VERSION ""

NS_ :

BS_:

BU_: LCU FRLCM FLLCM RghtRrLCMB RghtRrLCMA LftRrLCMB LftRrLCMA RghtFrntLCMB LftFrntLCMB TestTool AFL_AHL LftFrntLCMA RghtFrntLCMA
VAL_TABLE_ ALS_RghtALSCmdSts 2 "normal run" 1 "referece run" 0 "invalid" ;
VAL_TABLE_ LCU_LftALSCmdSts 2 "normal run" 1 "referece run" 0 "invalid" ;
VAL_TABLE_ WelShwSts 2 "welcome mode 2" 1 "welcome mode 1" 0 "no show" ;
VAL_TABLE_ LightShwSts 3 "light show mode 3" 2 "light show mode 2" 1 "light show mode 1" 0 "no show" ;
VAL_TABLE_ GFAVity 1 "present" 0 "not present" ;

BO_ 3221225472 VECTOR__INDEPENDENT_SIG_MSG: 0 Vector__XXX
 SG_ LftRCPlLed064 : 0|8@0+ (1,0) [0|0] "" Vector__XXX
 SG_ LftRCPlLed063 : 0|8@0+ (1,0) [0|0] "" Vector__XXX
 SG_ LftRCPlLed062 : 0|8@0+ (1,0) [0|0] "" Vector__XXX
 SG_ LftRCPlLed061 : 0|8@0+ (1,0) [0|0] "" Vector__XXX
 SG_ LftRCPlLed060 : 0|8@0+ (1,0) [0|0] "" Vector__XXX
 SG_ LftRCPlLed059 : 0|8@0+ (1,0) [0|0] "" Vector__XXX
 SG_ LftRCPlLed058 : 0|8@0+ (1,0) [0|0] "" Vector__XXX
 SG_ LftRCPlLed057 : 0|8@0+ (1,0) [0|0] "" Vector__XXX
 SG_ LftRCPlLed056 : 0|8@0+ (1,0) [0|0] "" Vector__XXX
 SG_ LftRCPlLed055 : 0|8@0+ (1,0) [0|0] "" Vector__XXX
 SG_ LftRCPlLed054 : 0|8@0+ (1,0) [0|0] "" Vector__XXX
 SG_ LftRCPlLed053 : 0|8@0+ (1,0) [0|0] "" Vector__XXX
 SG_ LftRCPlLed052 : 0|8@0+ (1,0) [0|0] "" Vector__XXX
 SG_ LftRCPlLed051 : 0|8@0+ (1,0) [0|0] "" Vector__XXX
 SG_ LftRCPlLed050 : 0|8@0+ (1,0) [0|0] "" Vector__XXX
 SG_ LftRCPlLed049 : 0|8@0+ (1,0) [0|0] "" Vector__XXX
 SG_ RghtRCPlLed033 : 0|8@0+ (1,0) [0|0] "" Vector__XXX
 SG_ RghtRCPlLed063 : 0|8@0+ (1,0) [0|0] "" Vector__XXX
 SG_ RghtRCPlLed061 : 0|8@0+ (1,0) [0|0] "" Vector__XXX
 SG_ RghtRCPlLed062 : 0|8@0+ (1,0) [0|0] "" Vector__XXX
 SG_ RghtRCPlLed060 : 0|8@0+ (1,0) [0|0] "" Vector__XXX
 SG_ RghtRCPlLed059 : 0|8@0+ (1,0) [0|0] "" Vector__XXX
 SG_ RghtRCPlLed057 : 0|8@0+ (1,0) [0|0] "" Vector__XXX
 SG_ RghtRCPlLed056 : 0|8@0+ (1,0) [0|0] "" Vector__XXX
 SG_ RghtRCPlLed055 : 0|8@0+ (1,0) [0|0] "" Vector__XXX
 SG_ RghtRCPlLed054 : 0|8@0+ (1,0) [0|0] "" Vector__XXX
 SG_ RghtRCPlLed053 : 0|8@0+ (1,0) [0|0] "" Vector__XXX
 SG_ RghtRCPlLed052 : 0|8@0+ (1,0) [0|0] "" Vector__XXX
 SG_ RghtRCPlLed051 : 0|8@0+ (1,0) [0|0] "" Vector__XXX
 SG_ RghtRCPlLed050 : 0|8@0+ (1,0) [0|0] "" Vector__XXX
 SG_ RghtRCPlLed049 : 0|8@0+ (1,0) [0|0] "" Vector__XXX
 SG_ RghtRCPlLed048 : 0|8@0+ (1,0) [0|0] "" Vector__XXX
 SG_ RghtRCPlLed046 : 0|8@0+ (1,0) [0|0] "" Vector__XXX
 SG_ RghtRCPlLed045 : 0|8@0+ (1,0) [0|0] "" Vector__XXX
 SG_ RghtRCPlLed044 : 0|8@0+ (1,0) [0|0] "" Vector__XXX
 SG_ RghtRCPlLed043 : 0|8@0+ (1,0) [0|0] "" Vector__XXX
 SG_ RghtRCPlLed042 : 0|8@0+ (1,0) [0|0] "" Vector__XXX
 SG_ RghtRCPlLed041 : 0|8@0+ (1,0) [0|0] "" Vector__XXX
 SG_ RghtRCPlLed040 : 0|8@0+ (1,0) [0|0] "" Vector__XXX
 SG_ RghtRCPlLed039 : 0|8@0+ (1,0) [0|0] "" Vector__XXX
 SG_ RghtRCPlLed038 : 0|8@0+ (1,0) [0|0] "" Vector__XXX
 SG_ RghtRCPlLed037 : 0|8@0+ (1,0) [0|0] "" Vector__XXX
 SG_ RghtRCPlLed035 : 0|8@0+ (1,0) [0|0] "" Vector__XXX
 SG_ RghtRCPlLed034 : 0|8@0+ (1,0) [0|0] "" Vector__XXX
 SG_ RghtRCPlLed032 : 0|8@0+ (1,0) [0|0] "" Vector__XXX
 SG_ RghtRCPlLed031 : 0|8@0+ (1,0) [0|0] "" Vector__XXX
 SG_ RghtRCPlLed030 : 0|8@0+ (1,0) [0|0] "" Vector__XXX
 SG_ RghtRCPlLed029 : 0|8@0+ (1,0) [0|0] "" Vector__XXX
 SG_ RghtRCPlLed028 : 0|8@0+ (1,0) [0|0] "" Vector__XXX
 SG_ RghtRCPlLed027 : 0|8@0+ (1,0) [0|0] "" Vector__XXX
 SG_ RghtRCPlLed026 : 0|8@0+ (1,0) [0|0] "" Vector__XXX
 SG_ RghtRCPlLed025 : 0|8@0+ (1,0) [0|0] "" Vector__XXX
 SG_ RghtRCPlLed023 : 0|8@0+ (1,0) [0|0] "" Vector__XXX
 SG_ RghtRCPlLed022 : 0|8@0+ (1,0) [0|0] "" Vector__XXX
 SG_ RghtRCPlLed021 : 0|8@0+ (1,0) [0|0] "" Vector__XXX
 SG_ RghtRCPlLed020 : 0|8@0+ (1,0) [0|0] "" Vector__XXX
 SG_ RghtRCPlLed019 : 0|8@0+ (1,0) [0|0] "" Vector__XXX
 SG_ RghtRCPlLed018 : 0|8@0+ (1,0) [0|0] "" Vector__XXX
 SG_ RghtRCPlLed017 : 0|8@0+ (1,0) [0|0] "" Vector__XXX
 SG_ RghtRCPlLed016 : 0|8@0+ (1,0) [0|0] "" Vector__XXX
 SG_ RghtRCPlLed015 : 0|8@0+ (1,0) [0|0] "" Vector__XXX
 SG_ RghtRCPlLed014 : 0|8@0+ (1,0) [0|0] "" Vector__XXX
 SG_ RghtRCPlLed012 : 0|8@0+ (1,0) [0|0] "" Vector__XXX
 SG_ RghtRCPlLed011 : 0|8@0+ (1,0) [0|0] "" Vector__XXX
 SG_ RghtRCPlLed010 : 0|8@0+ (1,0) [0|0] "" Vector__XXX
 SG_ RghtRCPlLed009 : 0|8@0+ (1,0) [0|0] "" Vector__XXX
 SG_ RghtRCPlLed008 : 0|8@0+ (1,0) [0|0] "" Vector__XXX
 SG_ RghtRCPlLed007 : 0|8@0+ (1,0) [0|0] "" Vector__XXX
 SG_ RghtRCPlLed006 : 0|8@0+ (1,0) [0|0] "" Vector__XXX
 SG_ RghtRCPlLed005 : 0|8@0+ (1,0) [0|0] "" Vector__XXX
 SG_ RghtRCPlLed004 : 0|8@0+ (1,0) [0|0] "" Vector__XXX
 SG_ RghtRCPlLed003 : 0|8@0+ (1,0) [0|0] "" Vector__XXX
 SG_ RghtRCPlLed064 : 0|8@0+ (1,0) [0|0] "" Vector__XXX
 SG_ RghtRCPlLed058 : 0|8@0+ (1,0) [0|0] "" Vector__XXX
 SG_ RghtRCPlLed047 : 0|8@0+ (1,0) [0|0] "" Vector__XXX
 SG_ RghtRCPlLed036 : 0|8@0+ (1,0) [0|0] "" Vector__XXX
 SG_ RghtRCPlLed024 : 0|8@0+ (1,0) [0|0] "" Vector__XXX
 SG_ RghtRCPlLed013 : 0|8@0+ (1,0) [0|0] "" Vector__XXX
 SG_ RghtRCPlLed002 : 0|8@0+ (1,0) [0|0] "" Vector__XXX
 SG_ RghtRCPlLed001 : 0|8@0+ (1,0) [0|0] "" Vector__XXX
 SG_ DiagRsp_RRLCMB : 0|64@0+ (1,0) [0|0] "" Vector__XXX
 SG_ DiagRsp_FRLCMB : 0|64@0+ (1,0) [0|0] "" Vector__XXX
 SG_ DiagRsp_FLLCMB : 0|64@0+ (1,0) [0|0] "" Vector__XXX
 SG_ DiagPhyReq_RRLCMB : 0|64@0+ (1,0) [0|1.84467440737096E+019] "" Vector__XXX
 SG_ DiagPhyReq_FRLCMB : 0|64@0+ (1,0) [0|1.84467440737096E+019] "" Vector__XXX
 SG_ DiagPhyReq_FLLCMB : 0|64@0+ (1,0) [0|1.84467440737096E+019] "" Vector__XXX
 SG_ NMData_RRLCMB : 0|64@0+ (1,0) [0|0] "" Vector__XXX
 SG_ NMData_FRLCMB : 0|64@0+ (1,0) [0|0] "" Vector__XXX
 SG_ NMData_FLLCMB : 0|64@0+ (1,0) [0|0] "" Vector__XXX
 SG_ LftRPlLed056 : 0|8@0+ (1,0) [0|0] "" Vector__XXX
 SG_ LftRPlLed055 : 0|8@0+ (1,0) [0|0] "" Vector__XXX
 SG_ LftRPlLed054 : 0|8@0+ (1,0) [0|0] "" Vector__XXX
 SG_ LftRPlLed053 : 0|8@0+ (1,0) [0|0] "" Vector__XXX
 SG_ LftRPlLed052 : 0|8@0+ (1,0) [0|0] "" Vector__XXX
 SG_ LftRPlLed051 : 0|8@0+ (1,0) [0|0] "" Vector__XXX
 SG_ LftRPlLed050 : 0|8@0+ (1,0) [0|0] "" Vector__XXX
 SG_ LftRPlLed049 : 0|8@0+ (1,0) [0|0] "" Vector__XXX
 SG_ LftRPlLed048 : 0|8@0+ (1,0) [0|0] "" Vector__XXX
 SG_ LftRPlLed047 : 0|8@0+ (1,0) [0|0] "" Vector__XXX
 SG_ LftRPlLed046 : 0|8@0+ (1,0) [0|0] "" Vector__XXX
 SG_ LftRPlLed045 : 0|8@0+ (1,0) [0|0] "" Vector__XXX
 SG_ LftRPlLed044 : 0|8@0+ (1,0) [0|0] "" Vector__XXX
 SG_ LftRPlLed043 : 0|8@0+ (1,0) [0|0] "" Vector__XXX
 SG_ LftRPlLed042 : 0|8@0+ (1,0) [0|0] "" Vector__XXX
 SG_ LftRPlLed041 : 0|8@0+ (1,0) [0|0] "" Vector__XXX
 SG_ LftRPlLed040 : 0|8@0+ (1,0) [0|0] "" Vector__XXX
 SG_ LftRPlLed039 : 0|8@0+ (1,0) [0|0] "" Vector__XXX
 SG_ LftRPlLed038 : 0|8@0+ (1,0) [0|0] "" Vector__XXX
 SG_ LftRPlLed037 : 0|8@0+ (1,0) [0|0] "" Vector__XXX
 SG_ LftRPlLed036 : 0|8@0+ (1,0) [0|0] "" Vector__XXX
 SG_ LftRPlLed035 : 0|8@0+ (1,0) [0|0] "" Vector__XXX
 SG_ LftRPlLed034 : 0|8@0+ (1,0) [0|0] "" Vector__XXX
 SG_ LftRPlLed033 : 0|8@0+ (1,0) [0|0] "" Vector__XXX
 SG_ RghtRPlLed064 : 0|8@0+ (1,0) [0|0] "" Vector__XXX
 SG_ RghtRPlLed063 : 0|8@0+ (1,0) [0|0] "" Vector__XXX
 SG_ RghtRPlLed062 : 0|8@0+ (1,0) [0|0] "" Vector__XXX
 SG_ RghtRPlLed061 : 0|8@0+ (1,0) [0|0] "" Vector__XXX
 SG_ RghtRPlLed060 : 0|8@0+ (1,0) [0|0] "" Vector__XXX
 SG_ RghtRPlLed059 : 0|8@0+ (1,0) [0|0] "" Vector__XXX
 SG_ RghtRPlLed058 : 0|8@0+ (1,0) [0|0] "" Vector__XXX
 SG_ RghtRPlLed057 : 0|8@0+ (1,0) [0|0] "" Vector__XXX
 SG_ RghtRPlLed056 : 0|8@0+ (1,0) [0|0] "" Vector__XXX
 SG_ RghtRPlLed055 : 0|8@0+ (1,0) [0|0] "" Vector__XXX
 SG_ RghtRPlLed054 : 0|8@0+ (1,0) [0|0] "" Vector__XXX
 SG_ RghtRPlLed053 : 0|8@0+ (1,0) [0|0] "" Vector__XXX
 SG_ RghtRPlLed052 : 0|8@0+ (1,0) [0|0] "" Vector__XXX
 SG_ RghtRPlLed051 : 0|8@0+ (1,0) [0|0] "" Vector__XXX
 SG_ RghtRPlLed050 : 0|8@0+ (1,0) [0|0] "" Vector__XXX
 SG_ RghtRPlLed049 : 0|8@0+ (1,0) [0|0] "" Vector__XXX
 SG_ RghtRPlLed048 : 0|8@0+ (1,0) [0|0] "" Vector__XXX
 SG_ RghtRPlLed047 : 0|8@0+ (1,0) [0|0] "" Vector__XXX
 SG_ RghtRPlLed046 : 0|8@0+ (1,0) [0|0] "" Vector__XXX
 SG_ RghtRPlLed045 : 0|8@0+ (1,0) [0|0] "" Vector__XXX
 SG_ RghtRPlLed044 : 0|8@0+ (1,0) [0|0] "" Vector__XXX
 SG_ RghtRPlLed043 : 0|8@0+ (1,0) [0|0] "" Vector__XXX
 SG_ RghtRPlLed042 : 0|8@0+ (1,0) [0|0] "" Vector__XXX
 SG_ RghtRPlLed041 : 0|8@0+ (1,0) [0|0] "" Vector__XXX
 SG_ RghtRPlLed040 : 0|8@0+ (1,0) [0|0] "" Vector__XXX
 SG_ RghtRPlLed039 : 0|8@0+ (1,0) [0|0] "" Vector__XXX
 SG_ RghtRPlLed038 : 0|8@0+ (1,0) [0|0] "" Vector__XXX
 SG_ RghtRPlLed037 : 0|8@0+ (1,0) [0|0] "" Vector__XXX
 SG_ RghtRPlLed036 : 0|8@0+ (1,0) [0|0] "" Vector__XXX
 SG_ RghtRPlLed035 : 0|8@0+ (1,0) [0|0] "" Vector__XXX
 SG_ RghtRPlLed034 : 0|8@0+ (1,0) [0|0] "" Vector__XXX
 SG_ RghtRPlLed033 : 0|8@0+ (1,0) [0|0] "" Vector__XXX
 SG_ LftRPlLed064 : 0|8@0+ (1,0) [0|0] "" Vector__XXX
 SG_ LftRPlLed063 : 0|8@0+ (1,0) [0|0] "" Vector__XXX
 SG_ LftRPlLed062 : 0|8@0+ (1,0) [0|0] "" Vector__XXX
 SG_ LftRPlLed061 : 0|8@0+ (1,0) [0|0] "" Vector__XXX
 SG_ LftRPlLed060 : 0|8@0+ (1,0) [0|0] "" Vector__XXX
 SG_ LftRPlLed059 : 0|8@0+ (1,0) [0|0] "" Vector__XXX
 SG_ LftRPlLed058 : 0|8@0+ (1,0) [0|0] "" Vector__XXX
 SG_ LftRPlLed057 : 0|8@0+ (1,0) [0|0] "" Vector__XXX
 SG_ RghtFCPlLed040 : 0|8@0+ (1,0) [0|0] "" Vector__XXX
 SG_ RghtFCPlLed039 : 0|8@0+ (1,0) [0|0] "" Vector__XXX
 SG_ RghtFCPlLed038 : 0|8@0+ (1,0) [0|0] "" Vector__XXX
 SG_ RghtFCPlLed037 : 0|8@0+ (1,0) [0|0] "" Vector__XXX
 SG_ RghtFCPlLed036 : 0|8@0+ (1,0) [0|0] "" Vector__XXX
 SG_ RghtFCPlLed035 : 0|8@0+ (1,0) [0|0] "" Vector__XXX
 SG_ RghtFCPlLed034 : 0|8@0+ (1,0) [0|0] "" Vector__XXX
 SG_ RghtFCPlLed033 : 0|8@0+ (1,0) [0|0] "" Vector__XXX
 SG_ RghtFCPlLed008 : 0|8@0+ (1,0) [0|0] "" Vector__XXX
 SG_ RghtFCPlLed007 : 0|8@0+ (1,0) [0|0] "" Vector__XXX
 SG_ RghtFCPlLed006 : 0|8@0+ (1,0) [0|0] "" Vector__XXX
 SG_ RghtFCPlLed005 : 0|8@0+ (1,0) [0|0] "" Vector__XXX
 SG_ RghtFCPlLed004 : 0|8@0+ (1,0) [0|0] "" Vector__XXX
 SG_ RghtFCPlLed003 : 0|8@0+ (1,0) [0|0] "" Vector__XXX
 SG_ RghtFCPlLed002 : 0|8@0+ (1,0) [0|0] "" Vector__XXX
 SG_ RghtFCPlLed001 : 0|8@0+ (1,0) [0|0] "" Vector__XXX
 SG_ LftFCPlLed040 : 0|8@0+ (1,0) [0|0] "" Vector__XXX
 SG_ LftFCPlLed039 : 0|8@0+ (1,0) [0|0] "" Vector__XXX
 SG_ LftFCPlLed038 : 0|8@0+ (1,0) [0|0] "" Vector__XXX
 SG_ LftFCPlLed037 : 0|8@0+ (1,0) [0|0] "" Vector__XXX
 SG_ LftFCPlLed036 : 0|8@0+ (1,0) [0|0] "" Vector__XXX
 SG_ LftFCPlLed035 : 0|8@0+ (1,0) [0|0] "" Vector__XXX
 SG_ LftFCPlLed034 : 0|8@0+ (1,0) [0|0] "" Vector__XXX
 SG_ LftFCPlLed033 : 0|8@0+ (1,0) [0|0] "" Vector__XXX
 SG_ LftFCPlLed024 : 0|8@0+ (1,0) [0|0] "" Vector__XXX
 SG_ LftFCPlLed023 : 0|8@0+ (1,0) [0|0] "" Vector__XXX
 SG_ LftFCPlLed022 : 0|8@0+ (1,0) [0|0] "" Vector__XXX
 SG_ LftFCPlLed021 : 0|8@0+ (1,0) [0|0] "" Vector__XXX
 SG_ LftFCPlLed020 : 0|8@0+ (1,0) [0|0] "" Vector__XXX
 SG_ LftFCPlLed019 : 0|8@0+ (1,0) [0|0] "" Vector__XXX
 SG_ LftFCPlLed018 : 0|8@0+ (1,0) [0|0] "" Vector__XXX
 SG_ LftFCPlLed017 : 0|8@0+ (1,0) [0|0] "" Vector__XXX
 SG_ RghtRTrnLed040 : 0|8@0+ (1,0) [0|0] "" Vector__XXX
 SG_ RghtRTrnLed039 : 0|8@0+ (1,0) [0|0] "" Vector__XXX
 SG_ RghtRTrnLed038 : 0|8@0+ (1,0) [0|0] "" Vector__XXX
 SG_ RghtRTrnLed037 : 0|8@0+ (1,0) [0|0] "" Vector__XXX
 SG_ RghtRTrnLed036 : 0|8@0+ (1,0) [0|0] "" Vector__XXX
 SG_ RghtRTrnLed035 : 0|8@0+ (1,0) [0|0] "" Vector__XXX
 SG_ RghtRTrnLed034 : 0|8@0+ (1,0) [0|0] "" Vector__XXX
 SG_ RghtRTrnLed033 : 0|8@0+ (1,0) [0|0] "" Vector__XXX
 SG_ LftRTrnLed040 : 0|8@0+ (1,0) [0|0] "" Vector__XXX
 SG_ LftRTrnLed039 : 0|8@0+ (1,0) [0|0] "" Vector__XXX
 SG_ LftRTrnLed038 : 0|8@0+ (1,0) [0|0] "" Vector__XXX
 SG_ LftRTrnLed037 : 0|8@0+ (1,0) [0|0] "" Vector__XXX
 SG_ LftRTrnLed036 : 0|8@0+ (1,0) [0|0] "" Vector__XXX
 SG_ LftRTrnLed035 : 0|8@0+ (1,0) [0|0] "" Vector__XXX
 SG_ LftRTrnLed034 : 0|8@0+ (1,0) [0|0] "" Vector__XXX
 SG_ LftRTrnLed033 : 0|8@0+ (1,0) [0|0] "" Vector__XXX
 SG_ RghtFTrnLed024 : 0|8@0+ (1,0) [0|0] "" Vector__XXX
 SG_ RghtFTrnLed023 : 0|8@0+ (1,0) [0|0] "" Vector__XXX
 SG_ RghtFTrnLed022 : 0|8@0+ (1,0) [0|0] "" Vector__XXX
 SG_ RghtFTrnLed021 : 0|8@0+ (1,0) [0|0] "" Vector__XXX
 SG_ RghtFTrnLed020 : 0|8@0+ (1,0) [0|0] "" Vector__XXX
 SG_ RghtFTrnLed019 : 0|8@0+ (1,0) [0|0] "" Vector__XXX
 SG_ RghtFTrnLed018 : 0|8@0+ (1,0) [0|0] "" Vector__XXX
 SG_ RghtFTrnLed017 : 0|8@0+ (1,0) [0|0] "" Vector__XXX
 SG_ LftFTrnLed024 : 0|8@0+ (1,0) [0|0] "" Vector__XXX
 SG_ LftFTrnLed023 : 0|8@0+ (1,0) [0|0] "" Vector__XXX
 SG_ LftFTrnLed022 : 0|8@0+ (1,0) [0|0] "" Vector__XXX
 SG_ LftFTrnLed021 : 0|8@0+ (1,0) [0|0] "" Vector__XXX
 SG_ LftFTrnLed020 : 0|8@0+ (1,0) [0|0] "" Vector__XXX
 SG_ LftFTrnLed019 : 0|8@0+ (1,0) [0|0] "" Vector__XXX
 SG_ LftFTrnLed018 : 0|8@0+ (1,0) [0|0] "" Vector__XXX
 SG_ LftFTrnLed017 : 0|8@0+ (1,0) [0|0] "" Vector__XXX
 SG_ RghtFCPlLed032 : 0|8@0+ (1,0) [0|0] "" Vector__XXX
 SG_ RghtFCPlLed031 : 0|8@0+ (1,0) [0|0] "" Vector__XXX
 SG_ RghtFCPlLed030 : 0|8@0+ (1,0) [0|0] "" Vector__XXX
 SG_ RghtFCPlLed029 : 0|8@0+ (1,0) [0|0] "" Vector__XXX
 SG_ RghtFCPlLed028 : 0|8@0+ (1,0) [0|0] "" Vector__XXX
 SG_ RghtFCPlLed027 : 0|8@0+ (1,0) [0|0] "" Vector__XXX
 SG_ RghtFCPlLed026 : 0|8@0+ (1,0) [0|0] "" Vector__XXX
 SG_ RghtFCPlLed025 : 0|8@0+ (1,0) [0|0] "" Vector__XXX
 SG_ RghtFCPlLed024 : 0|8@0+ (1,0) [0|0] "" Vector__XXX
 SG_ RghtFCPlLed023 : 0|8@0+ (1,0) [0|0] "" Vector__XXX
 SG_ RghtFCPlLed022 : 0|8@0+ (1,0) [0|0] "" Vector__XXX
 SG_ RghtFCPlLed021 : 0|8@0+ (1,0) [0|0] "" Vector__XXX
 SG_ RghtFCPlLed020 : 0|8@0+ (1,0) [0|0] "" Vector__XXX
 SG_ RghtFCPlLed019 : 0|8@0+ (1,0) [0|0] "" Vector__XXX
 SG_ RghtFCPlLed018 : 0|8@0+ (1,0) [0|0] "" Vector__XXX
 SG_ RghtFCPlLed017 : 0|8@0+ (1,0) [0|0] "" Vector__XXX
 SG_ RghtFCPlLed016 : 0|8@0+ (1,0) [0|0] "" Vector__XXX
 SG_ RghtFCPlLed015 : 0|8@0+ (1,0) [0|0] "" Vector__XXX
 SG_ RghtFCPlLed014 : 0|8@0+ (1,0) [0|0] "" Vector__XXX
 SG_ RghtFCPlLed013 : 0|8@0+ (1,0) [0|0] "" Vector__XXX
 SG_ RghtFCPlLed012 : 0|8@0+ (1,0) [0|0] "" Vector__XXX
 SG_ RghtFCPlLed011 : 0|8@0+ (1,0) [0|0] "" Vector__XXX
 SG_ RghtFCPlLed010 : 0|8@0+ (1,0) [0|0] "" Vector__XXX
 SG_ RghtFCPlLed009 : 0|8@0+ (1,0) [0|0] "" Vector__XXX
 SG_ LftFCPlLed032 : 0|8@0+ (1,0) [0|0] "" Vector__XXX
 SG_ LftFCPlLed031 : 0|8@0+ (1,0) [0|0] "" Vector__XXX
 SG_ LftFCPlLed030 : 0|8@0+ (1,0) [0|0] "" Vector__XXX
 SG_ LftFCPlLed029 : 0|8@0+ (1,0) [0|0] "" Vector__XXX
 SG_ LftFCPlLed028 : 0|8@0+ (1,0) [0|0] "" Vector__XXX
 SG_ LftFCPlLed027 : 0|8@0+ (1,0) [0|0] "" Vector__XXX
 SG_ LftFCPlLed026 : 0|8@0+ (1,0) [0|0] "" Vector__XXX
 SG_ LftFCPlLed025 : 0|8@0+ (1,0) [0|0] "" Vector__XXX
 SG_ LftHbLed024 : 0|8@0+ (1,0) [0|0] "" Vector__XXX
 SG_ LftHbLed023 : 0|8@0+ (1,0) [0|0] "" Vector__XXX
 SG_ LftHbLed022 : 0|8@0+ (1,0) [0|0] "" Vector__XXX
 SG_ LftHbLed021 : 0|8@0+ (1,0) [0|0] "" Vector__XXX
 SG_ LftHbLed020 : 0|8@0+ (1,0) [0|0] "" Vector__XXX
 SG_ LftHbLed019 : 0|8@0+ (1,0) [0|0] "" Vector__XXX
 SG_ LftHbLed018 : 0|8@0+ (1,0) [0|0] "" Vector__XXX
 SG_ LftHbLed017 : 0|8@0+ (1,0) [0|0] "" Vector__XXX
 SG_ RghtHbLed024 : 0|8@0+ (1,0) [0|0] "" Vector__XXX
 SG_ RghtHbLed023 : 0|8@0+ (1,0) [0|0] "" Vector__XXX
 SG_ RghtHbLed022 : 0|8@0+ (1,0) [0|0] "" Vector__XXX
 SG_ RghtHbLed021 : 0|8@0+ (1,0) [0|0] "" Vector__XXX
 SG_ RghtHbLed020 : 0|8@0+ (1,0) [0|0] "" Vector__XXX
 SG_ RghtHbLed019 : 0|8@0+ (1,0) [0|0] "" Vector__XXX
 SG_ RghtHbLed018 : 0|8@0+ (1,0) [0|0] "" Vector__XXX
 SG_ RghtHbLed017 : 0|8@0+ (1,0) [0|0] "" Vector__XXX
 SG_ LftFTrnLed016 : 0|8@0+ (1,0) [0|0] "" Vector__XXX
 SG_ LftFTrnLed015 : 0|8@0+ (1,0) [0|0] "" Vector__XXX
 SG_ LftFTrnLed014 : 0|8@0+ (1,0) [0|0] "" Vector__XXX
 SG_ LftFTrnLed013 : 0|8@0+ (1,0) [0|0] "" Vector__XXX
 SG_ LftFTrnLed012 : 0|8@0+ (1,0) [0|0] "" Vector__XXX
 SG_ LftFTrnLed011 : 0|8@0+ (1,0) [0|0] "" Vector__XXX
 SG_ LftFTrnLed010 : 0|8@0+ (1,0) [0|0] "" Vector__XXX
 SG_ LftFTrnLed009 : 0|8@0+ (1,0) [0|0] "" Vector__XXX
 SG_ RghtFTrnLed016 : 0|8@0+ (1,0) [0|0] "" Vector__XXX
 SG_ RghtFTrnLed015 : 0|8@0+ (1,0) [0|0] "" Vector__XXX
 SG_ RghtFTrnLed014 : 0|8@0+ (1,0) [0|0] "" Vector__XXX
 SG_ RghtFTrnLed013 : 0|8@0+ (1,0) [0|0] "" Vector__XXX
 SG_ RghtFTrnLed012 : 0|8@0+ (1,0) [0|0] "" Vector__XXX
 SG_ RghtFTrnLed011 : 0|8@0+ (1,0) [0|0] "" Vector__XXX
 SG_ RghtFTrnLed010 : 0|8@0+ (1,0) [0|0] "" Vector__XXX
 SG_ RghtFTrnLed009 : 0|8@0+ (1,0) [0|0] "" Vector__XXX
 SG_ LftFCPlLed008 : 0|8@0+ (1,0) [0|0] "" Vector__XXX
 SG_ LftFCPlLed007 : 0|8@0+ (1,0) [0|0] "" Vector__XXX
 SG_ LftFCPlLed006 : 0|8@0+ (1,0) [0|0] "" Vector__XXX
 SG_ LftFCPlLed005 : 0|8@0+ (1,0) [0|0] "" Vector__XXX
 SG_ LftFCPlLed004 : 0|8@0+ (1,0) [0|0] "" Vector__XXX
 SG_ LftFCPlLed003 : 0|8@0+ (1,0) [0|0] "" Vector__XXX
 SG_ LftFCPlLed002 : 0|8@0+ (1,0) [0|0] "" Vector__XXX
 SG_ LftFCPlLed001 : 0|8@0+ (1,0) [0|0] "" Vector__XXX
 SG_ LftFCPlLed016 : 0|8@0+ (1,0) [0|0] "" Vector__XXX
 SG_ LftFCPlLed015 : 0|8@0+ (1,0) [0|0] "" Vector__XXX
 SG_ LftFCPlLed014 : 0|8@0+ (1,0) [0|0] "" Vector__XXX
 SG_ LftFCPlLed013 : 0|8@0+ (1,0) [0|0] "" Vector__XXX
 SG_ LftFCPlLed012 : 0|8@0+ (1,0) [0|0] "" Vector__XXX
 SG_ LftFCPlLed011 : 0|8@0+ (1,0) [0|0] "" Vector__XXX
 SG_ LftFCPlLed010 : 0|8@0+ (1,0) [0|0] "" Vector__XXX
 SG_ LftFCPlLed009 : 0|8@0+ (1,0) [0|0] "" Vector__XXX
 SG_ RghtFTrnLed008 : 0|8@0+ (1,0) [0|0] "" Vector__XXX
 SG_ RghtFTrnLed007 : 0|8@0+ (1,0) [0|0] "" Vector__XXX
 SG_ RghtFTrnLed006 : 0|8@0+ (1,0) [0|0] "" Vector__XXX
 SG_ RghtFTrnLed005 : 0|8@0+ (1,0) [0|0] "" Vector__XXX
 SG_ RghtFTrnLed004 : 0|8@0+ (1,0) [0|0] "" Vector__XXX
 SG_ RghtFTrnLed003 : 0|8@0+ (1,0) [0|0] "" Vector__XXX
 SG_ RghtDrlLed056 : 0|8@0+ (1,0) [0|0] "" Vector__XXX
 SG_ RghtDrlLed055 : 0|8@0+ (1,0) [0|0] "" Vector__XXX
 SG_ RghtDrlLed054 : 0|8@0+ (1,0) [0|0] "" Vector__XXX
 SG_ RghtDrlLed053 : 0|8@0+ (1,0) [0|0] "" Vector__XXX
 SG_ RghtDrlLed052 : 0|8@0+ (1,0) [0|0] "" Vector__XXX
 SG_ RghtDrlLed051 : 0|8@0+ (1,0) [0|0] "" Vector__XXX
 SG_ RghtDhlSts : 0|2@0+ (1,0) [0|1] "" Vector__XXX
 SG_ RghtDhlPosAct : 0|10@0+ (1,0) [0|0] "" Vector__XXX
 SG_ LampErr_FRLCMA : 0|16@0+ (1,0) [0|0] "" Vector__XXX
 SG_ LftDhlSts : 0|2@0+ (1,0) [0|1] "" Vector__XXX
 SG_ LftDhlPosAct : 0|10@0+ (1,0) [0|0] "" Vector__XXX
 SG_ LampErr_FLLCMA : 0|16@0+ (1,0) [0|0] "" Vector__XXX
 SG_ SysSts_FLLCMA : 0|64@0+ (1,0) [0|0] "" Vector__XXX
 SG_ EngSt : 0|1@0+ (1,0) [0|0] "" Vector__XXX
 SG_ EngCrankSt : 0|1@0+ (1,0) [0|0] "" Vector__XXX
 SG_ KeySt : 0|2@0+ (1,0) [0|0] "" Vector__XXX
 SG_ LcuCmd_ShwCmd : 0|8@0+ (1,0) [0|0] "" Vector__XXX
 SG_ LcuCmd_LampCmd : 0|24@0+ (1,0) [0|0] "" Vector__XXX

BO_ 3 New_Message_87: 8 Vector__XXX
 SG_ New_Signal_729 : 48|8@1+ (1,0) [0|0] "" Vector__XXX

BO_ 2 New_Message_86: 8 Vector__XXX
 SG_ New_Signal_728 : 56|8@1+ (1,0) [0|0] "" Vector__XXX

BO_ 1 New_Message_85: 8 Vector__XXX
 SG_ New_Signal_727 : 24|8@1+ (1,0) [0|0] "" Vector__XXX

BO_ 0 New_Message_84: 8 Vector__XXX
 SG_ New_Signal_726 : 16|8@1+ (1,0) [0|0] "" Vector__XXX

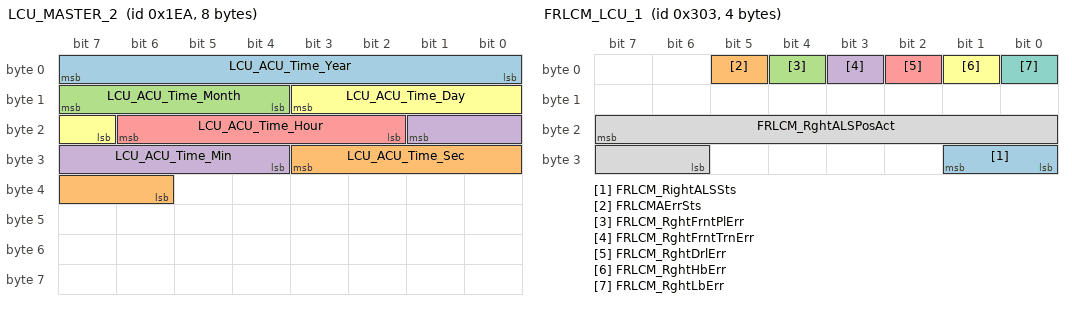
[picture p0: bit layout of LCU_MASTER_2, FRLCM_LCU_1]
BO_ 490 LCU_MASTER_2: 8 AFL_AHL
 SG_ LCU_ACU_Time_Year : 7|8@0+ (1,2000) [2000|2255] ""  RghtRrLCMB,RghtRrLCMA,LftRrLCMA,RghtFrntLCMA,RghtFrntLCMB,LftRrLCMB,LftFrntLCMB,LftFrntLCMA
 SG_ LCU_ACU_Time_Sec : 27|6@0+ (1,0) [0|59] ""  RghtRrLCMB,RghtRrLCMA,LftRrLCMA,RghtFrntLCMA,RghtFrntLCMB,LftRrLCMB,LftFrntLCMB,LftFrntLCMA
 SG_ LCU_ACU_Time_Month : 15|4@0+ (1,0) [1|12] ""  RghtRrLCMB,RghtRrLCMA,LftRrLCMA,RghtFrntLCMA,RghtFrntLCMB,LftRrLCMB,LftFrntLCMB,LftFrntLCMA
 SG_ LCU_ACU_Time_Min : 17|6@0+ (1,0) [0|59] ""  RghtRrLCMB,RghtRrLCMA,LftRrLCMA,RghtFrntLCMA,RghtFrntLCMB,LftRrLCMB,LftFrntLCMB,LftFrntLCMA
 SG_ LCU_ACU_Time_Hour : 22|5@0+ (1,0) [0|23] ""  RghtRrLCMB,RghtRrLCMA,LftRrLCMA,RghtFrntLCMA,RghtFrntLCMB,LftRrLCMB,LftFrntLCMB,LftFrntLCMA
 SG_ LCU_ACU_Time_Day : 11|5@0+ (1,0) [1|31] ""  RghtRrLCMB,RghtRrLCMA,LftRrLCMA,RghtFrntLCMA,RghtFrntLCMB,LftRrLCMB,LftFrntLCMB,LftFrntLCMA

BO_ 1396 Nm_RLLCMB: 8 LftRrLCMB
 SG_ NMData_RLLCMB : 7|64@0+ (1,0) [0|0] ""  AFL_AHL

BO_ 1371 Nm_RRLCMA: 8 RghtRrLCMA
 SG_ NMData_RRLCMA : 7|64@0+ (1,0) [0|0] ""  AFL_AHL

BO_ 1358 Nm_RLLCMA: 8 LftRrLCMA
 SG_ NMData_RLLCMA : 7|64@0+ (1,0) [0|0] ""  AFL_AHL

BO_ 1330 Nm_FRLCMA: 8 RghtFrntLCMA
 SG_ NMData_FRLCMA : 7|64@0+ (1,0) [0|0] ""  AFL_AHL

BO_ 1313 Nm_FLLCMA: 8 LftFrntLCMA
 SG_ NMData_FLLCMA : 7|64@0+ (1,0) [0|0] ""  AFL_AHL

BO_ 1359 Nm_LCU: 8 AFL_AHL
 SG_ NMData_LCU : 7|64@0+ (1,0) [0|0] ""  RghtRrLCMB,RghtRrLCMA,RghtFrntLCMB,LftRrLCMB,LftRrLCMA,LftFrntLCMB,RghtFrntLCMA,LftFrntLCMA

BO_ 776 RRLCMBLampSts: 2 RghtRrLCMB
 SG_ LampErr_RRLCMB : 7|16@0+ (1,0) [0|0] ""  AFL_AHL

BO_ 774 RRLCMALampSts: 2 RghtRrLCMA
 SG_ LampErr_RRLCMA : 7|16@0+ (1,0) [0|0] ""  AFL_AHL

BO_ 775 RLLCMBLampSts: 2 LftRrLCMB
 SG_ LampErr_RLLCMB : 7|16@0+ (1,0) [0|0] ""  AFL_AHL

BO_ 773 RLLCMALampSts: 2 LftRrLCMA
 SG_ LampErr_RLLCMA : 7|16@0+ (1,0) [0|0] ""  AFL_AHL

BO_ 772 FRLCMBLampSts: 2 RghtFrntLCMB
 SG_ LampErr_FRLCMB : 7|16@0+ (1,0) [0|0] ""  AFL_AHL

BO_ 771 FRLCM_LCU_1: 4 RghtFrntLCMA
 SG_ FRLCM_RightALSSts : 25|2@0+ (1,0) [0|3] ""  LCU
 SG_ FRLCMAErrSts : 5|1@0+ (1,0) [0|1] ""  LCU
 SG_ FRLCM_RghtFrntPlErr : 4|1@0+ (1,0) [0|1] ""  LCU
 SG_ FRLCM_RghtFrntTrnErr : 3|1@0+ (1,0) [0|1] ""  LCU
 SG_ FRLCM_RghtDrlErr : 2|1@0+ (1,0) [0|1] ""  LCU
 SG_ FRLCM_RghtHbErr : 1|1@0+ (1,0) [0|1] ""  LCU
 SG_ FRLCM_RghtLbErr : 0|1@0+ (1,0) [0|1] ""  LCU
 SG_ FRLCM_RghtALSPosAct : 23|10@0+ (1,0) [0|1024] ""  LCU

BO_ 770 FLLCMBLampSts: 2 LftFrntLCMB
 SG_ LampErr_FLLCMB : 7|16@0+ (1,0) [0|0] ""  AFL_AHL

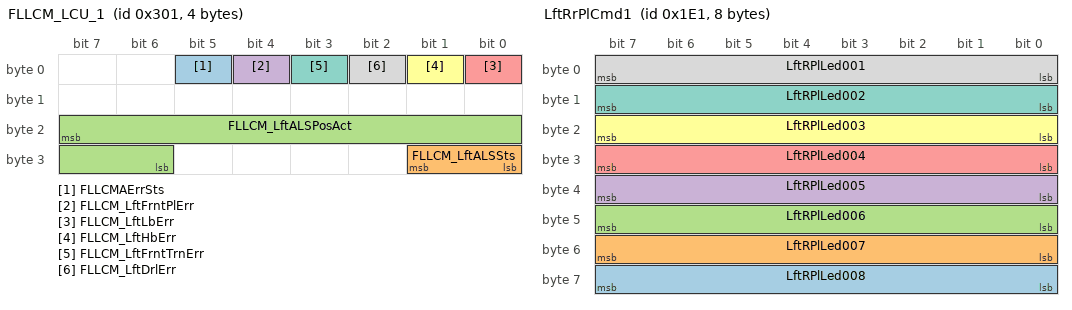
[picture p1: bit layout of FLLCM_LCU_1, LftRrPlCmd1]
BO_ 769 FLLCM_LCU_1: 4 LftFrntLCMA
 SG_ FLLCMAErrSts : 5|1@0+ (1,0) [0|1] ""  LCU
 SG_ FLLCM_LftALSSts : 25|2@0+ (1,0) [0|3] ""  LCU
 SG_ FLLCM_LftALSPosAct : 23|10@0+ (1,0) [0|1023] ""  LCU
 SG_ FLLCM_LftFrntPlErr : 4|1@0+ (1,0) [0|1] ""  LCU
 SG_ FLLCM_LftLbErr : 0|1@0+ (1,0) [0|1] ""  LCU
 SG_ FLLCM_LftHbErr : 1|1@0+ (1,0) [0|1] ""  LCU
 SG_ FLLCM_LftFrntTrnErr : 3|1@0+ (1,0) [0|1] ""  LCU
 SG_ FLLCM_LftDrlErr : 2|1@0+ (1,0) [0|1] ""  LCU

BO_ 489 LCU_MASTER_1: 8 AFL_AHL
 SG_ LCU_LftFrntPlSts : 15|2@0+ (1,0) [0|2] "" Vector__XXX
 SG_ LCU_LftTrnSts : 8|1@0+ (1,0) [0|1] "" Vector__XXX
 SG_ LCU_EMS_EngCrankSt : 51|1@0+ (1,0) [0|1] "" Vector__XXX
 SG_ LCU_EMS_EngSt : 50|1@0+ (1,0) [0|1] "" Vector__XXX
 SG_ LCU_BCM_KeySt : 49|2@0+ (1,0) [0|2] "" Vector__XXX
 SG_ LCU_BCS_VehSpdVD : 37|1@0+ (1,0) [0|1] "" Vector__XXX
 SG_ LCU_Fan2Cmd : 27|1@0+ (1,0) [0|1] "" Vector__XXX
 SG_ LCU_Fan1Cmd : 26|1@0+ (1,0) [0|1] "" Vector__XXX
 SG_ LCU_RrFogSts : 25|1@0+ (1,0) [0|1] "" Vector__XXX
 SG_ LCU_StopSts : 24|1@0+ (1,0) [0|1] "" Vector__XXX
 SG_ LCU_FrntFogSts : 23|1@0+ (1,0) [0|1] "" Vector__XXX
 SG_ LCU_LbSts : 20|1@0+ (1,0) [0|1] "" Vector__XXX
 SG_ LCU_HbSts : 22|2@0+ (1,0) [0|2] "" Vector__XXX
 SG_ LCU_RghtRrPlSts : 19|1@0+ (1,0) [0|1] "" Vector__XXX
 SG_ LCU_LftRrPlSts : 18|1@0+ (1,0) [0|1] "" Vector__XXX
 SG_ LCU_RghtFrntPlSts : 17|2@0+ (1,0) [0|2] "" Vector__XXX
 SG_ LCU_RghtDrlSts : 13|1@0+ (1,0) [0|1] "" Vector__XXX
 SG_ LCU_LftDrlSts : 12|1@0+ (1,0) [0|1] "" Vector__XXX
 SG_ LCU_RghtTrnSts : 9|1@0+ (1,0) [0|1] "" Vector__XXX
 SG_ LCU_WelShwSts : 7|4@0+ (1,0) [0|15] "" Vector__XXX
 SG_ LCU_LightShwSts : 3|4@0+ (1,0) [0|15] "" Vector__XXX
 SG_ LCU_BCS_VehSpd : 36|13@0+ (1,0) [0|8191] ""  RghtRrLCMA,RghtFrntLCMB,RghtFrntLCMA,LftRrLCMB,LftRrLCMA,LftFrntLCMB,LftFrntLCMA

BO_ 1916 DiagResp_LftRrB: 8 LftRrLCMB
 SG_ DiagRsp_RLLCMB : 7|64@0+ (1,0) [0|0] ""  TestTool

BO_ 2011 DiagResp_RghtRrA: 8 RghtRrLCMA
 SG_ DiagRsp_RRLCMA : 7|64@0+ (1,0) [0|0] ""  TestTool

BO_ 1998 DiagResp_LftRrA: 8 LftRrLCMA
 SG_ DiagRsp_RLLCMA : 7|64@0+ (1,0) [0|0] ""  TestTool

BO_ 1908 PhyDiagReq_LftRrB: 8 TestTool
 SG_ DiagPhyReq_RLLCMB : 7|64@0+ (1,0) [0|1.84467440737096E+019] ""  LftRrLCMB

BO_ 1883 PhyDiagReq_RghtRrA: 8 TestTool
 SG_ DiagPhyReq_RRLCMA : 7|64@0+ (1,0) [0|1.84467440737096E+019] ""  RghtRrLCMA

BO_ 1870 PhyDiagReq_LftRrA: 8 TestTool
 SG_ DiagPhyReq_RLLCMA : 7|64@0+ (1,0) [0|1.84467440737096E+019] ""  LftRrLCMA

BO_ 481 LftRrPlCmd1: 8 AFL_AHL
 SG_ LftRPlLed008 : 63|8@0+ (1,0) [0|0] ""  LftRrLCMA
 SG_ LftRPlLed007 : 55|8@0+ (1,0) [0|0] ""  LftRrLCMA
 SG_ LftRPlLed006 : 47|8@0+ (1,0) [0|0] ""  LftRrLCMA
 SG_ LftRPlLed005 : 39|8@0+ (1,0) [0|0] ""  LftRrLCMA
 SG_ LftRPlLed004 : 31|8@0+ (1,0) [0|0] ""  LftRrLCMA
 SG_ LftRPlLed003 : 23|8@0+ (1,0) [0|0] ""  LftRrLCMA
 SG_ LftRPlLed002 : 15|8@0+ (1,0) [0|0] ""  LftRrLCMA
 SG_ LftRPlLed001 : 7|8@0+ (1,0) [0|0] ""  LftRrLCMA

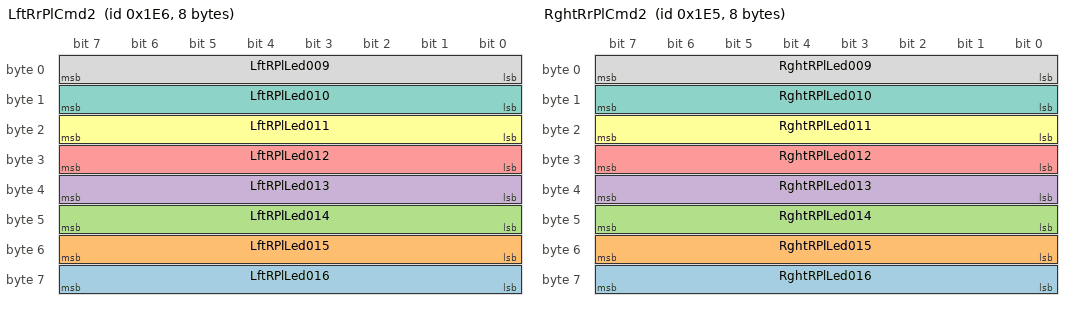
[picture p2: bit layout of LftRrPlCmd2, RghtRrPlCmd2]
BO_ 486 LftRrPlCmd2: 8 AFL_AHL
 SG_ LftRPlLed016 : 63|8@0+ (1,0) [0|0] ""  LftRrLCMA
 SG_ LftRPlLed015 : 55|8@0+ (1,0) [0|0] ""  LftRrLCMA
 SG_ LftRPlLed014 : 47|8@0+ (1,0) [0|0] ""  LftRrLCMA
 SG_ LftRPlLed013 : 39|8@0+ (1,0) [0|0] ""  LftRrLCMA
 SG_ LftRPlLed012 : 31|8@0+ (1,0) [0|0] ""  LftRrLCMA
 SG_ LftRPlLed011 : 23|8@0+ (1,0) [0|0] ""  LftRrLCMA
 SG_ LftRPlLed010 : 15|8@0+ (1,0) [0|0] ""  LftRrLCMA
 SG_ LftRPlLed009 : 7|8@0+ (1,0) [0|0] ""  LftRrLCMA

BO_ 485 RghtRrPlCmd2: 8 AFL_AHL
 SG_ RghtRPlLed016 : 63|8@0+ (1,0) [0|0] ""  RghtRrLCMA
 SG_ RghtRPlLed015 : 55|8@0+ (1,0) [0|0] ""  RghtRrLCMA
 SG_ RghtRPlLed014 : 47|8@0+ (1,0) [0|0] ""  RghtRrLCMA
 SG_ RghtRPlLed013 : 39|8@0+ (1,0) [0|0] ""  RghtRrLCMA
 SG_ RghtRPlLed012 : 31|8@0+ (1,0) [0|0] ""  RghtRrLCMA
 SG_ RghtRPlLed011 : 23|8@0+ (1,0) [0|0] ""  RghtRrLCMA
 SG_ RghtRPlLed010 : 15|8@0+ (1,0) [0|0] ""  RghtRrLCMA
 SG_ RghtRPlLed009 : 7|8@0+ (1,0) [0|0] ""  RghtRrLCMA

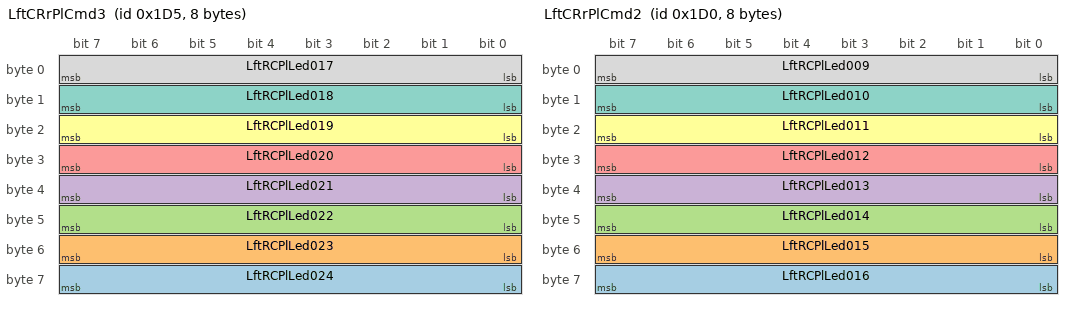
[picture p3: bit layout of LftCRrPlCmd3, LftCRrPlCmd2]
BO_ 469 LftCRrPlCmd3: 8 AFL_AHL
 SG_ LftRCPlLed024 : 63|8@0+ (1,0) [0|0] ""  LftRrLCMB
 SG_ LftRCPlLed023 : 55|8@0+ (1,0) [0|0] ""  LftRrLCMB
 SG_ LftRCPlLed022 : 47|8@0+ (1,0) [0|0] ""  LftRrLCMB
 SG_ LftRCPlLed021 : 39|8@0+ (1,0) [0|0] ""  LftRrLCMB
 SG_ LftRCPlLed020 : 31|8@0+ (1,0) [0|0] ""  LftRrLCMB
 SG_ LftRCPlLed019 : 23|8@0+ (1,0) [0|0] ""  LftRrLCMB
 SG_ LftRCPlLed018 : 15|8@0+ (1,0) [0|0] ""  LftRrLCMB
 SG_ LftRCPlLed017 : 7|8@0+ (1,0) [0|0] ""  LftRrLCMB

BO_ 464 LftCRrPlCmd2: 8 AFL_AHL
 SG_ LftRCPlLed016 : 63|8@0+ (1,0) [0|0] ""  LftRrLCMB
 SG_ LftRCPlLed015 : 55|8@0+ (1,0) [0|0] ""  LftRrLCMB
 SG_ LftRCPlLed014 : 47|8@0+ (1,0) [0|0] ""  LftRrLCMB
 SG_ LftRCPlLed013 : 39|8@0+ (1,0) [0|0] ""  LftRrLCMB
 SG_ LftRCPlLed012 : 31|8@0+ (1,0) [0|0] ""  LftRrLCMB
 SG_ LftRCPlLed011 : 23|8@0+ (1,0) [0|0] ""  LftRrLCMB
 SG_ LftRCPlLed010 : 15|8@0+ (1,0) [0|0] ""  LftRrLCMB
 SG_ LftRCPlLed009 : 7|8@0+ (1,0) [0|0] ""  LftRrLCMB

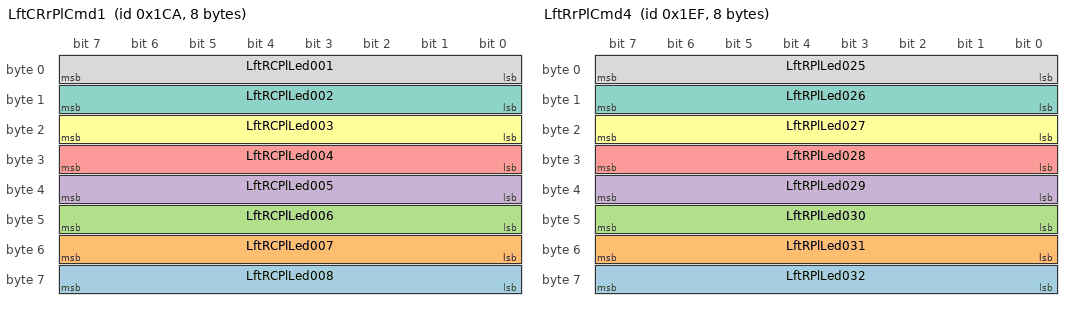
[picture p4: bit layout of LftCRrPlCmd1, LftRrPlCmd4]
BO_ 458 LftCRrPlCmd1: 8 AFL_AHL
 SG_ LftRCPlLed008 : 63|8@0+ (1,0) [0|0] ""  LftRrLCMB
 SG_ LftRCPlLed007 : 55|8@0+ (1,0) [0|0] ""  LftRrLCMB
 SG_ LftRCPlLed006 : 47|8@0+ (1,0) [0|0] ""  LftRrLCMB
 SG_ LftRCPlLed005 : 39|8@0+ (1,0) [0|0] ""  LftRrLCMB
 SG_ LftRCPlLed004 : 31|8@0+ (1,0) [0|0] ""  LftRrLCMB
 SG_ LftRCPlLed003 : 23|8@0+ (1,0) [0|0] ""  LftRrLCMB
 SG_ LftRCPlLed002 : 15|8@0+ (1,0) [0|0] ""  LftRrLCMB
 SG_ LftRCPlLed001 : 7|8@0+ (1,0) [0|0] ""  LftRrLCMB

BO_ 495 LftRrPlCmd4: 8 AFL_AHL
 SG_ LftRPlLed032 : 63|8@0+ (1,0) [0|0] ""  LftRrLCMA
 SG_ LftRPlLed031 : 55|8@0+ (1,0) [0|0] ""  LftRrLCMA
 SG_ LftRPlLed030 : 47|8@0+ (1,0) [0|0] ""  LftRrLCMA
 SG_ LftRPlLed029 : 39|8@0+ (1,0) [0|0] ""  LftRrLCMA
 SG_ LftRPlLed028 : 31|8@0+ (1,0) [0|0] ""  LftRrLCMA
 SG_ LftRPlLed027 : 23|8@0+ (1,0) [0|0] ""  LftRrLCMA
 SG_ LftRPlLed026 : 15|8@0+ (1,0) [0|0] ""  LftRrLCMA
 SG_ LftRPlLed025 : 7|8@0+ (1,0) [0|0] ""  LftRrLCMA

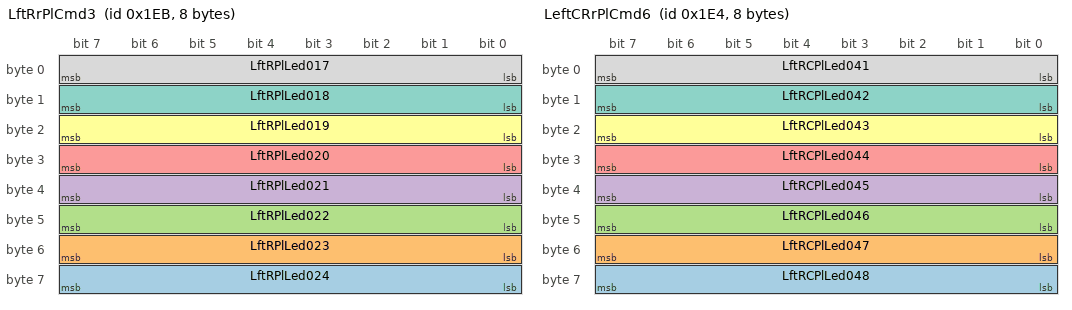
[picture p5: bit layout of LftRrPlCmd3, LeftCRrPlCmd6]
BO_ 491 LftRrPlCmd3: 8 AFL_AHL
 SG_ LftRPlLed024 : 63|8@0+ (1,0) [0|0] ""  LftRrLCMA
 SG_ LftRPlLed023 : 55|8@0+ (1,0) [0|0] ""  LftRrLCMA
 SG_ LftRPlLed022 : 47|8@0+ (1,0) [0|0] ""  LftRrLCMA
 SG_ LftRPlLed021 : 39|8@0+ (1,0) [0|0] ""  LftRrLCMA
 SG_ LftRPlLed020 : 31|8@0+ (1,0) [0|0] ""  LftRrLCMA
 SG_ LftRPlLed019 : 23|8@0+ (1,0) [0|0] ""  LftRrLCMA
 SG_ LftRPlLed018 : 15|8@0+ (1,0) [0|0] ""  LftRrLCMA
 SG_ LftRPlLed017 : 7|8@0+ (1,0) [0|0] ""  LftRrLCMA

BO_ 484 LeftCRrPlCmd6: 8 AFL_AHL
 SG_ LftRCPlLed048 : 63|8@0+ (1,0) [0|0] ""  LftRrLCMB
 SG_ LftRCPlLed047 : 55|8@0+ (1,0) [0|0] ""  LftRrLCMB
 SG_ LftRCPlLed046 : 47|8@0+ (1,0) [0|0] ""  LftRrLCMB
 SG_ LftRCPlLed045 : 39|8@0+ (1,0) [0|0] ""  LftRrLCMB
 SG_ LftRCPlLed044 : 31|8@0+ (1,0) [0|0] ""  LftRrLCMB
 SG_ LftRCPlLed043 : 23|8@0+ (1,0) [0|0] ""  LftRrLCMB
 SG_ LftRCPlLed042 : 15|8@0+ (1,0) [0|0] ""  LftRrLCMB
 SG_ LftRCPlLed041 : 7|8@0+ (1,0) [0|0] ""  LftRrLCMB

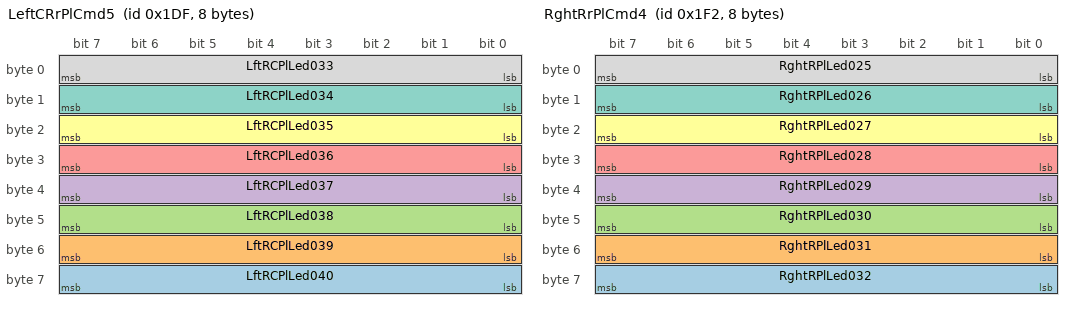
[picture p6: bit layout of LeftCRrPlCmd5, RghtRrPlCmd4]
BO_ 479 LeftCRrPlCmd5: 8 AFL_AHL
 SG_ LftRCPlLed040 : 63|8@0+ (1,0) [0|0] ""  LftRrLCMB
 SG_ LftRCPlLed039 : 55|8@0+ (1,0) [0|0] ""  LftRrLCMB
 SG_ LftRCPlLed038 : 47|8@0+ (1,0) [0|0] ""  LftRrLCMB
 SG_ LftRCPlLed037 : 39|8@0+ (1,0) [0|0] ""  LftRrLCMB
 SG_ LftRCPlLed036 : 31|8@0+ (1,0) [0|0] ""  LftRrLCMB
 SG_ LftRCPlLed035 : 23|8@0+ (1,0) [0|0] ""  LftRrLCMB
 SG_ LftRCPlLed034 : 15|8@0+ (1,0) [0|0] ""  LftRrLCMB
 SG_ LftRCPlLed033 : 7|8@0+ (1,0) [0|0] ""  LftRrLCMB

BO_ 498 RghtRrPlCmd4: 8 AFL_AHL
 SG_ RghtRPlLed032 : 63|8@0+ (1,0) [0|0] ""  RghtRrLCMA
 SG_ RghtRPlLed031 : 55|8@0+ (1,0) [0|0] ""  RghtRrLCMA
 SG_ RghtRPlLed030 : 47|8@0+ (1,0) [0|0] ""  RghtRrLCMA
 SG_ RghtRPlLed029 : 39|8@0+ (1,0) [0|0] ""  RghtRrLCMA
 SG_ RghtRPlLed028 : 31|8@0+ (1,0) [0|0] ""  RghtRrLCMA
 SG_ RghtRPlLed027 : 23|8@0+ (1,0) [0|0] ""  RghtRrLCMA
 SG_ RghtRPlLed026 : 15|8@0+ (1,0) [0|0] ""  RghtRrLCMA
 SG_ RghtRPlLed025 : 7|8@0+ (1,0) [0|0] ""  RghtRrLCMA

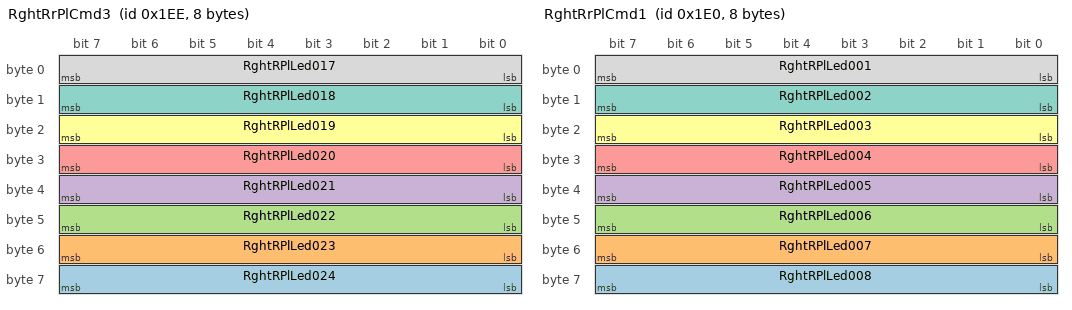
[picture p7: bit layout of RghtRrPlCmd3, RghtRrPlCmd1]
BO_ 494 RghtRrPlCmd3: 8 AFL_AHL
 SG_ RghtRPlLed024 : 63|8@0+ (1,0) [0|0] ""  RghtRrLCMA
 SG_ RghtRPlLed023 : 55|8@0+ (1,0) [0|0] ""  RghtRrLCMA
 SG_ RghtRPlLed022 : 47|8@0+ (1,0) [0|0] ""  RghtRrLCMA
 SG_ RghtRPlLed021 : 39|8@0+ (1,0) [0|0] ""  RghtRrLCMA
 SG_ RghtRPlLed020 : 31|8@0+ (1,0) [0|0] ""  RghtRrLCMA
 SG_ RghtRPlLed019 : 23|8@0+ (1,0) [0|0] ""  RghtRrLCMA
 SG_ RghtRPlLed018 : 15|8@0+ (1,0) [0|0] ""  RghtRrLCMA
 SG_ RghtRPlLed017 : 7|8@0+ (1,0) [0|0] ""  RghtRrLCMA

BO_ 480 RghtRrPlCmd1: 8 AFL_AHL
 SG_ RghtRPlLed008 : 63|8@0+ (1,0) [0|0] ""  RghtRrLCMA
 SG_ RghtRPlLed007 : 55|8@0+ (1,0) [0|0] ""  RghtRrLCMA
 SG_ RghtRPlLed006 : 47|8@0+ (1,0) [0|0] ""  RghtRrLCMA
 SG_ RghtRPlLed005 : 39|8@0+ (1,0) [0|0] ""  RghtRrLCMA
 SG_ RghtRPlLed004 : 31|8@0+ (1,0) [0|0] ""  RghtRrLCMA
 SG_ RghtRPlLed003 : 23|8@0+ (1,0) [0|0] ""  RghtRrLCMA
 SG_ RghtRPlLed002 : 15|8@0+ (1,0) [0|0] ""  RghtRrLCMA
 SG_ RghtRPlLed001 : 7|8@0+ (1,0) [0|0] ""  RghtRrLCMA

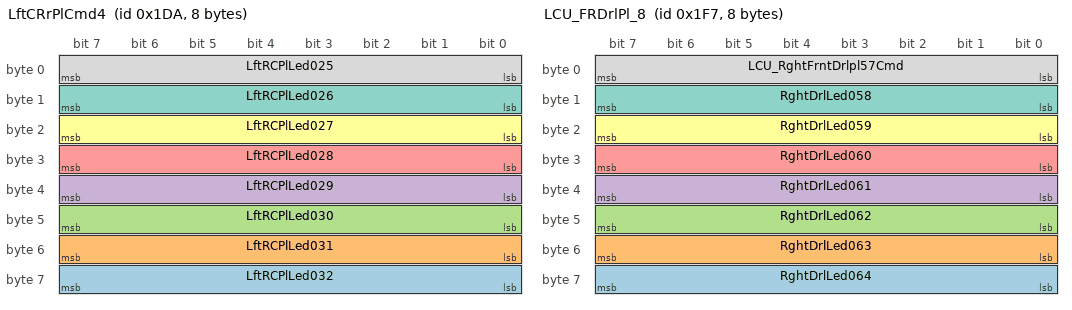
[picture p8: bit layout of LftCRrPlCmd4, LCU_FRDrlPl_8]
BO_ 474 LftCRrPlCmd4: 8 AFL_AHL
 SG_ LftRCPlLed032 : 63|8@0+ (1,0) [0|0] ""  LftRrLCMB
 SG_ LftRCPlLed031 : 55|8@0+ (1,0) [0|0] ""  LftRrLCMB
 SG_ LftRCPlLed030 : 47|8@0+ (1,0) [0|0] ""  LftRrLCMB
 SG_ LftRCPlLed029 : 39|8@0+ (1,0) [0|0] ""  LftRrLCMB
 SG_ LftRCPlLed028 : 31|8@0+ (1,0) [0|0] ""  LftRrLCMB
 SG_ LftRCPlLed027 : 23|8@0+ (1,0) [0|0] ""  LftRrLCMB
 SG_ LftRCPlLed026 : 15|8@0+ (1,0) [0|0] ""  LftRrLCMB
 SG_ LftRCPlLed025 : 7|8@0+ (1,0) [0|0] ""  LftRrLCMB

BO_ 503 LCU_FRDrlPl_8: 8 AFL_AHL
 SG_ RghtDrlLed064 : 63|8@0+ (1,0) [0|0] ""  RghtFrntLCMA
 SG_ RghtDrlLed063 : 55|8@0+ (1,0) [0|0] ""  RghtFrntLCMA
 SG_ RghtDrlLed062 : 47|8@0+ (1,0) [0|0] ""  RghtFrntLCMA
 SG_ RghtDrlLed061 : 39|8@0+ (1,0) [0|0] ""  RghtFrntLCMA
 SG_ RghtDrlLed060 : 31|8@0+ (1,0) [0|0] ""  RghtFrntLCMA
 SG_ RghtDrlLed059 : 23|8@0+ (1,0) [0|0] ""  RghtFrntLCMA
 SG_ RghtDrlLed058 : 15|8@0+ (1,0) [0|0] ""  RghtFrntLCMA
 SG_ LCU_RghtFrntDrlpl57Cmd : 7|8@0+ (1,0) [0|100] "%"  RghtFrntLCMA

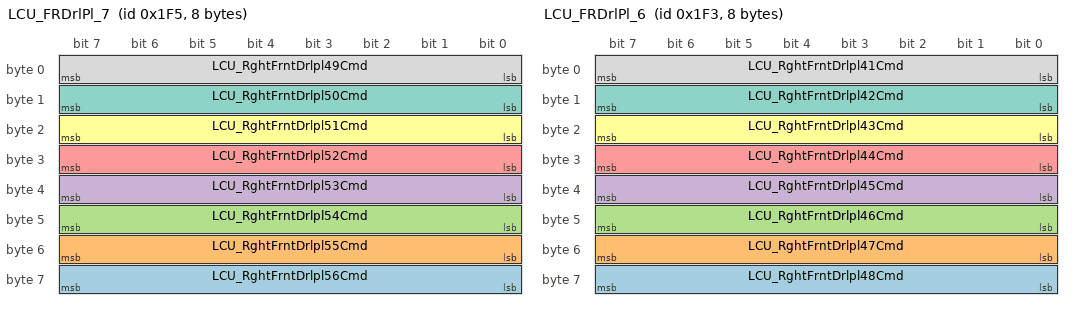
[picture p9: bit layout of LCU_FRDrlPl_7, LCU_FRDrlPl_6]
BO_ 501 LCU_FRDrlPl_7: 8 AFL_AHL
 SG_ LCU_RghtFrntDrlpl56Cmd : 63|8@0+ (1,0) [0|255] "%" Vector__XXX
 SG_ LCU_RghtFrntDrlpl55Cmd : 55|8@0+ (1,0) [0|255] "%" Vector__XXX
 SG_ LCU_RghtFrntDrlpl54Cmd : 40|8@1- (1,0) [0|100] "%" Vector__XXX
 SG_ LCU_RghtFrntDrlpl53Cmd : 39|8@0+ (1,0) [0|255] "%" Vector__XXX
 SG_ LCU_RghtFrntDrlpl52Cmd : 31|8@0+ (1,0) [0|0] "" Vector__XXX
 SG_ LCU_RghtFrntDrlpl51Cmd : 23|8@0+ (1,0) [0|255] "%" Vector__XXX
 SG_ LCU_RghtFrntDrlpl50Cmd : 15|8@0+ (1,0) [0|100] "%"  RghtFrntLCMA
 SG_ LCU_RghtFrntDrlpl49Cmd : 7|8@0+ (1,0) [0|100] "%"  RghtFrntLCMA

BO_ 499 LCU_FRDrlPl_6: 8 AFL_AHL
 SG_ LCU_RghtFrntDrlpl48Cmd : 63|8@0+ (1,0) [0|100] "%"  RghtFrntLCMA
 SG_ LCU_RghtFrntDrlpl47Cmd : 55|8@0+ (1,0) [0|100] "%"  RghtFrntLCMA
 SG_ LCU_RghtFrntDrlpl46Cmd : 47|8@0+ (1,0) [0|100] "%"  RghtFrntLCMA
 SG_ LCU_RghtFrntDrlpl45Cmd : 39|8@0+ (1,0) [0|100] "%"  RghtFrntLCMA
 SG_ LCU_RghtFrntDrlpl44Cmd : 31|8@0+ (1,0) [0|100] "%"  RghtFrntLCMA
 SG_ LCU_RghtFrntDrlpl43Cmd : 23|8@0+ (1,0) [0|100] "%"  RghtFrntLCMA
 SG_ LCU_RghtFrntDrlpl42Cmd : 15|8@0+ (1,0) [0|100] "%"  RghtFrntLCMA
 SG_ LCU_RghtFrntDrlpl41Cmd : 7|8@0+ (1,0) [0|100] "%"  RghtFrntLCMA

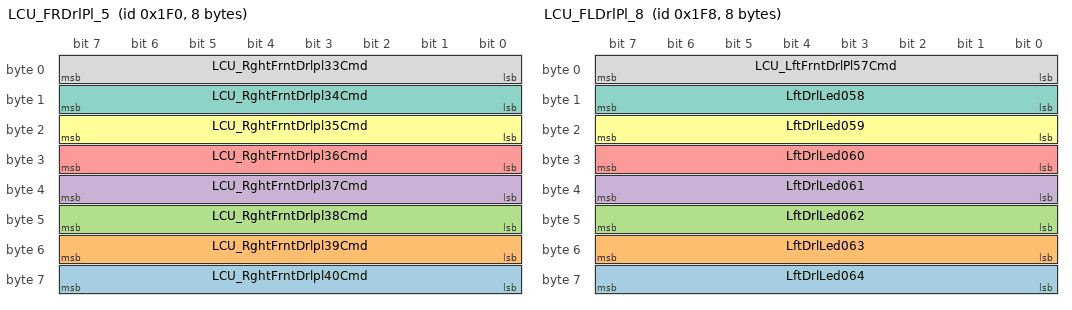
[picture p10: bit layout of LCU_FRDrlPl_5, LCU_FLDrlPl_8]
BO_ 496 LCU_FRDrlPl_5: 8 AFL_AHL
 SG_ LCU_RghtFrntDrlpl40Cmd : 63|8@0+ (1,0) [0|100] "%"  RghtFrntLCMA
 SG_ LCU_RghtFrntDrlpl39Cmd : 55|8@0+ (1,0) [0|100] "%"  RghtFrntLCMA
 SG_ LCU_RghtFrntDrlpl38Cmd : 47|8@0+ (1,0) [0|100] "%"  RghtFrntLCMA
 SG_ LCU_RghtFrntDrlpl37Cmd : 39|8@0+ (1,0) [0|100] "%"  RghtFrntLCMA
 SG_ LCU_RghtFrntDrlpl36Cmd : 31|8@0+ (1,0) [0|100] "%"  RghtFrntLCMA
 SG_ LCU_RghtFrntDrlpl35Cmd : 23|8@0+ (1,0) [0|100] "%"  RghtFrntLCMA
 SG_ LCU_RghtFrntDrlpl34Cmd : 15|8@0+ (1,0) [0|100] "%"  RghtFrntLCMA
 SG_ LCU_RghtFrntDrlpl33Cmd : 7|8@0+ (1,0) [0|100] "%"  RghtFrntLCMA

BO_ 504 LCU_FLDrlPl_8: 8 AFL_AHL
 SG_ LftDrlLed064 : 63|8@0+ (1,0) [0|0] ""  LftFrntLCMA
 SG_ LftDrlLed063 : 55|8@0+ (1,0) [0|0] ""  LftFrntLCMA
 SG_ LftDrlLed062 : 47|8@0+ (1,0) [0|0] ""  LftFrntLCMA
 SG_ LftDrlLed061 : 39|8@0+ (1,0) [0|0] ""  LftFrntLCMA
 SG_ LftDrlLed060 : 31|8@0+ (1,0) [0|0] ""  LftFrntLCMA
 SG_ LftDrlLed059 : 23|8@0+ (1,0) [0|0] ""  LftFrntLCMA
 SG_ LftDrlLed058 : 15|8@0+ (1,0) [0|0] ""  LftFrntLCMA
 SG_ LCU_LftFrntDrlPl57Cmd : 7|8@0+ (1,0) [0|100] "%"  LftFrntLCMA

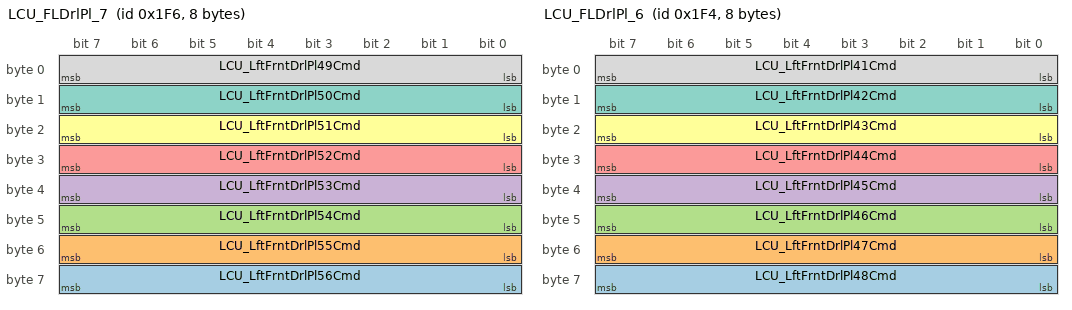
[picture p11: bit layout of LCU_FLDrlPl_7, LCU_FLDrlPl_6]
BO_ 502 LCU_FLDrlPl_7: 8 AFL_AHL
 SG_ LCU_LftFrntDrlPl56Cmd : 63|8@0+ (1,0) [0|100] "%"  LftFrntLCMA
 SG_ LCU_LftFrntDrlPl55Cmd : 55|8@0+ (1,0) [0|100] "%"  LftFrntLCMA
 SG_ LCU_LftFrntDrlPl54Cmd : 47|8@0+ (1,0) [0|100] "%"  LftFrntLCMA
 SG_ LCU_LftFrntDrlPl53Cmd : 39|8@0+ (1,0) [0|100] "%"  LftFrntLCMA
 SG_ LCU_LftFrntDrlPl52Cmd : 31|8@0+ (1,0) [0|100] "%"  LftFrntLCMA
 SG_ LCU_LftFrntDrlPl51Cmd : 23|8@0+ (1,0) [0|100] "%"  LftFrntLCMA
 SG_ LCU_LftFrntDrlPl50Cmd : 15|8@0+ (1,0) [0|100] "%"  LftFrntLCMA
 SG_ LCU_LftFrntDrlPl49Cmd : 7|8@0+ (1,0) [0|100] "%"  LftFrntLCMA

BO_ 500 LCU_FLDrlPl_6: 8 AFL_AHL
 SG_ LCU_LftFrntDrlPl48Cmd : 63|8@0+ (1,0) [0|100] "%"  LftFrntLCMA
 SG_ LCU_LftFrntDrlPl47Cmd : 55|8@0+ (1,0) [0|100] "%"  LftFrntLCMA
 SG_ LCU_LftFrntDrlPl46Cmd : 47|8@0+ (1,0) [0|100] "%"  LftFrntLCMA
 SG_ LCU_LftFrntDrlPl45Cmd : 39|8@0+ (1,0) [0|100] "%"  LftFrntLCMA
 SG_ LCU_LftFrntDrlPl44Cmd : 31|8@0+ (1,0) [0|100] "%"  LftFrntLCMA
 SG_ LCU_LftFrntDrlPl43Cmd : 23|8@0+ (1,0) [0|100] "%"  LftFrntLCMA
 SG_ LCU_LftFrntDrlPl42Cmd : 15|8@0+ (1,0) [0|100] "%"  LftFrntLCMA
 SG_ LCU_LftFrntDrlPl41Cmd : 7|8@0+ (1,0) [0|100] "%"  LftFrntLCMA

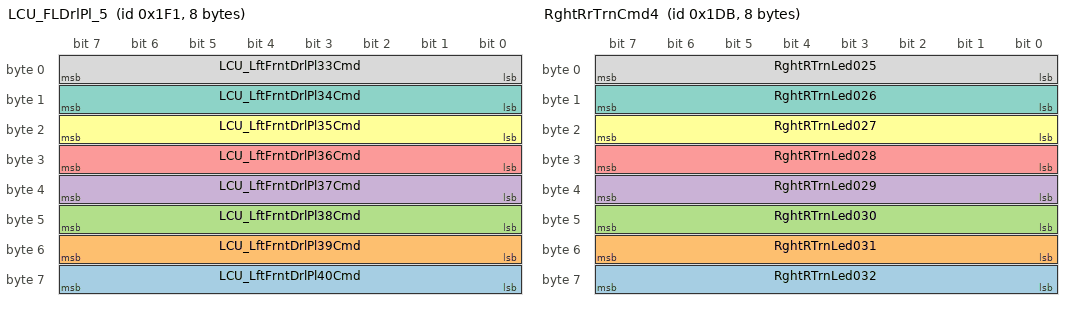
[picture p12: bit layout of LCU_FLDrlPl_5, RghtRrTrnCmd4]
BO_ 497 LCU_FLDrlPl_5: 8 AFL_AHL
 SG_ LCU_LftFrntDrlPl40Cmd : 63|8@0+ (1,0) [0|100] "%"  LftFrntLCMA
 SG_ LCU_LftFrntDrlPl39Cmd : 55|8@0+ (1,0) [0|100] "%"  LftFrntLCMA
 SG_ LCU_LftFrntDrlPl38Cmd : 47|8@0+ (1,0) [0|100] "%"  LftFrntLCMA
 SG_ LCU_LftFrntDrlPl37Cmd : 39|8@0+ (1,0) [0|100] "%"  LftFrntLCMA
 SG_ LCU_LftFrntDrlPl36Cmd : 31|8@0+ (1,0) [0|100] "%"  LftFrntLCMA
 SG_ LCU_LftFrntDrlPl35Cmd : 23|8@0+ (1,0) [0|100] "%"  LftFrntLCMA
 SG_ LCU_LftFrntDrlPl34Cmd : 15|8@0+ (1,0) [0|100] "%"  LftFrntLCMA
 SG_ LCU_LftFrntDrlPl33Cmd : 7|8@0+ (1,0) [0|100] "%"  LftFrntLCMA

BO_ 475 RghtRrTrnCmd4: 8 AFL_AHL
 SG_ RghtRTrnLed032 : 63|8@0+ (1,0) [0|0] ""  RghtRrLCMA
 SG_ RghtRTrnLed031 : 55|8@0+ (1,0) [0|0] ""  RghtRrLCMA
 SG_ RghtRTrnLed030 : 47|8@0+ (1,0) [0|0] ""  RghtRrLCMA
 SG_ RghtRTrnLed029 : 39|8@0+ (1,0) [0|0] ""  RghtRrLCMA
 SG_ RghtRTrnLed028 : 31|8@0+ (1,0) [0|0] ""  RghtRrLCMA
 SG_ RghtRTrnLed027 : 23|8@0+ (1,0) [0|0] ""  RghtRrLCMA
 SG_ RghtRTrnLed026 : 15|8@0+ (1,0) [0|0] ""  RghtRrLCMA
 SG_ RghtRTrnLed025 : 7|8@0+ (1,0) [0|0] ""  RghtRrLCMA

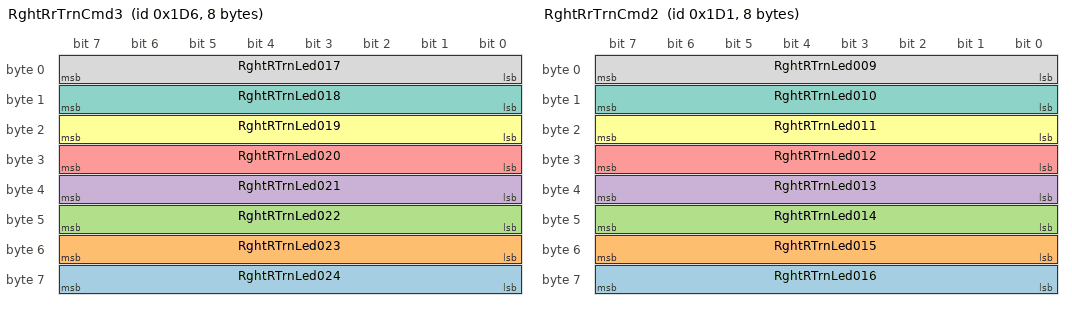
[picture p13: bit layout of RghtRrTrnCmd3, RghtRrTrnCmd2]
BO_ 470 RghtRrTrnCmd3: 8 AFL_AHL
 SG_ RghtRTrnLed024 : 63|8@0+ (1,0) [0|0] ""  RghtRrLCMA
 SG_ RghtRTrnLed023 : 55|8@0+ (1,0) [0|0] ""  RghtRrLCMA
 SG_ RghtRTrnLed022 : 47|8@0+ (1,0) [0|0] ""  RghtRrLCMA
 SG_ RghtRTrnLed021 : 39|8@0+ (1,0) [0|0] ""  RghtRrLCMA
 SG_ RghtRTrnLed020 : 31|8@0+ (1,0) [0|0] ""  RghtRrLCMA
 SG_ RghtRTrnLed019 : 23|8@0+ (1,0) [0|0] ""  RghtRrLCMA
 SG_ RghtRTrnLed018 : 15|8@0+ (1,0) [0|0] ""  RghtRrLCMA
 SG_ RghtRTrnLed017 : 7|8@0+ (1,0) [0|0] ""  RghtRrLCMA

BO_ 465 RghtRrTrnCmd2: 8 AFL_AHL
 SG_ RghtRTrnLed016 : 63|8@0+ (1,0) [0|0] ""  RghtRrLCMA
 SG_ RghtRTrnLed015 : 55|8@0+ (1,0) [0|0] ""  RghtRrLCMA
 SG_ RghtRTrnLed014 : 47|8@0+ (1,0) [0|0] ""  RghtRrLCMA
 SG_ RghtRTrnLed013 : 39|8@0+ (1,0) [0|0] ""  RghtRrLCMA
 SG_ RghtRTrnLed012 : 31|8@0+ (1,0) [0|0] ""  RghtRrLCMA
 SG_ RghtRTrnLed011 : 23|8@0+ (1,0) [0|0] ""  RghtRrLCMA
 SG_ RghtRTrnLed010 : 15|8@0+ (1,0) [0|0] ""  RghtRrLCMA
 SG_ RghtRTrnLed009 : 7|8@0+ (1,0) [0|0] ""  RghtRrLCMA

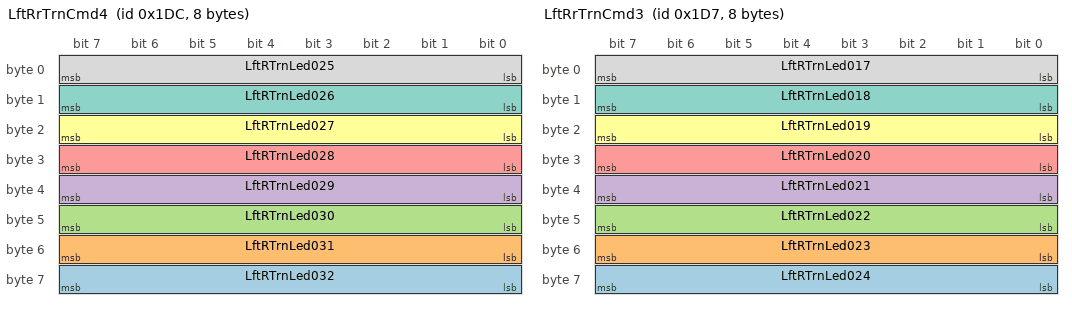
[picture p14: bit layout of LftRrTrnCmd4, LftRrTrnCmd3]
BO_ 476 LftRrTrnCmd4: 8 AFL_AHL
 SG_ LftRTrnLed032 : 63|8@0+ (1,0) [0|0] ""  LftRrLCMA
 SG_ LftRTrnLed031 : 55|8@0+ (1,0) [0|0] ""  LftRrLCMA
 SG_ LftRTrnLed030 : 47|8@0+ (1,0) [0|0] ""  LftRrLCMA
 SG_ LftRTrnLed029 : 39|8@0+ (1,0) [0|0] ""  LftRrLCMA
 SG_ LftRTrnLed028 : 31|8@0+ (1,0) [0|0] ""  LftRrLCMA
 SG_ LftRTrnLed027 : 23|8@0+ (1,0) [0|0] ""  LftRrLCMA
 SG_ LftRTrnLed026 : 15|8@0+ (1,0) [0|0] ""  LftRrLCMA
 SG_ LftRTrnLed025 : 7|8@0+ (1,0) [0|0] ""  LftRrLCMA

BO_ 471 LftRrTrnCmd3: 8 AFL_AHL
 SG_ LftRTrnLed024 : 63|8@0+ (1,0) [0|0] ""  LftRrLCMA
 SG_ LftRTrnLed023 : 55|8@0+ (1,0) [0|0] ""  LftRrLCMA
 SG_ LftRTrnLed022 : 47|8@0+ (1,0) [0|0] ""  LftRrLCMA
 SG_ LftRTrnLed021 : 39|8@0+ (1,0) [0|0] ""  LftRrLCMA
 SG_ LftRTrnLed020 : 31|8@0+ (1,0) [0|0] ""  LftRrLCMA
 SG_ LftRTrnLed019 : 23|8@0+ (1,0) [0|0] ""  LftRrLCMA
 SG_ LftRTrnLed018 : 15|8@0+ (1,0) [0|0] ""  LftRrLCMA
 SG_ LftRTrnLed017 : 7|8@0+ (1,0) [0|0] ""  LftRrLCMA

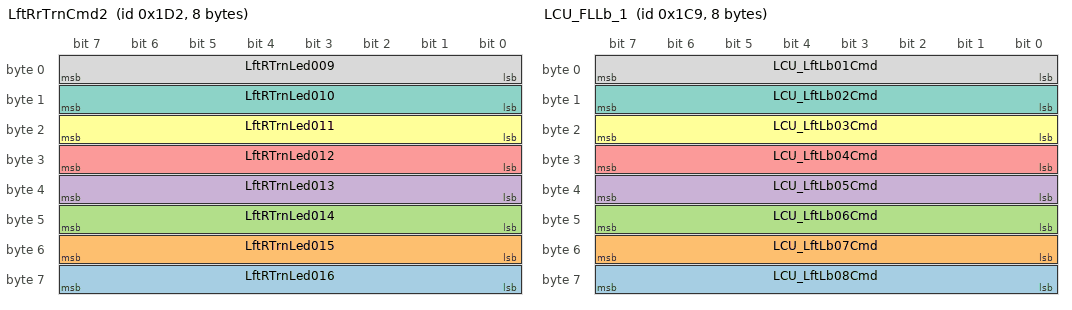
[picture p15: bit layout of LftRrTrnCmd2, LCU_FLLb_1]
BO_ 466 LftRrTrnCmd2: 8 AFL_AHL
 SG_ LftRTrnLed016 : 63|8@0+ (1,0) [0|0] ""  LftRrLCMA
 SG_ LftRTrnLed015 : 55|8@0+ (1,0) [0|0] ""  LftRrLCMA
 SG_ LftRTrnLed014 : 47|8@0+ (1,0) [0|0] ""  LftRrLCMA
 SG_ LftRTrnLed013 : 39|8@0+ (1,0) [0|0] ""  LftRrLCMA
 SG_ LftRTrnLed012 : 31|8@0+ (1,0) [0|0] ""  LftRrLCMA
 SG_ LftRTrnLed011 : 23|8@0+ (1,0) [0|0] ""  LftRrLCMA
 SG_ LftRTrnLed010 : 15|8@0+ (1,0) [0|0] ""  LftRrLCMA
 SG_ LftRTrnLed009 : 7|8@0+ (1,0) [0|0] ""  LftRrLCMA

BO_ 1970 DiagResp_RghtFrntA: 8 RghtFrntLCMA
 SG_ DiagRsp_FRLCMA : 7|64@0+ (1,0) [0|0] ""  TestTool

BO_ 1842 PhyDiagReq_RghtFrntA: 8 TestTool
 SG_ DiagPhyReq_FRLCMA : 7|64@0+ (1,0) [0|1.84467440737096E+019] ""  RghtFrntLCMA

BO_ 2015 FuncDiagReq: 8 TestTool
 SG_ DiagInf : 7|64@0+ (1,0) [0|0] ""  RghtRrLCMB,RghtRrLCMA,RghtFrntLCMB,LftRrLCMB,LftRrLCMA,LftFrntLCMB,RghtFrntLCMA,LftFrntLCMA

BO_ 1825 PhyDiagReq_LftFrntA: 8 TestTool
 SG_ DiagPhyReq_FLLCMA : 7|64@0+ (1,0) [0|1.84467440737096E+019] ""  LftFrntLCMA

BO_ 1953 DiagResp_LftFrntA: 8 LftFrntLCMA
 SG_ DiagRsp_FLLCMA : 7|64@0+ (1,0) [0|0] ""  TestTool

BO_ 2161836032 ExtendIdTest: 8 TestTool
 SG_ ExtData : 7|64@0+ (1,0) [0|0] ""  RghtRrLCMB,RghtRrLCMA,RghtFrntLCMB,RghtFrntLCMA,LftRrLCMB,LftRrLCMA,LftFrntLCMB,LftFrntLCMA

BO_ 457 LCU_FLLb_1: 8 AFL_AHL
 SG_ LCU_LftLb08Cmd : 63|8@0+ (1,0) [0|100] "%"  LftFrntLCMA
 SG_ LCU_LftLb07Cmd : 55|8@0+ (1,0) [0|100] "%"  LftFrntLCMA
 SG_ LCU_LftLb06Cmd : 47|8@0+ (1,0) [0|100] "%"  LftFrntLCMA
 SG_ LCU_LftLb05Cmd : 39|8@0+ (1,0) [0|100] "%"  LftFrntLCMA
 SG_ LCU_LftLb04Cmd : 31|8@0+ (1,0) [0|100] "%"  LftFrntLCMA
 SG_ LCU_LftLb03Cmd : 23|8@0+ (1,0) [0|100] "%"  LftFrntLCMA
 SG_ LCU_LftLb02Cmd : 15|8@0+ (1,0) [0|100] "%"  LftFrntLCMA
 SG_ LCU_LftLb01Cmd : 7|8@0+ (1,0) [0|100] "%"  LftFrntLCMA

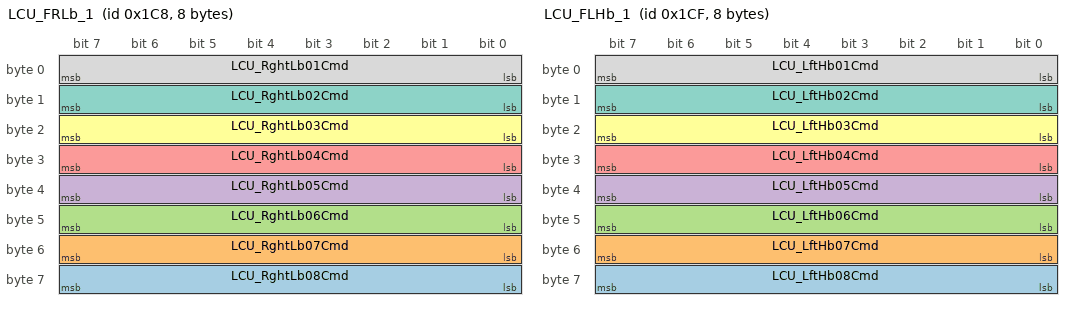
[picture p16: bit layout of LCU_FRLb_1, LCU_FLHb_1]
BO_ 456 LCU_FRLb_1: 8 AFL_AHL
 SG_ LCU_RghtLb08Cmd : 63|8@0+ (1,0) [0|100] "%"  RghtFrntLCMA
 SG_ LCU_RghtLb07Cmd : 55|8@0+ (1,0) [0|100] "%"  RghtFrntLCMA
 SG_ LCU_RghtLb06Cmd : 47|8@0+ (1,0) [0|100] "%"  RghtFrntLCMA
 SG_ LCU_RghtLb05Cmd : 39|8@0+ (1,0) [0|100] "%"  RghtFrntLCMA
 SG_ LCU_RghtLb04Cmd : 31|8@0+ (1,0) [0|100] "%"  RghtFrntLCMA
 SG_ LCU_RghtLb03Cmd : 23|8@0+ (1,0) [0|100] "%"  RghtFrntLCMA
 SG_ LCU_RghtLb02Cmd : 15|8@0+ (1,0) [0|100] "%"  RghtFrntLCMA
 SG_ LCU_RghtLb01Cmd : 7|8@0+ (1,0) [0|100] "%"  RghtFrntLCMA

BO_ 463 LCU_FLHb_1: 8 AFL_AHL
 SG_ LCU_LftHb08Cmd : 63|8@0+ (1,0) [0|100] "%"  LftFrntLCMA
 SG_ LCU_LftHb07Cmd : 55|8@0+ (1,0) [0|100] "%"  LftFrntLCMA
 SG_ LCU_LftHb06Cmd : 47|8@0+ (1,0) [0|100] "%"  LftFrntLCMA
 SG_ LCU_LftHb05Cmd : 39|8@0+ (1,0) [0|100] "%"  LftFrntLCMA
 SG_ LCU_LftHb04Cmd : 31|8@0+ (1,0) [0|100] "%"  LftFrntLCMA
 SG_ LCU_LftHb03Cmd : 23|8@0+ (1,0) [0|100] "%"  LftFrntLCMA
 SG_ LCU_LftHb02Cmd : 15|8@0+ (1,0) [0|100] "%"  LftFrntLCMA
 SG_ LCU_LftHb01Cmd : 7|8@0+ (1,0) [0|100] "%"  LftFrntLCMA

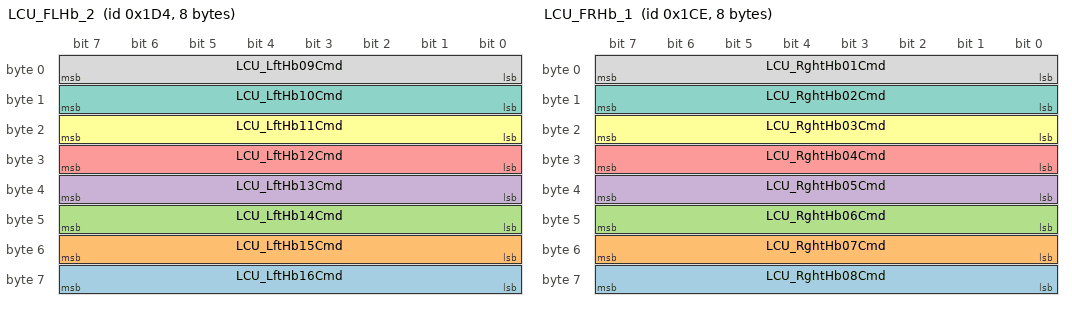
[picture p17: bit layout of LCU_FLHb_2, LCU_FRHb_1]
BO_ 468 LCU_FLHb_2: 8 AFL_AHL
 SG_ LCU_LftHb16Cmd : 63|8@0+ (1,0) [0|100] "%"  LftFrntLCMA
 SG_ LCU_LftHb15Cmd : 55|8@0+ (1,0) [0|100] "%"  LftFrntLCMA
 SG_ LCU_LftHb14Cmd : 47|8@0+ (1,0) [0|100] "%"  LftFrntLCMA
 SG_ LCU_LftHb13Cmd : 39|8@0+ (1,0) [0|100] "%"  LftFrntLCMA
 SG_ LCU_LftHb12Cmd : 31|8@0+ (1,0) [0|100] "%"  LftFrntLCMA
 SG_ LCU_LftHb11Cmd : 23|8@0+ (1,0) [0|100] "%"  LftFrntLCMA
 SG_ LCU_LftHb10Cmd : 15|8@0+ (1,0) [0|100] "%"  LftFrntLCMA
 SG_ LCU_LftHb09Cmd : 7|8@0+ (1,0) [0|100] "%"  LftFrntLCMA

BO_ 462 LCU_FRHb_1: 8 AFL_AHL
 SG_ LCU_RghtHb08Cmd : 63|8@0+ (1,0) [0|100] "%"  RghtFrntLCMA
 SG_ LCU_RghtHb07Cmd : 55|8@0+ (1,0) [0|100] "%"  RghtFrntLCMA
 SG_ LCU_RghtHb06Cmd : 47|8@0+ (1,0) [0|100] "%"  RghtFrntLCMA
 SG_ LCU_RghtHb05Cmd : 39|8@0+ (1,0) [0|100] "%"  RghtFrntLCMA
 SG_ LCU_RghtHb04Cmd : 31|8@0+ (1,0) [0|100] "%"  RghtFrntLCMA
 SG_ LCU_RghtHb03Cmd : 23|8@0+ (1,0) [0|100] "%"  RghtFrntLCMA
 SG_ LCU_RghtHb02Cmd : 15|8@0+ (1,0) [0|100] "%"  RghtFrntLCMA
 SG_ LCU_RghtHb01Cmd : 7|8@0+ (1,0) [0|100] "%"  RghtFrntLCMA

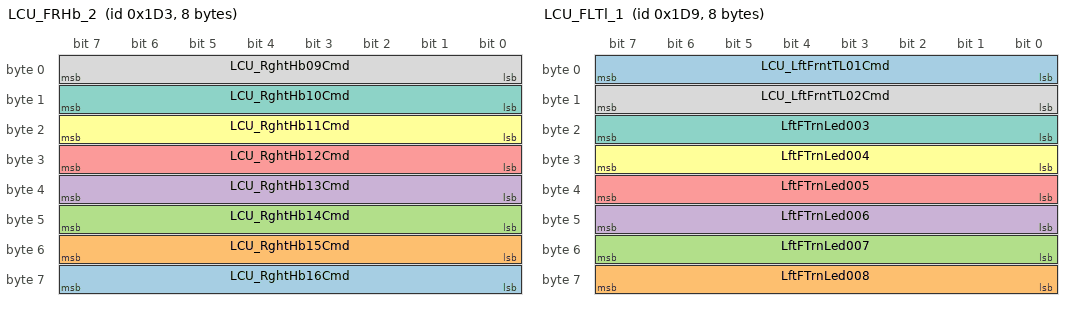
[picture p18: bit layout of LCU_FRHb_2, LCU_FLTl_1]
BO_ 467 LCU_FRHb_2: 8 AFL_AHL
 SG_ LCU_RghtHb16Cmd : 63|8@0+ (1,0) [0|100] "%"  RghtFrntLCMA
 SG_ LCU_RghtHb15Cmd : 55|8@0+ (1,0) [0|100] "%"  RghtFrntLCMA
 SG_ LCU_RghtHb14Cmd : 47|8@0+ (1,0) [0|100] "%"  RghtFrntLCMA
 SG_ LCU_RghtHb13Cmd : 39|8@0+ (1,0) [0|100] "%"  RghtFrntLCMA
 SG_ LCU_RghtHb12Cmd : 31|8@0+ (1,0) [0|100] "%"  RghtFrntLCMA
 SG_ LCU_RghtHb11Cmd : 23|8@0+ (1,0) [0|100] "%"  RghtFrntLCMA
 SG_ LCU_RghtHb10Cmd : 15|8@0+ (1,0) [0|100] "%"  RghtFrntLCMA
 SG_ LCU_RghtHb09Cmd : 7|8@0+ (1,0) [0|100] "%"  RghtFrntLCMA

BO_ 473 LCU_FLTl_1: 8 AFL_AHL
 SG_ LCU_LftFrntTL01Cmd : 7|8@0+ (1,0) [0|100] "%"  LftFrntLCMA
 SG_ LftFTrnLed008 : 63|8@0+ (1,0) [0|0] ""  LftFrntLCMA
 SG_ LftFTrnLed007 : 55|8@0+ (1,0) [0|0] ""  LftFrntLCMA
 SG_ LftFTrnLed006 : 47|8@0+ (1,0) [0|0] ""  LftFrntLCMA
 SG_ LftFTrnLed005 : 39|8@0+ (1,0) [0|0] ""  LftFrntLCMA
 SG_ LftFTrnLed004 : 31|8@0+ (1,0) [0|0] ""  LftFrntLCMA
 SG_ LftFTrnLed003 : 23|8@0+ (1,0) [0|0] ""  LftFrntLCMA
 SG_ LCU_LftFrntTL02Cmd : 15|8@0+ (1,0) [0|100] "%"  LftFrntLCMA

BO_ 472 LCU_FRTl_1: 8 AFL_AHL
 SG_ LCU_RghtFrntTL02Cmd : 15|8@0+ (1,0) [0|100] "%"  RghtFrntLCMA
 SG_ LCU_RghtFrntTL01Cmd : 7|8@0+ (1,0) [0|100] "%"  RghtFrntLCMA

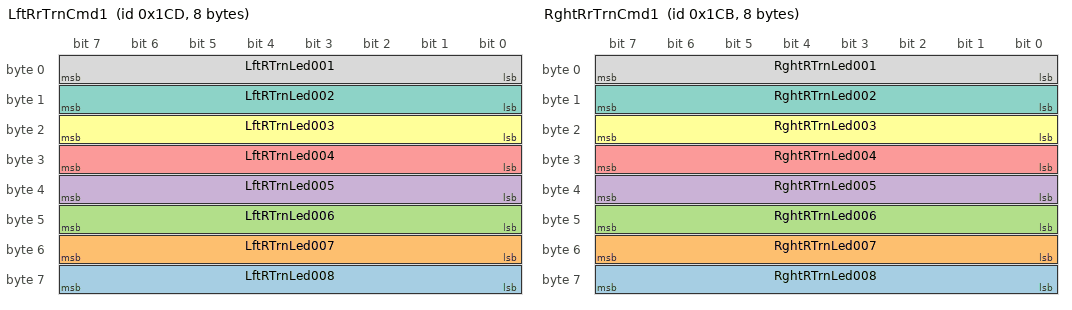
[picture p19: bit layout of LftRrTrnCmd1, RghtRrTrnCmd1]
BO_ 461 LftRrTrnCmd1: 8 AFL_AHL
 SG_ LftRTrnLed008 : 63|8@0+ (1,0) [0|0] ""  LftRrLCMA
 SG_ LftRTrnLed007 : 55|8@0+ (1,0) [0|0] ""  LftRrLCMA
 SG_ LftRTrnLed006 : 47|8@0+ (1,0) [0|0] ""  LftRrLCMA
 SG_ LftRTrnLed005 : 39|8@0+ (1,0) [0|0] ""  LftRrLCMA
 SG_ LftRTrnLed004 : 31|8@0+ (1,0) [0|0] ""  LftRrLCMA
 SG_ LftRTrnLed003 : 23|8@0+ (1,0) [0|0] ""  LftRrLCMA
 SG_ LftRTrnLed002 : 15|8@0+ (1,0) [0|0] ""  LftRrLCMA
 SG_ LftRTrnLed001 : 7|8@0+ (1,0) [0|0] ""  LftRrLCMA

BO_ 459 RghtRrTrnCmd1: 8 AFL_AHL
 SG_ RghtRTrnLed008 : 63|8@0+ (1,0) [0|0] ""  RghtRrLCMA
 SG_ RghtRTrnLed007 : 55|8@0+ (1,0) [0|0] ""  RghtRrLCMA
 SG_ RghtRTrnLed006 : 47|8@0+ (1,0) [0|0] ""  RghtRrLCMA
 SG_ RghtRTrnLed005 : 39|8@0+ (1,0) [0|0] ""  RghtRrLCMA
 SG_ RghtRTrnLed004 : 31|8@0+ (1,0) [0|0] ""  RghtRrLCMA
 SG_ RghtRTrnLed003 : 23|8@0+ (1,0) [0|0] ""  RghtRrLCMA
 SG_ RghtRTrnLed002 : 15|8@0+ (1,0) [0|0] ""  RghtRrLCMA
 SG_ RghtRTrnLed001 : 7|8@0+ (1,0) [0|0] ""  RghtRrLCMA

BO_ 478 LCU_FLDrlPl_1: 8 AFL_AHL
 SG_ LCU_LftFrntDrlPl08Cmd : 63|8@0+ (1,0) [0|100] "%"  LftFrntLCMA
 SG_ LCU_LftFrntDrlPl07Cmd : 55|8@0+ (1,0) [0|100] "%"  LftFrntLCMA
 SG_ LCU_LftFrntDrlPl06Cmd : 47|8@0+ (1,0) [0|100] "%"  LftFrntLCMA
 SG_ LCU_LftFrntDrlPl05Cmd : 39|8@0+ (1,0) [0|100] "%"  LftFrntLCMA
 SG_ LCU_LftFrntDrlPl04Cmd : 31|8@0+ (1,0) [0|100] "%"  LftFrntLCMA
 SG_ LCU_LftFrntDrlPl03Cmd : 23|8@0+ (1,0) [0|100] "%"  LftFrntLCMA
 SG_ LCU_LftFrntDrlPl02Cmd : 15|8@0+ (1,0) [0|100] "%"  LftFrntLCMA
 SG_ LCU_LftFrntDrlPl01Cmd : 7|8@0+ (1,0) [0|100] "%"  LftFrntLCMA

BO_ 483 LCU_FLDrlPl_2: 8 AFL_AHL
 SG_ LCU_LftFrntDrlPl16Cmd : 63|8@0+ (1,0) [0|100] "%"  LftFrntLCMA
 SG_ LCU_LftFrntDrlPl15Cmd : 55|8@0+ (1,0) [0|100] "%"  LftFrntLCMA
 SG_ LCU_LftFrntDrlPl14Cmd : 47|8@0+ (1,0) [0|100] "%"  LftFrntLCMA
 SG_ LCU_LftFrntDrlPl13Cmd : 39|8@0+ (1,0) [0|100] "%"  LftFrntLCMA
 SG_ LCU_LftFrntDrlPl12Cmd : 31|8@0+ (1,0) [0|100] "%"  LftFrntLCMA
 SG_ LCU_LftFrntDrlPl11Cmd : 23|8@0+ (1,0) [0|100] "%"  LftFrntLCMA
 SG_ LCU_LftFrntDrlPl10Cmd : 15|8@0+ (1,0) [0|100] "%"  LftFrntLCMA
 SG_ LCU_LftFrntDrlPl09Cmd : 7|8@0+ (1,0) [0|100] "%"  LftFrntLCMA

BO_ 488 LCU_FLDrlPl_3: 8 AFL_AHL
 SG_ LCU_LftFrntDrlPl24Cmd : 63|8@0+ (1,0) [0|100] "%"  LftFrntLCMA
 SG_ LCU_LftFrntDrlPl23Cmd : 55|8@0+ (1,0) [0|100] "%"  LftFrntLCMA
 SG_ LCU_LftFrntDrlPl22Cmd : 47|8@0+ (1,0) [0|100] "%"  LftFrntLCMA
 SG_ LCU_LftFrntDrlPl21Cmd : 39|8@0+ (1,0) [0|100] "%"  LftFrntLCMA
 SG_ LCU_LftFrntDrlPl20Cmd : 31|8@0+ (1,0) [0|100] "%"  LftFrntLCMA
 SG_ LCU_LftFrntDrlPl19Cmd : 23|8@0+ (1,0) [0|100] "%"  LftFrntLCMA
 SG_ LCU_LftFrntDrlPl18Cmd : 15|8@0+ (1,0) [0|100] "%"  LftFrntLCMA
 SG_ LCU_LftFrntDrlPl17Cmd : 7|8@0+ (1,0) [0|100] "%"  LftFrntLCMA

BO_ 493 LCU_FLDrlPl_4: 8 AFL_AHL
 SG_ LCU_LftFrntDrlPl32Cmd : 63|8@0+ (1,0) [0|100] "%"  LftFrntLCMA
 SG_ LCU_LftFrntDrlPl31Cmd : 55|8@0+ (1,0) [0|100] "%"  LftFrntLCMA
 SG_ LCU_LftFrntDrlPl30Cmd : 47|8@0+ (1,0) [0|100] "%"  LftFrntLCMA
 SG_ LCU_LftFrntDrlPl29Cmd : 39|8@0+ (1,0) [0|100] "%"  LftFrntLCMA
 SG_ LCU_LftFrntDrlPl28Cmd : 31|8@0+ (1,0) [0|100] "%"  LftFrntLCMA
 SG_ LCU_LftFrntDrlPl27Cmd : 23|8@0+ (1,0) [0|100] "%"  LftFrntLCMA
 SG_ LCU_LftFrntDrlPl26Cmd : 15|8@0+ (1,0) [0|100] "%"  LftFrntLCMA
 SG_ LCU_LftFrntDrlPl25Cmd : 7|8@0+ (1,0) [0|100] "%"  LftFrntLCMA

BO_ 477 LCU_FRDrlPl_1: 8 AFL_AHL
 SG_ LCU_RghtFrntDrlpl08Cmd : 63|8@0+ (1,0) [0|100] "%"  RghtFrntLCMA
 SG_ LCU_RghtFrntDrlpl07Cmd : 55|8@0+ (1,0) [0|100] "%"  RghtFrntLCMA
 SG_ LCU_RghtFrntDrlpl06Cmd : 47|8@0+ (1,0) [0|100] "%"  RghtFrntLCMA
 SG_ LCU_RghtFrntDrlpl05Cmd : 39|8@0+ (1,0) [0|100] "%"  RghtFrntLCMA
 SG_ LCU_RghtFrntDrlpl04Cmd : 31|8@0+ (1,0) [0|100] "%"  RghtFrntLCMA
 SG_ LCU_RghtFrntDrlpl03Cmd : 23|8@0+ (1,0) [0|100] "%"  RghtFrntLCMA
 SG_ LCU_RghtFrntDrlpl02Cmd : 15|8@0+ (1,0) [0|100] "%"  RghtFrntLCMA
 SG_ LCU_RghtFrntDrlpl01Cmd : 7|8@0+ (1,0) [0|100] "%"  RghtFrntLCMA

BO_ 482 LCU_FRDrlPl_2: 8 AFL_AHL
 SG_ LCU_RghtFrntDrlpl16Cmd : 63|8@0+ (1,0) [0|100] "%"  RghtFrntLCMA
 SG_ LCU_RghtFrntDrlpl15Cmd : 55|8@0+ (1,0) [0|100] "%"  RghtFrntLCMA
 SG_ LCU_RghtFrntDrlpl14Cmd : 47|8@0+ (1,0) [0|100] "%"  RghtFrntLCMA
 SG_ LCU_RghtFrntDrlpl13Cmd : 39|8@0+ (1,0) [0|100] "%"  RghtFrntLCMA
 SG_ LCU_RghtFrntDrlpl12Cmd : 31|8@0+ (1,0) [0|100] "%"  RghtFrntLCMA
 SG_ LCU_RghtFrntDrlpl11Cmd : 23|8@0+ (1,0) [0|100] "%"  RghtFrntLCMA
 SG_ LCU_RghtFrntDrlpl10Cmd : 15|8@0+ (1,0) [0|100] "%"  RghtFrntLCMA
 SG_ LCU_RghtFrntDrlpl09Cmd : 7|8@0+ (1,0) [0|100] "%"  RghtFrntLCMA

BO_ 487 LCU_FRDrlPl_3: 8 AFL_AHL
 SG_ LCU_RghtFrntDrlpl24Cmd : 63|8@0+ (1,0) [0|100] "%"  RghtFrntLCMA
 SG_ LCU_RghtFrntDrlpl23Cmd : 55|8@0+ (1,0) [0|100] "%"  RghtFrntLCMA
 SG_ LCU_RghtFrntDrlpl22Cmd : 47|8@0+ (1,0) [0|100] "%"  RghtFrntLCMA
 SG_ LCU_RghtFrntDrlpl21Cmd : 39|8@0+ (1,0) [0|100] "%"  RghtFrntLCMA
 SG_ LCU_RghtFrntDrlpl20Cmd : 31|8@0+ (1,0) [0|100] "%"  RghtFrntLCMA
 SG_ LCU_RghtFrntDrlpl19Cmd : 23|8@0+ (1,0) [0|100] "%"  RghtFrntLCMA
 SG_ LCU_RghtFrntDrlpl18Cmd : 15|8@0+ (1,0) [0|100] "%"  RghtFrntLCMA
 SG_ LCU_RghtFrntDrlpl17Cmd : 7|8@0+ (1,0) [0|100] "%"  RghtFrntLCMA

BO_ 492 LCU_FRDrlPl_4: 8 AFL_AHL
 SG_ LCU_RghtFrntDrlpl32Cmd : 63|8@0+ (1,0) [0|100] "%"  RghtFrntLCMA
 SG_ LCU_RghtFrntDrlpl31Cmd : 55|8@0+ (1,0) [0|100] "%"  RghtFrntLCMA
 SG_ LCU_RghtFrntDrlpl30Cmd : 47|8@0+ (1,0) [0|100] "%"  RghtFrntLCMA
 SG_ LCU_RghtFrntDrlpl29Cmd : 39|8@0+ (1,0) [0|100] "%"  RghtFrntLCMA
 SG_ LCU_RghtFrntDrlpl28Cmd : 31|8@0+ (1,0) [0|100] "%"  RghtFrntLCMA
 SG_ LCU_RghtFrntDrlpl27Cmd : 23|8@0+ (1,0) [0|100] "%"  RghtFrntLCMA
 SG_ LCU_RghtFrntDrlpl26Cmd : 15|8@0+ (1,0) [0|100] "%"  RghtFrntLCMA
 SG_ LCU_RghtFrntDrlpl25Cmd : 7|8@0+ (1,0) [0|100] "%"  RghtFrntLCMA

BO_ 505 LCU_ALS_1: 8 AFL_AHL
 SG_ ALS_RghtALSCmdSts : 27|2@0+ (1,0) [0|2] ""  RghtFrntLCMA
 SG_ LCU_RghtALSPosCmd : 9|10@0+ (1,0) [0|1024] ""  RghtFrntLCMA
 SG_ LCU_LftALSCmdSts : 25|2@0+ (1,0) [0|2] ""  LftFrntLCMA
 SG_ LCU_LftALSPosCmd : 7|10@0+ (1,0) [0|1024] ""  LftFrntLCMA

BO_ 785 FLLCM_LCU_2: 8 LftFrntLCMA
 SG_ FLLCM_Mtrx7Lst : 23|1@0+ (1,0) [0|1] ""  LCU
 SG_ FLLCM_Ntc8Err : 55|1@0+ (1,0) [0|1] ""  LCU
 SG_ FLLCM_Ntc7Err : 54|1@0+ (1,0) [0|1] ""  LCU
 SG_ FLLCM_Ntc6Err : 53|1@0+ (1,0) [0|1] ""  LCU
 SG_ FLLCM_Ntc5Err : 52|1@0+ (1,0) [0|1] ""  LCU
 SG_ FLLCM_Ntc4Err : 51|1@0+ (1,0) [0|1] ""  LCU
 SG_ FLLCM_Ntc3Err : 50|1@0+ (1,0) [0|1] ""  LCU
 SG_ FLLCM_Ntc2Err : 49|1@0+ (1,0) [0|1] ""  LCU
 SG_ FLLCM_Ntc1Err : 48|1@0+ (1,0) [0|1] ""  LCU
 SG_ FLLCM_Bin8Err : 47|1@0+ (1,0) [0|1] ""  LCU
 SG_ FLLCM_Bin7Err : 46|1@0+ (1,0) [0|1] ""  LCU
 SG_ FLLCM_Bin6Err : 45|1@0+ (1,0) [0|1] ""  LCU
 SG_ FLLCM_Bin5Err : 44|1@0+ (1,0) [0|1] ""  LCU
 SG_ FLLCM_Bin4Err : 43|1@0+ (1,0) [0|1] ""  LCU
 SG_ FLLCM_Bin3Err : 42|1@0+ (1,0) [0|1] ""  LCU
 SG_ FLLCM_Bin2Err : 41|1@0+ (1,0) [0|1] ""  LCU
 SG_ FLLCM_Bin1Err : 40|1@0+ (1,0) [0|1] ""  LCU
 SG_ FLLCM_Hsd4Err : 35|1@0+ (1,0) [0|1] ""  LCU
 SG_ FLLCM_Hsd3Err : 34|1@0+ (1,0) [0|1] ""  LCU
 SG_ FLLCM_Hsd2Err : 33|1@0+ (1,0) [0|1] ""  LCU
 SG_ FLLCM_Hsd1Err : 32|1@0+ (1,0) [0|1] ""  LCU
 SG_ FLLCM_Mtrx7LedErr : 31|1@0+ (1,0) [0|1] ""  LCU
 SG_ FLLCM_Mtrx6LedErr : 30|1@0+ (1,0) [0|1] ""  LCU
 SG_ FLLCM_Mtrx5LedErr : 29|1@0+ (1,0) [0|1] ""  LCU
 SG_ FLLCM_Mtrx3LedErr : 28|1@0+ (1,0) [0|1] ""  LCU
 SG_ FLLCM_Mtrx4LedErr : 27|1@0+ (1,0) [0|1] ""  LCU
 SG_ FLLCM_Mtrx2LedErr : 26|1@0+ (1,0) [0|1] ""  LCU
 SG_ FLLCM_Mtrx1LedErr : 25|1@0+ (1,0) [0|1] ""  LCU
 SG_ FLLCM_Mtrx0LedErr : 24|1@0+ (1,0) [0|1] ""  LCU
 SG_ FLLCM_Mtrx6Lst : 22|1@0+ (1,0) [0|1] ""  LCU
 SG_ FLLCM_Mtrx5Lst : 21|1@0+ (1,0) [0|1] ""  LCU
 SG_ FLLCM_Mtrx4Lst : 20|1@0+ (1,0) [0|1] ""  LCU
 SG_ FLLCM_Mtrx3Lst : 19|1@0+ (1,0) [0|1] ""  LCU
 SG_ FLLCM_Mtrx2Lst : 18|1@0+ (1,0) [0|1] ""  LCU
 SG_ FLLCM_Mtrx1Lst : 17|1@0+ (1,0) [0|1] ""  LCU
 SG_ FLLCM_Mtrx0Lst : 16|1@0+ (1,0) [0|1] ""  LCU
 SG_ FLLCM_Ch8Err : 15|1@0+ (1,0) [0|1] ""  LCU
 SG_ FLLCM_Ch7Err : 14|1@0+ (1,0) [0|1] ""  LCU
 SG_ FLLCM_Ch6Err : 13|1@0+ (1,0) [0|1] ""  LCU
 SG_ FLLCM_Ch5Err : 12|1@0+ (1,0) [0|1] ""  LCU
 SG_ FLLCM_Ch4Err : 11|1@0+ (1,0) [0|1] ""  LCU
 SG_ FLLCM_Ch3Err : 10|1@0+ (1,0) [0|1] ""  LCU
 SG_ FLLCM_Ch2Err : 9|1@0+ (1,0) [0|1] ""  LCU
 SG_ FLLCM_Ch1Err : 8|1@0+ (1,0) [0|1] ""  LCU
 SG_ FLLCM_MtrInnErr : 7|1@0+ (1,0) [0|1] ""  LCU
 SG_ FLLCM_MtrPwrErr : 6|1@0+ (1,0) [0|1] ""  LCU
 SG_ FLLCM_LinLst : 5|1@0+ (1,0) [0|1] ""  LCU
 SG_ FLLCM_LdoErr : 4|1@0+ (1,0) [0|1] ""  LCU
 SG_ FLLCM_LostLCU : 3|1@0+ (1,0) [0|1] ""  LCU
 SG_ FLLCM_BusOff : 2|1@0+ (1,0) [0|1] ""  LCU
 SG_ FLLCM_Uv : 1|1@0+ (1,0) [0|1] ""  LCU
 SG_ FLLCM_Ov : 0|1@0+ (1,0) [0|1] ""  LCU

BO_ 786 FLLCMBHwSts: 8 LftFrntLCMB
 SG_ SysSts_FLLCMB : 7|64@0+ (1,0) [0|0] ""  AFL_AHL

BO_ 787 FRLCM_LCU_2: 8 RghtFrntLCMA
 SG_ FRLCM_Ntc8Err : 55|1@0+ (1,0) [0|1] ""  LCU
 SG_ FRLCM_Ntc7Err : 54|1@0+ (1,0) [0|1] ""  LCU
 SG_ FRLCM_Ntc6Err : 53|1@0+ (1,0) [0|1] ""  LCU
 SG_ FRLCM_Ntc5Err : 52|1@0+ (1,0) [0|1] ""  LCU
 SG_ FRLCM_Ntc4Err : 51|1@0+ (1,0) [0|1] ""  LCU
 SG_ FRLCM_Ntc3Err : 50|1@0+ (1,0) [0|1] ""  LCU
 SG_ FRLCM_Ntc2Err : 49|1@0+ (1,0) [0|1] ""  LCU
 SG_ FRLCM_Ntc1Err : 48|1@0+ (1,0) [0|1] ""  LCU
 SG_ FRLCM_Bin8Err : 47|1@0+ (1,0) [0|1] ""  LCU
 SG_ FRLCM_Bin7Err : 46|1@0+ (1,0) [0|1] ""  LCU
 SG_ FRLCM_Bin6Err : 45|1@0+ (1,0) [0|1] ""  LCU
 SG_ FRLCM_Bin5Err : 44|1@0+ (1,0) [0|1] ""  LCU
 SG_ FRLCM_Bin3Err : 42|1@0+ (1,0) [0|1] ""  LCU
 SG_ FRLCM_Bin4Err : 43|1@0+ (1,0) [0|1] ""  LCU
 SG_ FRLCM_Bin2Err : 41|1@0+ (1,0) [0|1] ""  LCU
 SG_ FRLCM_Bin1Err : 40|1@0+ (1,0) [0|1] ""  LCU
 SG_ FRLCM_Hsd3Err : 34|1@0+ (1,0) [0|1] ""  LCU
 SG_ FRLCM_Hsd2Err : 33|1@0+ (1,0) [0|1] ""  LCU
 SG_ FRLCM_Hsd1Err : 32|1@0+ (1,0) [0|1] ""  LCU
 SG_ FRLCM_Hsd4Err : 35|1@0+ (1,0) [0|1] ""  LCU
 SG_ FRLCM_Mtrx7LedErr : 31|1@0+ (1,0) [0|1] ""  LCU
 SG_ FRLCM_Mtrx6LedErr : 30|1@0+ (1,0) [0|1] ""  LCU
 SG_ FRLCM_Mtrx5LedErr : 29|1@0+ (1,0) [0|1] ""  LCU
 SG_ FRLCM_Mtrx4LedErr : 28|1@0+ (1,0) [0|1] ""  LCU
 SG_ FRLCM_Mtrx3LedErr : 27|1@0+ (1,0) [0|1] ""  LCU
 SG_ FRLCM_Mtrx2LedErr : 26|1@0+ (1,0) [0|1] ""  LCU
 SG_ FRLCM_Mtrx1LedErr : 25|1@0+ (1,0) [0|1] ""  LCU
 SG_ FRLCM_Mtrx0LedErr : 24|1@0+ (1,0) [0|1] ""  LCU
 SG_ FRLCM_Mtrx7Lst : 23|1@0+ (1,0) [0|1] ""  LCU
 SG_ FRLCM_Mtrx6Lst : 22|1@0+ (1,0) [0|1] ""  LCU
 SG_ FRLCM_Mtrx5Lst : 21|1@0+ (1,0) [0|1] ""  LCU
 SG_ FRLCM_Mtrx4Lst : 20|1@0+ (1,0) [0|1] ""  LCU
 SG_ FRLCM_Mtrx3Lst : 19|1@0+ (1,0) [0|1] ""  LCU
 SG_ FRLCM_Mtrx2Lst : 18|1@0+ (1,0) [0|1] ""  LCU
 SG_ FRLCM_Mtrx1Lst : 17|1@0+ (1,0) [0|1] ""  LCU
 SG_ FRLCM_Mtrx0Lst : 16|1@0+ (1,0) [0|1] ""  LCU
 SG_ FRLCM_Ch8Err : 15|1@0+ (1,0) [0|1] ""  LCU
 SG_ FRLCM_Ch7Err : 14|1@0+ (1,0) [0|1] ""  LCU
 SG_ FRLCM_Ch6Err : 13|1@0+ (1,0) [0|1] ""  LCU
 SG_ FRLCM_Ch5Err : 12|1@0+ (1,0) [0|1] ""  LCU
 SG_ FRLCM_Ch4Err : 11|1@0+ (1,0) [0|1] ""  LCU
 SG_ FRLCM_Ch3Err : 10|1@0+ (1,0) [0|1] ""  LCU
 SG_ FRLCM_Ch2Err : 9|1@0+ (1,0) [0|1] ""  LCU
 SG_ FRLCM_Ch1Err : 8|1@0+ (1,0) [0|1] ""  LCU
 SG_ FRLCM_MtrInnErr : 7|1@0+ (1,0) [0|1] ""  LCU
 SG_ FRLCM_MtrPwrErr : 6|1@0+ (1,0) [0|1] ""  LCU
 SG_ FRLCM_LinLst : 5|1@0+ (1,0) [0|1] ""  LCU
 SG_ FRLCM_LdoErr : 4|1@0+ (1,0) [0|1] ""  LCU
 SG_ FRLCM_LostLCU : 3|1@0+ (1,0) [0|1] ""  LCU
 SG_ FRLCM_BusOff : 2|1@0+ (1,0) [0|1] ""  LCU
 SG_ FRLCM_Uv : 1|1@0+ (1,0) [0|1] ""  LCU
 SG_ FRLCM_Ov : 0|1@0+ (1,0) [0|1] ""  LCU,AFL_AHL

BO_ 788 FRLCMBHwSts: 8 RghtFrntLCMB
 SG_ SysSts_FRLCMB : 7|64@0+ (1,0) [0|0] ""  AFL_AHL

BO_ 789 RLLCMAHwSts: 8 LftRrLCMA
 SG_ SysSts_RLLCMA : 7|32@0+ (1,0) [0|0] ""  AFL_AHL

BO_ 791 RLLCMBHwSts: 8 LftRrLCMB
 SG_ SysSts_RLLCMB : 7|32@0+ (1,0) [0|0] ""  AFL_AHL

BO_ 790 RRLCMAHwSts: 8 RghtRrLCMA
 SG_ SysSts_RRLCMA : 7|32@0+ (1,0) [0|0] ""  AFL_AHL

BO_ 792 RRLCMBHwSts: 8 RghtRrLCMB
 SG_ SysSts_RRLCMB : 7|32@0+ (1,0) [0|0] ""  AFL_AHL

EV_ AHL: 0 [0|0] "" 0 1 DUMMY_NODE_VECTOR0 Vector__XXX;

CM_ BO_ 3221225472 "This is a message for not used signals, created by Vector CANdb++ DBC OLE DB Provider.";
CM_ SG_ 3221225472 LftRCPlLed064 "Dynamic Bending Light System Information : Dynamic Bending Light System Information Cksm";
CM_ SG_ 3221225472 LftRCPlLed063 "Dynamic Bending Light System Information : Dynamic Bending Light System Information Cksm";
CM_ SG_ 3221225472 LftRCPlLed062 "Dynamic Bending Light System Information : Dynamic Bending Light System Information Cksm";
CM_ SG_ 3221225472 LftRCPlLed061 "Dynamic Bending Light System Information : Dynamic Bending Light System Information Cksm";
CM_ SG_ 3221225472 LftRCPlLed060 "Dynamic Bending Light System Information : Dynamic Bending Light System Information Cksm";
CM_ SG_ 3221225472 LftRCPlLed059 "Dynamic Bending Light System Information : Dynamic Bending Light System Information Cksm";
CM_ SG_ 3221225472 LftRCPlLed058 "Dynamic Bending Light System Information : Dynamic Bending Light System Information Cksm";
CM_ SG_ 3221225472 LftRCPlLed057 "Dynamic Bending Light System Information : Dynamic Bending Light System Information Cksm";
CM_ SG_ 3221225472 LftRCPlLed056 "Dynamic Bending Light System Information : Dynamic Bending Light System Information Cksm";
CM_ SG_ 3221225472 LftRCPlLed055 "Dynamic Bending Light System Information : Dynamic Bending Light System Information Cksm";
CM_ SG_ 3221225472 LftRCPlLed054 "Dynamic Bending Light System Information : Dynamic Bending Light System Information Cksm";
CM_ SG_ 3221225472 LftRCPlLed053 "Dynamic Bending Light System Information : Dynamic Bending Light System Information Cksm";
CM_ SG_ 3221225472 LftRCPlLed052 "Dynamic Bending Light System Information : Dynamic Bending Light System Information Cksm";
CM_ SG_ 3221225472 LftRCPlLed051 "Dynamic Bending Light System Information : Dynamic Bending Light System Information Cksm";
CM_ SG_ 3221225472 LftRCPlLed050 "Dynamic Bending Light System Information : Dynamic Bending Light System Information Cksm";
CM_ SG_ 3221225472 LftRCPlLed049 "Dynamic Bending Light System Information : Dynamic Bending Light System Information Cksm";
CM_ SG_ 3221225472 RghtRCPlLed033 "Dynamic Bending Light System Information : Dynamic Bending Light System Information Cksm";
CM_ SG_ 3221225472 RghtRCPlLed063 "Dynamic Bending Light System Information : Dynamic Bending Light System Information Cksm";
CM_ SG_ 3221225472 RghtRCPlLed061 "Dynamic Bending Light System Information : Dynamic Bending Light System Information Cksm";
CM_ SG_ 3221225472 RghtRCPlLed062 "Dynamic Bending Light System Information : Dynamic Bending Light System Information Cksm";
CM_ SG_ 3221225472 RghtRCPlLed060 "Dynamic Bending Light System Information : Dynamic Bending Light System Information Cksm";
CM_ SG_ 3221225472 RghtRCPlLed059 "Dynamic Bending Light System Information : Dynamic Bending Light System Information Cksm";
CM_ SG_ 3221225472 RghtRCPlLed057 "Dynamic Bending Light System Information : Dynamic Bending Light System Information Cksm";
CM_ SG_ 3221225472 RghtRCPlLed056 "Dynamic Bending Light System Information : Dynamic Bending Light System Information Cksm";
CM_ SG_ 3221225472 RghtRCPlLed055 "Dynamic Bending Light System Information : Dynamic Bending Light System Information Cksm";
CM_ SG_ 3221225472 RghtRCPlLed054 "Dynamic Bending Light System Information : Dynamic Bending Light System Information Cksm";
CM_ SG_ 3221225472 RghtRCPlLed053 "Dynamic Bending Light System Information : Dynamic Bending Light System Information Cksm";
CM_ SG_ 3221225472 RghtRCPlLed052 "Dynamic Bending Light System Information : Dynamic Bending Light System Information Cksm";
CM_ SG_ 3221225472 RghtRCPlLed051 "Dynamic Bending Light System Information : Dynamic Bending Light System Information Cksm";
CM_ SG_ 3221225472 RghtRCPlLed050 "Dynamic Bending Light System Information : Dynamic Bending Light System Information Cksm";
CM_ SG_ 3221225472 RghtRCPlLed049 "Dynamic Bending Light System Information : Dynamic Bending Light System Information Cksm";
CM_ SG_ 3221225472 RghtRCPlLed048 "Dynamic Bending Light System Information : Dynamic Bending Light System Information Cksm";
CM_ SG_ 3221225472 RghtRCPlLed046 "Dynamic Bending Light System Information : Dynamic Bending Light System Information Cksm";
CM_ SG_ 3221225472 RghtRCPlLed045 "Dynamic Bending Light System Information : Dynamic Bending Light System Information Cksm";
CM_ SG_ 3221225472 RghtRCPlLed044 "Dynamic Bending Light System Information : Dynamic Bending Light System Information Cksm";
CM_ SG_ 3221225472 RghtRCPlLed043 "Dynamic Bending Light System Information : Dynamic Bending Light System Information Cksm";
CM_ SG_ 3221225472 RghtRCPlLed042 "Dynamic Bending Light System Information : Dynamic Bending Light System Information Cksm";
CM_ SG_ 3221225472 RghtRCPlLed041 "Dynamic Bending Light System Information : Dynamic Bending Light System Information Cksm";
CM_ SG_ 3221225472 RghtRCPlLed040 "Dynamic Bending Light System Information : Dynamic Bending Light System Information Cksm";
CM_ SG_ 3221225472 RghtRCPlLed039 "Dynamic Bending Light System Information : Dynamic Bending Light System Information Cksm";
CM_ SG_ 3221225472 RghtRCPlLed038 "Dynamic Bending Light System Information : Dynamic Bending Light System Information Cksm";
CM_ SG_ 3221225472 RghtRCPlLed037 "Dynamic Bending Light System Information : Dynamic Bending Light System Information Cksm";
CM_ SG_ 3221225472 RghtRCPlLed035 "Dynamic Bending Light System Information : Dynamic Bending Light System Information Cksm";
CM_ SG_ 3221225472 RghtRCPlLed034 "Dynamic Bending Light System Information : Dynamic Bending Light System Information Cksm";
CM_ SG_ 3221225472 RghtRCPlLed032 "Dynamic Bending Light System Information : Dynamic Bending Light System Information Cksm";
CM_ SG_ 3221225472 RghtRCPlLed031 "Dynamic Bending Light System Information : Dynamic Bending Light System Information Cksm";
CM_ SG_ 3221225472 RghtRCPlLed030 "Dynamic Bending Light System Information : Dynamic Bending Light System Information Cksm";
CM_ SG_ 3221225472 RghtRCPlLed029 "Dynamic Bending Light System Information : Dynamic Bending Light System Information Cksm";
CM_ SG_ 3221225472 RghtRCPlLed028 "Dynamic Bending Light System Information : Dynamic Bending Light System Information Cksm";
CM_ SG_ 3221225472 RghtRCPlLed027 "Dynamic Bending Light System Information : Dynamic Bending Light System Information Cksm";
CM_ SG_ 3221225472 RghtRCPlLed026 "Dynamic Bending Light System Information : Dynamic Bending Light System Information Cksm";
CM_ SG_ 3221225472 RghtRCPlLed025 "Dynamic Bending Light System Information : Dynamic Bending Light System Information Cksm";
CM_ SG_ 3221225472 RghtRCPlLed023 "Dynamic Bending Light System Information : Dynamic Bending Light System Information Cksm";
CM_ SG_ 3221225472 RghtRCPlLed022 "Dynamic Bending Light System Information : Dynamic Bending Light System Information Cksm";
CM_ SG_ 3221225472 RghtRCPlLed021 "Dynamic Bending Light System Information : Dynamic Bending Light System Information Cksm";
CM_ SG_ 3221225472 RghtRCPlLed020 "Dynamic Bending Light System Information : Dynamic Bending Light System Information Cksm";
CM_ SG_ 3221225472 RghtRCPlLed019 "Dynamic Bending Light System Information : Dynamic Bending Light System Information Cksm";
CM_ SG_ 3221225472 RghtRCPlLed018 "Dynamic Bending Light System Information : Dynamic Bending Light System Information Cksm";
CM_ SG_ 3221225472 RghtRCPlLed017 "Dynamic Bending Light System Information : Dynamic Bending Light System Information Cksm";
CM_ SG_ 3221225472 RghtRCPlLed016 "Dynamic Bending Light System Information : Dynamic Bending Light System Information Cksm";
CM_ SG_ 3221225472 RghtRCPlLed015 "Dynamic Bending Light System Information : Dynamic Bending Light System Information Cksm";
CM_ SG_ 3221225472 RghtRCPlLed014 "Dynamic Bending Light System Information : Dynamic Bending Light System Information Cksm";
CM_ SG_ 3221225472 RghtRCPlLed012 "Dynamic Bending Light System Information : Dynamic Bending Light System Information Cksm";
CM_ SG_ 3221225472 RghtRCPlLed011 "Dynamic Bending Light System Information : Dynamic Bending Light System Information Cksm";
CM_ SG_ 3221225472 RghtRCPlLed010 "Dynamic Bending Light System Information : Dynamic Bending Light System Information Cksm";
CM_ SG_ 3221225472 RghtRCPlLed009 "Dynamic Bending Light System Information : Dynamic Bending Light System Information Cksm";
CM_ SG_ 3221225472 RghtRCPlLed008 "Dynamic Bending Light System Information : Dynamic Bending Light System Information Cksm";
CM_ SG_ 3221225472 RghtRCPlLed007 "Dynamic Bending Light System Information : Dynamic Bending Light System Information Cksm";
CM_ SG_ 3221225472 RghtRCPlLed006 "Dynamic Bending Light System Information : Dynamic Bending Light System Information Cksm";
CM_ SG_ 3221225472 RghtRCPlLed005 "Dynamic Bending Light System Information : Dynamic Bending Light System Information Cksm";
CM_ SG_ 3221225472 RghtRCPlLed004 "Dynamic Bending Light System Information : Dynamic Bending Light System Information Cksm";
CM_ SG_ 3221225472 RghtRCPlLed003 "Dynamic Bending Light System Information : Dynamic Bending Light System Information Cksm";
CM_ SG_ 3221225472 RghtRCPlLed064 "Dynamic Bending Light System Information : Dynamic Bending Light System Information Cksm";
CM_ SG_ 3221225472 RghtRCPlLed058 "Dynamic Bending Light System Information : Dynamic Bending Light System Information Cksm";
CM_ SG_ 3221225472 RghtRCPlLed047 "Dynamic Bending Light System Information : Dynamic Bending Light System Information Cksm";
CM_ SG_ 3221225472 RghtRCPlLed036 "Dynamic Bending Light System Information : Dynamic Bending Light System Information Cksm";
CM_ SG_ 3221225472 RghtRCPlLed024 "Dynamic Bending Light System Information : Dynamic Bending Light System Information Cksm";
CM_ SG_ 3221225472 RghtRCPlLed013 "Dynamic Bending Light System Information : Dynamic Bending Light System Information Cksm";
CM_ SG_ 3221225472 RghtRCPlLed002 "Dynamic Bending Light System Information : Dynamic Bending Light System Information Cksm";
CM_ SG_ 3221225472 RghtRCPlLed001 "Dynamic Bending Light System Information : Dynamic Bending Light System Information Cksm";
CM_ SG_ 3221225472 LftRPlLed056 "Dynamic Bending Light System Information : Dynamic Bending Light System Information Cksm";
CM_ SG_ 3221225472 LftRPlLed055 "Dynamic Bending Light System Information : Dynamic Bending Light System Information Cksm";
CM_ SG_ 3221225472 LftRPlLed054 "Dynamic Bending Light System Information : Dynamic Bending Light System Information Cksm";
CM_ SG_ 3221225472 LftRPlLed053 "Dynamic Bending Light System Information : Dynamic Bending Light System Information Cksm";
CM_ SG_ 3221225472 LftRPlLed052 "Dynamic Bending Light System Information : Dynamic Bending Light System Information Cksm";
CM_ SG_ 3221225472 LftRPlLed051 "Dynamic Bending Light System Information : Dynamic Bending Light System Information Cksm";
CM_ SG_ 3221225472 LftRPlLed050 "Dynamic Bending Light System Information : Dynamic Bending Light System Information Cksm";
CM_ SG_ 3221225472 LftRPlLed049 "Dynamic Bending Light System Information : Dynamic Bending Light System Information Cksm";
CM_ SG_ 3221225472 LftRPlLed048 "Dynamic Bending Light System Information : Dynamic Bending Light System Information Cksm";
CM_ SG_ 3221225472 LftRPlLed047 "Dynamic Bending Light System Information : Dynamic Bending Light System Information Cksm";
CM_ SG_ 3221225472 LftRPlLed046 "Dynamic Bending Light System Information : Dynamic Bending Light System Information Cksm";
CM_ SG_ 3221225472 LftRPlLed045 "Dynamic Bending Light System Information : Dynamic Bending Light System Information Cksm";
CM_ SG_ 3221225472 LftRPlLed044 "Dynamic Bending Light System Information : Dynamic Bending Light System Information Cksm";
CM_ SG_ 3221225472 LftRPlLed043 "Dynamic Bending Light System Information : Dynamic Bending Light System Information Cksm";
CM_ SG_ 3221225472 LftRPlLed042 "Dynamic Bending Light System Information : Dynamic Bending Light System Information Cksm";
CM_ SG_ 3221225472 LftRPlLed041 "Dynamic Bending Light System Information : Dynamic Bending Light System Information Cksm";
CM_ SG_ 3221225472 LftRPlLed040 "Dynamic Bending Light System Information : Dynamic Bending Light System Information Cksm";
CM_ SG_ 3221225472 LftRPlLed039 "Dynamic Bending Light System Information : Dynamic Bending Light System Information Cksm";
CM_ SG_ 3221225472 LftRPlLed038 "Dynamic Bending Light System Information : Dynamic Bending Light System Information Cksm";
CM_ SG_ 3221225472 LftRPlLed037 "Dynamic Bending Light System Information : Dynamic Bending Light System Information Cksm";
CM_ SG_ 3221225472 LftRPlLed036 "Dynamic Bending Light System Information : Dynamic Bending Light System Information Cksm";
CM_ SG_ 3221225472 LftRPlLed035 "Dynamic Bending Light System Information : Dynamic Bending Light System Information Cksm";
CM_ SG_ 3221225472 LftRPlLed034 "Dynamic Bending Light System Information : Dynamic Bending Light System Information Cksm";
CM_ SG_ 3221225472 LftRPlLed033 "Dynamic Bending Light System Information : Dynamic Bending Light System Information Cksm";
CM_ SG_ 3221225472 RghtRPlLed064 "Dynamic Bending Light System Information : Dynamic Bending Light System Information Cksm";
CM_ SG_ 3221225472 RghtRPlLed063 "Dynamic Bending Light System Information : Dynamic Bending Light System Information Cksm";
CM_ SG_ 3221225472 RghtRPlLed062 "Dynamic Bending Light System Information : Dynamic Bending Light System Information Cksm";
CM_ SG_ 3221225472 RghtRPlLed061 "Dynamic Bending Light System Information : Dynamic Bending Light System Information Cksm";
CM_ SG_ 3221225472 RghtRPlLed060 "Dynamic Bending Light System Information : Dynamic Bending Light System Information Cksm";
CM_ SG_ 3221225472 RghtRPlLed059 "Dynamic Bending Light System Information : Dynamic Bending Light System Information Cksm";
CM_ SG_ 3221225472 RghtRPlLed058 "Dynamic Bending Light System Information : Dynamic Bending Light System Information Cksm";
CM_ SG_ 3221225472 RghtRPlLed057 "Dynamic Bending Light System Information : Dynamic Bending Light System Information Cksm";
CM_ SG_ 3221225472 RghtRPlLed056 "Dynamic Bending Light System Information : Dynamic Bending Light System Information Cksm";
CM_ SG_ 3221225472 RghtRPlLed055 "Dynamic Bending Light System Information : Dynamic Bending Light System Information Cksm";
CM_ SG_ 3221225472 RghtRPlLed054 "Dynamic Bending Light System Information : Dynamic Bending Light System Information Cksm";
CM_ SG_ 3221225472 RghtRPlLed053 "Dynamic Bending Light System Information : Dynamic Bending Light System Information Cksm";
CM_ SG_ 3221225472 RghtRPlLed052 "Dynamic Bending Light System Information : Dynamic Bending Light System Information Cksm";
CM_ SG_ 3221225472 RghtRPlLed051 "Dynamic Bending Light System Information : Dynamic Bending Light System Information Cksm";
CM_ SG_ 3221225472 RghtRPlLed050 "Dynamic Bending Light System Information : Dynamic Bending Light System Information Cksm";
CM_ SG_ 3221225472 RghtRPlLed049 "Dynamic Bending Light System Information : Dynamic Bending Light System Information Cksm";
CM_ SG_ 3221225472 RghtRPlLed048 "Dynamic Bending Light System Information : Dynamic Bending Light System Information Cksm";
CM_ SG_ 3221225472 RghtRPlLed047 "Dynamic Bending Light System Information : Dynamic Bending Light System Information Cksm";
CM_ SG_ 3221225472 RghtRPlLed046 "Dynamic Bending Light System Information : Dynamic Bending Light System Information Cksm";
CM_ SG_ 3221225472 RghtRPlLed045 "Dynamic Bending Light System Information : Dynamic Bending Light System Information Cksm";
CM_ SG_ 3221225472 RghtRPlLed044 "Dynamic Bending Light System Information : Dynamic Bending Light System Information Cksm";
CM_ SG_ 3221225472 RghtRPlLed043 "Dynamic Bending Light System Information : Dynamic Bending Light System Information Cksm";
CM_ SG_ 3221225472 RghtRPlLed042 "Dynamic Bending Light System Information : Dynamic Bending Light System Information Cksm";
CM_ SG_ 3221225472 RghtRPlLed041 "Dynamic Bending Light System Information : Dynamic Bending Light System Information Cksm";
CM_ SG_ 3221225472 RghtRPlLed040 "Dynamic Bending Light System Information : Dynamic Bending Light System Information Cksm";
CM_ SG_ 3221225472 RghtRPlLed039 "Dynamic Bending Light System Information : Dynamic Bending Light System Information Cksm";
CM_ SG_ 3221225472 RghtRPlLed038 "Dynamic Bending Light System Information : Dynamic Bending Light System Information Cksm";
CM_ SG_ 3221225472 RghtRPlLed037 "Dynamic Bending Light System Information : Dynamic Bending Light System Information Cksm";
CM_ SG_ 3221225472 RghtRPlLed036 "Dynamic Bending Light System Information : Dynamic Bending Light System Information Cksm";
CM_ SG_ 3221225472 RghtRPlLed035 "Dynamic Bending Light System Information : Dynamic Bending Light System Information Cksm";
CM_ SG_ 3221225472 RghtRPlLed034 "Dynamic Bending Light System Information : Dynamic Bending Light System Information Cksm";
CM_ SG_ 3221225472 RghtRPlLed033 "Dynamic Bending Light System Information : Dynamic Bending Light System Information Cksm";
CM_ SG_ 3221225472 LftRPlLed064 "Dynamic Bending Light System Information : Dynamic Bending Light System Information Cksm";
CM_ SG_ 3221225472 LftRPlLed063 "Dynamic Bending Light System Information : Dynamic Bending Light System Information Cksm";
CM_ SG_ 3221225472 LftRPlLed062 "Dynamic Bending Light System Information : Dynamic Bending Light System Information Cksm";
CM_ SG_ 3221225472 LftRPlLed061 "Dynamic Bending Light System Information : Dynamic Bending Light System Information Cksm";
CM_ SG_ 3221225472 LftRPlLed060 "Dynamic Bending Light System Information : Dynamic Bending Light System Information Cksm";
CM_ SG_ 3221225472 LftRPlLed059 "Dynamic Bending Light System Information : Dynamic Bending Light System Information Cksm";
CM_ SG_ 3221225472 LftRPlLed058 "Dynamic Bending Light System Information : Dynamic Bending Light System Information Cksm";
CM_ SG_ 3221225472 LftRPlLed057 "Dynamic Bending Light System Information : Dynamic Bending Light System Information Cksm";
CM_ SG_ 3221225472 RghtFCPlLed040 "Dynamic Bending Light System Information : Dynamic Bending Light System Information Cksm";
CM_ SG_ 3221225472 RghtFCPlLed039 "Dynamic Bending Light System Information : Dynamic Bending Light System Information Cksm";
CM_ SG_ 3221225472 RghtFCPlLed038 "Dynamic Bending Light System Information : Dynamic Bending Light System Information Cksm";
CM_ SG_ 3221225472 RghtFCPlLed037 "Dynamic Bending Light System Information : Dynamic Bending Light System Information Cksm";
CM_ SG_ 3221225472 RghtFCPlLed036 "Dynamic Bending Light System Information : Dynamic Bending Light System Information Cksm";
CM_ SG_ 3221225472 RghtFCPlLed035 "Dynamic Bending Light System Information : Dynamic Bending Light System Information Cksm";
CM_ SG_ 3221225472 RghtFCPlLed034 "Dynamic Bending Light System Information : Dynamic Bending Light System Information Cksm";
CM_ SG_ 3221225472 RghtFCPlLed033 "Dynamic Bending Light System Information : Dynamic Bending Light System Information Cksm";
CM_ SG_ 3221225472 RghtFCPlLed008 "Dynamic Bending Light System Information : Dynamic Bending Light System Information Cksm";
CM_ SG_ 3221225472 RghtFCPlLed007 "Dynamic Bending Light System Information : Dynamic Bending Light System Information Cksm";
CM_ SG_ 3221225472 RghtFCPlLed006 "Dynamic Bending Light System Information : Dynamic Bending Light System Information Cksm";
CM_ SG_ 3221225472 RghtFCPlLed005 "Dynamic Bending Light System Information : Dynamic Bending Light System Information Cksm";
CM_ SG_ 3221225472 RghtFCPlLed004 "Dynamic Bending Light System Information : Dynamic Bending Light System Information Cksm";
CM_ SG_ 3221225472 RghtFCPlLed003 "Dynamic Bending Light System Information : Dynamic Bending Light System Information Cksm";
CM_ SG_ 3221225472 RghtFCPlLed002 "Dynamic Bending Light System Information : Dynamic Bending Light System Information Cksm";
CM_ SG_ 3221225472 RghtFCPlLed001 "Dynamic Bending Light System Information : Dynamic Bending Light System Information Cksm";
CM_ SG_ 3221225472 LftFCPlLed040 "Dynamic Bending Light System Information : Dynamic Bending Light System Information Cksm";
CM_ SG_ 3221225472 LftFCPlLed039 "Dynamic Bending Light System Information : Dynamic Bending Light System Information Cksm";
CM_ SG_ 3221225472 LftFCPlLed038 "Dynamic Bending Light System Information : Dynamic Bending Light System Information Cksm";
CM_ SG_ 3221225472 LftFCPlLed037 "Dynamic Bending Light System Information : Dynamic Bending Light System Information Cksm";
CM_ SG_ 3221225472 LftFCPlLed036 "Dynamic Bending Light System Information : Dynamic Bending Light System Information Cksm";
CM_ SG_ 3221225472 LftFCPlLed035 "Dynamic Bending Light System Information : Dynamic Bending Light System Information Cksm";
CM_ SG_ 3221225472 LftFCPlLed034 "Dynamic Bending Light System Information : Dynamic Bending Light System Information Cksm";
CM_ SG_ 3221225472 LftFCPlLed033 "Dynamic Bending Light System Information : Dynamic Bending Light System Information Cksm";
CM_ SG_ 3221225472 LftFCPlLed024 "Dynamic Bending Light System Information : Dynamic Bending Light System Information Cksm";
CM_ SG_ 3221225472 LftFCPlLed023 "Dynamic Bending Light System Information : Dynamic Bending Light System Information Cksm";
CM_ SG_ 3221225472 LftFCPlLed022 "Dynamic Bending Light System Information : Dynamic Bending Light System Information Cksm";
CM_ SG_ 3221225472 LftFCPlLed021 "Dynamic Bending Light System Information : Dynamic Bending Light System Information Cksm";
CM_ SG_ 3221225472 LftFCPlLed020 "Dynamic Bending Light System Information : Dynamic Bending Light System Information Cksm";
CM_ SG_ 3221225472 LftFCPlLed019 "Dynamic Bending Light System Information : Dynamic Bending Light System Information Cksm";
CM_ SG_ 3221225472 LftFCPlLed018 "Dynamic Bending Light System Information : Dynamic Bending Light System Information Cksm";
CM_ SG_ 3221225472 LftFCPlLed017 "Dynamic Bending Light System Information : Dynamic Bending Light System Information Cksm";
CM_ SG_ 3221225472 RghtRTrnLed040 "Dynamic Bending Light System Information : Dynamic Bending Light System Information Cksm";
CM_ SG_ 3221225472 RghtRTrnLed039 "Dynamic Bending Light System Information : Dynamic Bending Light System Information Cksm";
CM_ SG_ 3221225472 RghtRTrnLed038 "Dynamic Bending Light System Information : Dynamic Bending Light System Information Cksm";
CM_ SG_ 3221225472 RghtRTrnLed037 "Dynamic Bending Light System Information : Dynamic Bending Light System Information Cksm";
CM_ SG_ 3221225472 RghtRTrnLed036 "Dynamic Bending Light System Information : Dynamic Bending Light System Information Cksm";
CM_ SG_ 3221225472 RghtRTrnLed035 "Dynamic Bending Light System Information : Dynamic Bending Light System Information Cksm";
CM_ SG_ 3221225472 RghtRTrnLed034 "Dynamic Bending Light System Information : Dynamic Bending Light System Information Cksm";
CM_ SG_ 3221225472 RghtRTrnLed033 "Dynamic Bending Light System Information : Dynamic Bending Light System Information Cksm";
CM_ SG_ 3221225472 LftRTrnLed040 "Dynamic Bending Light System Information : Dynamic Bending Light System Information Cksm";
CM_ SG_ 3221225472 LftRTrnLed039 "Dynamic Bending Light System Information : Dynamic Bending Light System Information Cksm";
CM_ SG_ 3221225472 LftRTrnLed038 "Dynamic Bending Light System Information : Dynamic Bending Light System Information Cksm";
CM_ SG_ 3221225472 LftRTrnLed037 "Dynamic Bending Light System Information : Dynamic Bending Light System Information Cksm";
CM_ SG_ 3221225472 LftRTrnLed036 "Dynamic Bending Light System Information : Dynamic Bending Light System Information Cksm";
CM_ SG_ 3221225472 LftRTrnLed035 "Dynamic Bending Light System Information : Dynamic Bending Light System Information Cksm";
CM_ SG_ 3221225472 LftRTrnLed034 "Dynamic Bending Light System Information : Dynamic Bending Light System Information Cksm";
CM_ SG_ 3221225472 LftRTrnLed033 "Dynamic Bending Light System Information : Dynamic Bending Light System Information Cksm";
CM_ SG_ 3221225472 RghtFTrnLed024 "Dynamic Bending Light System Information : Dynamic Bending Light System Information Cksm";
CM_ SG_ 3221225472 RghtFTrnLed023 "Dynamic Bending Light System Information : Dynamic Bending Light System Information Cksm";
CM_ SG_ 3221225472 RghtFTrnLed022 "Dynamic Bending Light System Information : Dynamic Bending Light System Information Cksm";
CM_ SG_ 3221225472 RghtFTrnLed021 "Dynamic Bending Light System Information : Dynamic Bending Light System Information Cksm";
CM_ SG_ 3221225472 RghtFTrnLed020 "Dynamic Bending Light System Information : Dynamic Bending Light System Information Cksm";
CM_ SG_ 3221225472 RghtFTrnLed019 "Dynamic Bending Light System Information : Dynamic Bending Light System Information Cksm";
CM_ SG_ 3221225472 RghtFTrnLed018 "Dynamic Bending Light System Information : Dynamic Bending Light System Information Cksm";
CM_ SG_ 3221225472 RghtFTrnLed017 "Dynamic Bending Light System Information : Dynamic Bending Light System Information Cksm";
CM_ SG_ 3221225472 LftFTrnLed024 "Dynamic Bending Light System Information : Dynamic Bending Light System Information Cksm";
CM_ SG_ 3221225472 LftFTrnLed023 "Dynamic Bending Light System Information : Dynamic Bending Light System Information Cksm";
CM_ SG_ 3221225472 LftFTrnLed022 "Dynamic Bending Light System Information : Dynamic Bending Light System Information Cksm";
CM_ SG_ 3221225472 LftFTrnLed021 "Dynamic Bending Light System Information : Dynamic Bending Light System Information Cksm";
CM_ SG_ 3221225472 LftFTrnLed020 "Dynamic Bending Light System Information : Dynamic Bending Light System Information Cksm";
CM_ SG_ 3221225472 LftFTrnLed019 "Dynamic Bending Light System Information : Dynamic Bending Light System Information Cksm";
CM_ SG_ 3221225472 LftFTrnLed018 "Dynamic Bending Light System Information : Dynamic Bending Light System Information Cksm";
CM_ SG_ 3221225472 LftFTrnLed017 "Dynamic Bending Light System Information : Dynamic Bending Light System Information Cksm";
CM_ SG_ 3221225472 RghtFCPlLed032 "Dynamic Bending Light System Information : Dynamic Bending Light System Information Cksm";
CM_ SG_ 3221225472 RghtFCPlLed031 "Dynamic Bending Light System Information : Dynamic Bending Light System Information Cksm";
CM_ SG_ 3221225472 RghtFCPlLed030 "Dynamic Bending Light System Information : Dynamic Bending Light System Information Cksm";
CM_ SG_ 3221225472 RghtFCPlLed029 "Dynamic Bending Light System Information : Dynamic Bending Light System Information Cksm";
CM_ SG_ 3221225472 RghtFCPlLed028 "Dynamic Bending Light System Information : Dynamic Bending Light System Information Cksm";
CM_ SG_ 3221225472 RghtFCPlLed027 "Dynamic Bending Light System Information : Dynamic Bending Light System Information Cksm";
CM_ SG_ 3221225472 RghtFCPlLed026 "Dynamic Bending Light System Information : Dynamic Bending Light System Information Cksm";
CM_ SG_ 3221225472 RghtFCPlLed025 "Dynamic Bending Light System Information : Dynamic Bending Light System Information Cksm";
CM_ SG_ 3221225472 RghtFCPlLed024 "Dynamic Bending Light System Information : Dynamic Bending Light System Information Cksm";
CM_ SG_ 3221225472 RghtFCPlLed023 "Dynamic Bending Light System Information : Dynamic Bending Light System Information Cksm";
CM_ SG_ 3221225472 RghtFCPlLed022 "Dynamic Bending Light System Information : Dynamic Bending Light System Information Cksm";
CM_ SG_ 3221225472 RghtFCPlLed021 "Dynamic Bending Light System Information : Dynamic Bending Light System Information Cksm";
CM_ SG_ 3221225472 RghtFCPlLed020 "Dynamic Bending Light System Information : Dynamic Bending Light System Information Cksm";
CM_ SG_ 3221225472 RghtFCPlLed019 "Dynamic Bending Light System Information : Dynamic Bending Light System Information Cksm";
CM_ SG_ 3221225472 RghtFCPlLed018 "Dynamic Bending Light System Information : Dynamic Bending Light System Information Cksm";
CM_ SG_ 3221225472 RghtFCPlLed017 "Dynamic Bending Light System Information : Dynamic Bending Light System Information Cksm";
CM_ SG_ 3221225472 RghtFCPlLed016 "Dynamic Bending Light System Information : Dynamic Bending Light System Information Cksm";
CM_ SG_ 3221225472 RghtFCPlLed015 "Dynamic Bending Light System Information : Dynamic Bending Light System Information Cksm";
CM_ SG_ 3221225472 RghtFCPlLed014 "Dynamic Bending Light System Information : Dynamic Bending Light System Information Cksm";
CM_ SG_ 3221225472 RghtFCPlLed013 "Dynamic Bending Light System Information : Dynamic Bending Light System Information Cksm";
CM_ SG_ 3221225472 RghtFCPlLed012 "Dynamic Bending Light System Information : Dynamic Bending Light System Information Cksm";
CM_ SG_ 3221225472 RghtFCPlLed011 "Dynamic Bending Light System Information : Dynamic Bending Light System Information Cksm";
CM_ SG_ 3221225472 RghtFCPlLed010 "Dynamic Bending Light System Information : Dynamic Bending Light System Information Cksm";
CM_ SG_ 3221225472 RghtFCPlLed009 "Dynamic Bending Light System Information : Dynamic Bending Light System Information Cksm";
CM_ SG_ 3221225472 LftFCPlLed032 "Dynamic Bending Light System Information : Dynamic Bending Light System Information Cksm";
CM_ SG_ 3221225472 LftFCPlLed031 "Dynamic Bending Light System Information : Dynamic Bending Light System Information Cksm";
CM_ SG_ 3221225472 LftFCPlLed030 "Dynamic Bending Light System Information : Dynamic Bending Light System Information Cksm";
CM_ SG_ 3221225472 LftFCPlLed029 "Dynamic Bending Light System Information : Dynamic Bending Light System Information Cksm";
CM_ SG_ 3221225472 LftFCPlLed028 "Dynamic Bending Light System Information : Dynamic Bending Light System Information Cksm";
CM_ SG_ 3221225472 LftFCPlLed027 "Dynamic Bending Light System Information : Dynamic Bending Light System Information Cksm";
CM_ SG_ 3221225472 LftFCPlLed026 "Dynamic Bending Light System Information : Dynamic Bending Light System Information Cksm";
CM_ SG_ 3221225472 LftFCPlLed025 "Dynamic Bending Light System Information : Dynamic Bending Light System Information Cksm";
CM_ SG_ 3221225472 LftHbLed024 "Dynamic Bending Light System Information : Dynamic Bending Light System Information Cksm";
CM_ SG_ 3221225472 LftHbLed023 "Dynamic Bending Light System Information : Dynamic Bending Light System Information Cksm";
CM_ SG_ 3221225472 LftHbLed022 "Dynamic Bending Light System Information : Dynamic Bending Light System Information Cksm";
CM_ SG_ 3221225472 LftHbLed021 "Dynamic Bending Light System Information : Dynamic Bending Light System Information Cksm";
CM_ SG_ 3221225472 LftHbLed020 "Dynamic Bending Light System Information : Dynamic Bending Light System Information Cksm";
CM_ SG_ 3221225472 LftHbLed019 "Dynamic Bending Light System Information : Dynamic Bending Light System Information Cksm";
CM_ SG_ 3221225472 LftHbLed018 "Dynamic Bending Light System Information : Dynamic Bending Light System Information Cksm";
CM_ SG_ 3221225472 LftHbLed017 "Dynamic Bending Light System Information : Dynamic Bending Light System Information Cksm";
CM_ SG_ 3221225472 RghtHbLed024 "Dynamic Bending Light System Information : Dynamic Bending Light System Information Cksm";
CM_ SG_ 3221225472 RghtHbLed023 "Dynamic Bending Light System Information : Dynamic Bending Light System Information Cksm";
CM_ SG_ 3221225472 RghtHbLed022 "Dynamic Bending Light System Information : Dynamic Bending Light System Information Cksm";
CM_ SG_ 3221225472 RghtHbLed021 "Dynamic Bending Light System Information : Dynamic Bending Light System Information Cksm";
CM_ SG_ 3221225472 RghtHbLed020 "Dynamic Bending Light System Information : Dynamic Bending Light System Information Cksm";
CM_ SG_ 3221225472 RghtHbLed019 "Dynamic Bending Light System Information : Dynamic Bending Light System Information Cksm";
CM_ SG_ 3221225472 RghtHbLed018 "Dynamic Bending Light System Information : Dynamic Bending Light System Information Cksm";
CM_ SG_ 3221225472 RghtHbLed017 "Dynamic Bending Light System Information : Dynamic Bending Light System Information Cksm";
CM_ SG_ 3221225472 LftFTrnLed016 "Dynamic Bending Light System Information : Dynamic Bending Light System Information Cksm";
CM_ SG_ 3221225472 LftFTrnLed015 "Dynamic Bending Light System Information : Dynamic Bending Light System Information Cksm";
CM_ SG_ 3221225472 LftFTrnLed014 "Dynamic Bending Light System Information : Dynamic Bending Light System Information Cksm";
CM_ SG_ 3221225472 LftFTrnLed013 "Dynamic Bending Light System Information : Dynamic Bending Light System Information Cksm";
CM_ SG_ 3221225472 LftFTrnLed012 "Dynamic Bending Light System Information : Dynamic Bending Light System Information Cksm";
CM_ SG_ 3221225472 LftFTrnLed011 "Dynamic Bending Light System Information : Dynamic Bending Light System Information Cksm";
CM_ SG_ 3221225472 LftFTrnLed010 "Dynamic Bending Light System Information : Dynamic Bending Light System Information Cksm";
CM_ SG_ 3221225472 LftFTrnLed009 "Dynamic Bending Light System Information : Dynamic Bending Light System Information Cksm";
CM_ SG_ 3221225472 RghtFTrnLed016 "Dynamic Bending Light System Information : Dynamic Bending Light System Information Cksm";
CM_ SG_ 3221225472 RghtFTrnLed015 "Dynamic Bending Light System Information : Dynamic Bending Light System Information Cksm";
CM_ SG_ 3221225472 RghtFTrnLed014 "Dynamic Bending Light System Information : Dynamic Bending Light System Information Cksm";
CM_ SG_ 3221225472 RghtFTrnLed013 "Dynamic Bending Light System Information : Dynamic Bending Light System Information Cksm";
CM_ SG_ 3221225472 RghtFTrnLed012 "Dynamic Bending Light System Information : Dynamic Bending Light System Information Cksm";
CM_ SG_ 3221225472 RghtFTrnLed011 "Dynamic Bending Light System Information : Dynamic Bending Light System Information Cksm";
CM_ SG_ 3221225472 RghtFTrnLed010 "Dynamic Bending Light System Information : Dynamic Bending Light System Information Cksm";
CM_ SG_ 3221225472 RghtFTrnLed009 "Dynamic Bending Light System Information : Dynamic Bending Light System Information Cksm";
CM_ SG_ 3221225472 LftFCPlLed008 "Dynamic Bending Light System Information : Dynamic Bending Light System Information Cksm";
CM_ SG_ 3221225472 LftFCPlLed007 "Dynamic Bending Light System Information : Dynamic Bending Light System Information Cksm";
CM_ SG_ 3221225472 LftFCPlLed006 "Dynamic Bending Light System Information : Dynamic Bending Light System Information Cksm";
CM_ SG_ 3221225472 LftFCPlLed005 "Dynamic Bending Light System Information : Dynamic Bending Light System Information Cksm";
CM_ SG_ 3221225472 LftFCPlLed004 "Dynamic Bending Light System Information : Dynamic Bending Light System Information Cksm";
CM_ SG_ 3221225472 LftFCPlLed003 "Dynamic Bending Light System Information : Dynamic Bending Light System Information Cksm";
CM_ SG_ 3221225472 LftFCPlLed002 "Dynamic Bending Light System Information : Dynamic Bending Light System Information Cksm";
CM_ SG_ 3221225472 LftFCPlLed001 "Dynamic Bending Light System Information : Dynamic Bending Light System Information Cksm";
CM_ SG_ 3221225472 LftFCPlLed016 "Dynamic Bending Light System Information : Dynamic Bending Light System Information Cksm";
CM_ SG_ 3221225472 LftFCPlLed015 "Dynamic Bending Light System Information : Dynamic Bending Light System Information Cksm";
CM_ SG_ 3221225472 LftFCPlLed014 "Dynamic Bending Light System Information : Dynamic Bending Light System Information Cksm";
CM_ SG_ 3221225472 LftFCPlLed013 "Dynamic Bending Light System Information : Dynamic Bending Light System Information Cksm";
CM_ SG_ 3221225472 LftFCPlLed012 "Dynamic Bending Light System Information : Dynamic Bending Light System Information Cksm";
CM_ SG_ 3221225472 LftFCPlLed011 "Dynamic Bending Light System Information : Dynamic Bending Light System Information Cksm";
CM_ SG_ 3221225472 LftFCPlLed010 "Dynamic Bending Light System Information : Dynamic Bending Light System Information Cksm";
CM_ SG_ 3221225472 LftFCPlLed009 "Dynamic Bending Light System Information : Dynamic Bending Light System Information Cksm";
CM_ SG_ 3221225472 RghtFTrnLed008 "Dynamic Bending Light System Information : Dynamic Bending Light System Information Cksm";
CM_ SG_ 3221225472 RghtFTrnLed007 "Dynamic Bending Light System Information : Dynamic Bending Light System Information Cksm";
CM_ SG_ 3221225472 RghtFTrnLed006 "Dynamic Bending Light System Information : Dynamic Bending Light System Information Cksm";
CM_ SG_ 3221225472 RghtFTrnLed005 "Dynamic Bending Light System Information : Dynamic Bending Light System Information Cksm";
CM_ SG_ 3221225472 RghtFTrnLed004 "Dynamic Bending Light System Information : Dynamic Bending Light System Information Cksm";
CM_ SG_ 3221225472 RghtFTrnLed003 "Dynamic Bending Light System Information : Dynamic Bending Light System Information Cksm";
CM_ SG_ 3221225472 RghtDrlLed056 "Dynamic Bending Light System Information : Dynamic Bending Light System Information Cksm";
CM_ SG_ 3221225472 RghtDrlLed055 "Dynamic Bending Light System Information : Dynamic Bending Light System Information Cksm";
CM_ SG_ 3221225472 RghtDrlLed054 "Dynamic Bending Light System Information : Dynamic Bending Light System Information Cksm";
CM_ SG_ 3221225472 RghtDrlLed053 "Dynamic Bending Light System Information : Dynamic Bending Light System Information Cksm";
CM_ SG_ 3221225472 RghtDrlLed052 "Dynamic Bending Light System Information : Dynamic Bending Light System Information Cksm";
CM_ SG_ 3221225472 RghtDrlLed051 "Dynamic Bending Light System Information : Dynamic Bending Light System Information Cksm";
CM_ SG_ 3221225472 RghtDhlSts "Left Headlamp Levelling Actual Position";
CM_ SG_ 3221225472 RghtDhlPosAct "Dynamic Bending Light System Information : Dynamic Bending Light System Information Cksm";
CM_ SG_ 3221225472 LampErr_FRLCMA "Dynamic Bending Light System Information : Dynamic Bending Light System Information Cksm";
CM_ SG_ 3221225472 LftDhlSts "Left Headlamp Levelling Actual Position";
CM_ SG_ 3221225472 LftDhlPosAct "Dynamic Bending Light System Information : Dynamic Bending Light System Information Cksm";
CM_ SG_ 3221225472 LampErr_FLLCMA "Dynamic Bending Light System Information : Dynamic Bending Light System Information Cksm";
CM_ SG_ 3221225472 SysSts_FLLCMA "Dynamic Bending Light System Information : Dynamic Bending Light System Information Cksm";
CM_ SG_ 3221225472 EngSt "Dynamic Bending Light System Information : Dynamic Bending Light System Information Cksm";
CM_ SG_ 3221225472 EngCrankSt "Dynamic Bending Light System Information : Dynamic Bending Light System Information Cksm";
CM_ SG_ 3221225472 KeySt "Dynamic Bending Light System Information : Dynamic Bending Light System Information Cksm";
CM_ SG_ 3221225472 LcuCmd_ShwCmd "Dynamic Bending Light System Information : Dynamic Bending Light System Information Cksm";
CM_ SG_ 3221225472 LcuCmd_LampCmd "Dynamic Bending Light System Information : Dynamic Bending Light System Information Cksm";
CM_ SG_ 490 LCU_ACU_Time_Year "Dynamic Bending Light System Information : Dynamic Bending Light System Information Cksm";
CM_ SG_ 490 LCU_ACU_Time_Sec "Dynamic Bending Light System Information : Dynamic Bending Light System Information Cksm";
CM_ SG_ 490 LCU_ACU_Time_Month "Dynamic Bending Light System Information : Dynamic Bending Light System Information Cksm";
CM_ SG_ 490 LCU_ACU_Time_Min "Dynamic Bending Light System Information : Dynamic Bending Light System Information Cksm";
CM_ SG_ 490 LCU_ACU_Time_Hour "Dynamic Bending Light System Information : Dynamic Bending Light System Information Cksm";
CM_ SG_ 490 LCU_ACU_Time_Day "Dynamic Bending Light System Information : Dynamic Bending Light System Information Cksm";
CM_ SG_ 776 LampErr_RRLCMB "Dynamic Bending Light System Information : Dynamic Bending Light System Information Cksm";
CM_ SG_ 774 LampErr_RRLCMA "Dynamic Bending Light System Information : Dynamic Bending Light System Information Cksm";
CM_ SG_ 775 LampErr_RLLCMB "Dynamic Bending Light System Information : Dynamic Bending Light System Information Cksm";
CM_ SG_ 773 LampErr_RLLCMA "Dynamic Bending Light System Information : Dynamic Bending Light System Information Cksm";
CM_ SG_ 772 LampErr_FRLCMB "Dynamic Bending Light System Information : Dynamic Bending Light System Information Cksm";
CM_ SG_ 770 LampErr_FLLCMB "Dynamic Bending Light System Information : Dynamic Bending Light System Information Cksm";
CM_ SG_ 769 FLLCMAErrSts "Dynamic Bending Light System Information : Dynamic Bending Light System Information Cksm";
CM_ SG_ 489 LCU_BCS_VehSpd "Dynamic Bending Light System Information : Dynamic Bending Light System Information Cksm";
CM_ SG_ 481 LftRPlLed008 "Dynamic Bending Light System Information : Dynamic Bending Light System Information Cksm";
CM_ SG_ 481 LftRPlLed007 "Dynamic Bending Light System Information : Dynamic Bending Light System Information Cksm";
CM_ SG_ 481 LftRPlLed006 "Dynamic Bending Light System Information : Dynamic Bending Light System Information Cksm";
CM_ SG_ 481 LftRPlLed005 "Dynamic Bending Light System Information : Dynamic Bending Light System Information Cksm";
CM_ SG_ 481 LftRPlLed004 "Dynamic Bending Light System Information : Dynamic Bending Light System Information Cksm";
CM_ SG_ 481 LftRPlLed003 "Dynamic Bending Light System Information : Dynamic Bending Light System Information Cksm";
CM_ SG_ 481 LftRPlLed002 "Dynamic Bending Light System Information : Dynamic Bending Light System Information Cksm";
CM_ SG_ 481 LftRPlLed001 "Dynamic Bending Light System Information : Dynamic Bending Light System Information Cksm";
CM_ SG_ 486 LftRPlLed016 "Dynamic Bending Light System Information : Dynamic Bending Light System Information Cksm";
CM_ SG_ 486 LftRPlLed015 "Dynamic Bending Light System Information : Dynamic Bending Light System Information Cksm";
CM_ SG_ 486 LftRPlLed014 "Dynamic Bending Light System Information : Dynamic Bending Light System Information Cksm";
CM_ SG_ 486 LftRPlLed013 "Dynamic Bending Light System Information : Dynamic Bending Light System Information Cksm";
CM_ SG_ 486 LftRPlLed012 "Dynamic Bending Light System Information : Dynamic Bending Light System Information Cksm";
CM_ SG_ 486 LftRPlLed011 "Dynamic Bending Light System Information : Dynamic Bending Light System Information Cksm";
CM_ SG_ 486 LftRPlLed010 "Dynamic Bending Light System Information : Dynamic Bending Light System Information Cksm";
CM_ SG_ 486 LftRPlLed009 "Dynamic Bending Light System Information : Dynamic Bending Light System Information Cksm";
CM_ SG_ 485 RghtRPlLed016 "Dynamic Bending Light System Information : Dynamic Bending Light System Information Cksm";
CM_ SG_ 485 RghtRPlLed015 "Dynamic Bending Light System Information : Dynamic Bending Light System Information Cksm";
CM_ SG_ 485 RghtRPlLed014 "Dynamic Bending Light System Information : Dynamic Bending Light System Information Cksm";
CM_ SG_ 485 RghtRPlLed013 "Dynamic Bending Light System Information : Dynamic Bending Light System Information Cksm";
CM_ SG_ 485 RghtRPlLed012 "Dynamic Bending Light System Information : Dynamic Bending Light System Information Cksm";
CM_ SG_ 485 RghtRPlLed011 "Dynamic Bending Light System Information : Dynamic Bending Light System Information Cksm";
CM_ SG_ 485 RghtRPlLed010 "Dynamic Bending Light System Information : Dynamic Bending Light System Information Cksm";
CM_ SG_ 485 RghtRPlLed009 "Dynamic Bending Light System Information : Dynamic Bending Light System Information Cksm";
CM_ SG_ 469 LftRCPlLed024 "Dynamic Bending Light System Information : Dynamic Bending Light System Information Cksm";
CM_ SG_ 469 LftRCPlLed023 "Dynamic Bending Light System Information : Dynamic Bending Light System Information Cksm";
CM_ SG_ 469 LftRCPlLed022 "Dynamic Bending Light System Information : Dynamic Bending Light System Information Cksm";
CM_ SG_ 469 LftRCPlLed021 "Dynamic Bending Light System Information : Dynamic Bending Light System Information Cksm";
CM_ SG_ 469 LftRCPlLed020 "Dynamic Bending Light System Information : Dynamic Bending Light System Information Cksm";
CM_ SG_ 469 LftRCPlLed019 "Dynamic Bending Light System Information : Dynamic Bending Light System Information Cksm";
CM_ SG_ 469 LftRCPlLed018 "Dynamic Bending Light System Information : Dynamic Bending Light System Information Cksm";
CM_ SG_ 469 LftRCPlLed017 "Dynamic Bending Light System Information : Dynamic Bending Light System Information Cksm";
CM_ SG_ 464 LftRCPlLed016 "Dynamic Bending Light System Information : Dynamic Bending Light System Information Cksm";
CM_ SG_ 464 LftRCPlLed015 "Dynamic Bending Light System Information : Dynamic Bending Light System Information Cksm";
CM_ SG_ 464 LftRCPlLed014 "Dynamic Bending Light System Information : Dynamic Bending Light System Information Cksm";
CM_ SG_ 464 LftRCPlLed013 "Dynamic Bending Light System Information : Dynamic Bending Light System Information Cksm";
CM_ SG_ 464 LftRCPlLed012 "Dynamic Bending Light System Information : Dynamic Bending Light System Information Cksm";
CM_ SG_ 464 LftRCPlLed011 "Dynamic Bending Light System Information : Dynamic Bending Light System Information Cksm";
CM_ SG_ 464 LftRCPlLed010 "Dynamic Bending Light System Information : Dynamic Bending Light System Information Cksm";
CM_ SG_ 464 LftRCPlLed009 "Dynamic Bending Light System Information : Dynamic Bending Light System Information Cksm";
CM_ SG_ 458 LftRCPlLed008 "Dynamic Bending Light System Information : Dynamic Bending Light System Information Cksm";
CM_ SG_ 458 LftRCPlLed007 "Dynamic Bending Light System Information : Dynamic Bending Light System Information Cksm";
CM_ SG_ 458 LftRCPlLed006 "Dynamic Bending Light System Information : Dynamic Bending Light System Information Cksm";
CM_ SG_ 458 LftRCPlLed005 "Dynamic Bending Light System Information : Dynamic Bending Light System Information Cksm";
CM_ SG_ 458 LftRCPlLed004 "Dynamic Bending Light System Information : Dynamic Bending Light System Information Cksm";
CM_ SG_ 458 LftRCPlLed003 "Dynamic Bending Light System Information : Dynamic Bending Light System Information Cksm";
CM_ SG_ 458 LftRCPlLed002 "Dynamic Bending Light System Information : Dynamic Bending Light System Information Cksm";
CM_ SG_ 458 LftRCPlLed001 "Dynamic Bending Light System Information : Dynamic Bending Light System Information Cksm";
CM_ SG_ 495 LftRPlLed032 "Dynamic Bending Light System Information : Dynamic Bending Light System Information Cksm";
CM_ SG_ 495 LftRPlLed031 "Dynamic Bending Light System Information : Dynamic Bending Light System Information Cksm";
CM_ SG_ 495 LftRPlLed030 "Dynamic Bending Light System Information : Dynamic Bending Light System Information Cksm";
CM_ SG_ 495 LftRPlLed029 "Dynamic Bending Light System Information : Dynamic Bending Light System Information Cksm";
CM_ SG_ 495 LftRPlLed028 "Dynamic Bending Light System Information : Dynamic Bending Light System Information Cksm";
CM_ SG_ 495 LftRPlLed027 "Dynamic Bending Light System Information : Dynamic Bending Light System Information Cksm";
CM_ SG_ 495 LftRPlLed026 "Dynamic Bending Light System Information : Dynamic Bending Light System Information Cksm";
CM_ SG_ 495 LftRPlLed025 "Dynamic Bending Light System Information : Dynamic Bending Light System Information Cksm";
CM_ SG_ 491 LftRPlLed024 "Dynamic Bending Light System Information : Dynamic Bending Light System Information Cksm";
CM_ SG_ 491 LftRPlLed023 "Dynamic Bending Light System Information : Dynamic Bending Light System Information Cksm";
CM_ SG_ 491 LftRPlLed022 "Dynamic Bending Light System Information : Dynamic Bending Light System Information Cksm";
CM_ SG_ 491 LftRPlLed021 "Dynamic Bending Light System Information : Dynamic Bending Light System Information Cksm";
CM_ SG_ 491 LftRPlLed020 "Dynamic Bending Light System Information : Dynamic Bending Light System Information Cksm";
CM_ SG_ 491 LftRPlLed019 "Dynamic Bending Light System Information : Dynamic Bending Light System Information Cksm";
CM_ SG_ 491 LftRPlLed018 "Dynamic Bending Light System Information : Dynamic Bending Light System Information Cksm";
CM_ SG_ 491 LftRPlLed017 "Dynamic Bending Light System Information : Dynamic Bending Light System Information Cksm";
CM_ SG_ 484 LftRCPlLed048 "Dynamic Bending Light System Information : Dynamic Bending Light System Information Cksm";
CM_ SG_ 484 LftRCPlLed047 "Dynamic Bending Light System Information : Dynamic Bending Light System Information Cksm";
CM_ SG_ 484 LftRCPlLed046 "Dynamic Bending Light System Information : Dynamic Bending Light System Information Cksm";
CM_ SG_ 484 LftRCPlLed045 "Dynamic Bending Light System Information : Dynamic Bending Light System Information Cksm";
CM_ SG_ 484 LftRCPlLed044 "Dynamic Bending Light System Information : Dynamic Bending Light System Information Cksm";
CM_ SG_ 484 LftRCPlLed043 "Dynamic Bending Light System Information : Dynamic Bending Light System Information Cksm";
CM_ SG_ 484 LftRCPlLed042 "Dynamic Bending Light System Information : Dynamic Bending Light System Information Cksm";
CM_ SG_ 484 LftRCPlLed041 "Dynamic Bending Light System Information : Dynamic Bending Light System Information Cksm";
CM_ SG_ 479 LftRCPlLed040 "Dynamic Bending Light System Information : Dynamic Bending Light System Information Cksm";
CM_ SG_ 479 LftRCPlLed039 "Dynamic Bending Light System Information : Dynamic Bending Light System Information Cksm";
CM_ SG_ 479 LftRCPlLed038 "Dynamic Bending Light System Information : Dynamic Bending Light System Information Cksm";
CM_ SG_ 479 LftRCPlLed037 "Dynamic Bending Light System Information : Dynamic Bending Light System Information Cksm";
CM_ SG_ 479 LftRCPlLed036 "Dynamic Bending Light System Information : Dynamic Bending Light System Information Cksm";
CM_ SG_ 479 LftRCPlLed035 "Dynamic Bending Light System Information : Dynamic Bending Light System Information Cksm";
CM_ SG_ 479 LftRCPlLed034 "Dynamic Bending Light System Information : Dynamic Bending Light System Information Cksm";
CM_ SG_ 479 LftRCPlLed033 "Dynamic Bending Light System Information : Dynamic Bending Light System Information Cksm";
CM_ SG_ 498 RghtRPlLed032 "Dynamic Bending Light System Information : Dynamic Bending Light System Information Cksm";
CM_ SG_ 498 RghtRPlLed031 "Dynamic Bending Light System Information : Dynamic Bending Light System Information Cksm";
CM_ SG_ 498 RghtRPlLed030 "Dynamic Bending Light System Information : Dynamic Bending Light System Information Cksm";
CM_ SG_ 498 RghtRPlLed029 "Dynamic Bending Light System Information : Dynamic Bending Light System Information Cksm";
CM_ SG_ 498 RghtRPlLed028 "Dynamic Bending Light System Information : Dynamic Bending Light System Information Cksm";
CM_ SG_ 498 RghtRPlLed027 "Dynamic Bending Light System Information : Dynamic Bending Light System Information Cksm";
CM_ SG_ 498 RghtRPlLed026 "Dynamic Bending Light System Information : Dynamic Bending Light System Information Cksm";
CM_ SG_ 498 RghtRPlLed025 "Dynamic Bending Light System Information : Dynamic Bending Light System Information Cksm";
CM_ SG_ 494 RghtRPlLed024 "Dynamic Bending Light System Information : Dynamic Bending Light System Information Cksm";
CM_ SG_ 494 RghtRPlLed023 "Dynamic Bending Light System Information : Dynamic Bending Light System Information Cksm";
CM_ SG_ 494 RghtRPlLed022 "Dynamic Bending Light System Information : Dynamic Bending Light System Information Cksm";
CM_ SG_ 494 RghtRPlLed021 "Dynamic Bending Light System Information : Dynamic Bending Light System Information Cksm";
CM_ SG_ 494 RghtRPlLed020 "Dynamic Bending Light System Information : Dynamic Bending Light System Information Cksm";
CM_ SG_ 494 RghtRPlLed019 "Dynamic Bending Light System Information : Dynamic Bending Light System Information Cksm";
CM_ SG_ 494 RghtRPlLed018 "Dynamic Bending Light System Information : Dynamic Bending Light System Information Cksm";
CM_ SG_ 494 RghtRPlLed017 "Dynamic Bending Light System Information : Dynamic Bending Light System Information Cksm";
CM_ SG_ 480 RghtRPlLed008 "Dynamic Bending Light System Information : Dynamic Bending Light System Information Cksm";
CM_ SG_ 480 RghtRPlLed007 "Dynamic Bending Light System Information : Dynamic Bending Light System Information Cksm";
CM_ SG_ 480 RghtRPlLed006 "Dynamic Bending Light System Information : Dynamic Bending Light System Information Cksm";
CM_ SG_ 480 RghtRPlLed005 "Dynamic Bending Light System Information : Dynamic Bending Light System Information Cksm";
CM_ SG_ 480 RghtRPlLed004 "Dynamic Bending Light System Information : Dynamic Bending Light System Information Cksm";
CM_ SG_ 480 RghtRPlLed003 "Dynamic Bending Light System Information : Dynamic Bending Light System Information Cksm";
CM_ SG_ 480 RghtRPlLed002 "Dynamic Bending Light System Information : Dynamic Bending Light System Information Cksm";
CM_ SG_ 480 RghtRPlLed001 "Dynamic Bending Light System Information : Dynamic Bending Light System Information Cksm";
CM_ SG_ 474 LftRCPlLed032 "Dynamic Bending Light System Information : Dynamic Bending Light System Information Cksm";
CM_ SG_ 474 LftRCPlLed031 "Dynamic Bending Light System Information : Dynamic Bending Light System Information Cksm";
CM_ SG_ 474 LftRCPlLed030 "Dynamic Bending Light System Information : Dynamic Bending Light System Information Cksm";
CM_ SG_ 474 LftRCPlLed029 "Dynamic Bending Light System Information : Dynamic Bending Light System Information Cksm";
CM_ SG_ 474 LftRCPlLed028 "Dynamic Bending Light System Information : Dynamic Bending Light System Information Cksm";
CM_ SG_ 474 LftRCPlLed027 "Dynamic Bending Light System Information : Dynamic Bending Light System Information Cksm";
CM_ SG_ 474 LftRCPlLed026 "Dynamic Bending Light System Information : Dynamic Bending Light System Information Cksm";
CM_ SG_ 474 LftRCPlLed025 "Dynamic Bending Light System Information : Dynamic Bending Light System Information Cksm";
CM_ SG_ 503 RghtDrlLed064 "Dynamic Bending Light System Information : Dynamic Bending Light System Information Cksm";
CM_ SG_ 503 RghtDrlLed063 "Dynamic Bending Light System Information : Dynamic Bending Light System Information Cksm";
CM_ SG_ 503 RghtDrlLed062 "Dynamic Bending Light System Information : Dynamic Bending Light System Information Cksm";
CM_ SG_ 503 RghtDrlLed061 "Dynamic Bending Light System Information : Dynamic Bending Light System Information Cksm";
CM_ SG_ 503 RghtDrlLed060 "Dynamic Bending Light System Information : Dynamic Bending Light System Information Cksm";
CM_ SG_ 503 RghtDrlLed059 "Dynamic Bending Light System Information : Dynamic Bending Light System Information Cksm";
CM_ SG_ 503 RghtDrlLed058 "Dynamic Bending Light System Information : Dynamic Bending Light System Information Cksm";
CM_ SG_ 503 LCU_RghtFrntDrlpl57Cmd "Dynamic Bending Light System Information : Dynamic Bending Light System Information Cksm";
CM_ SG_ 501 LCU_RghtFrntDrlpl50Cmd "Dynamic Bending Light System Information : Dynamic Bending Light System Information Cksm";
CM_ SG_ 501 LCU_RghtFrntDrlpl49Cmd "Dynamic Bending Light System Information : Dynamic Bending Light System Information Cksm";
CM_ SG_ 499 LCU_RghtFrntDrlpl48Cmd "Dynamic Bending Light System Information : Dynamic Bending Light System Information Cksm";
CM_ SG_ 499 LCU_RghtFrntDrlpl47Cmd "Dynamic Bending Light System Information : Dynamic Bending Light System Information Cksm";
CM_ SG_ 499 LCU_RghtFrntDrlpl46Cmd "Dynamic Bending Light System Information : Dynamic Bending Light System Information Cksm";
CM_ SG_ 499 LCU_RghtFrntDrlpl45Cmd "Dynamic Bending Light System Information : Dynamic Bending Light System Information Cksm";
CM_ SG_ 499 LCU_RghtFrntDrlpl44Cmd "Dynamic Bending Light System Information : Dynamic Bending Light System Information Cksm";
CM_ SG_ 499 LCU_RghtFrntDrlpl43Cmd "Dynamic Bending Light System Information : Dynamic Bending Light System Information Cksm";
CM_ SG_ 499 LCU_RghtFrntDrlpl42Cmd "Dynamic Bending Light System Information : Dynamic Bending Light System Information Cksm";
CM_ SG_ 499 LCU_RghtFrntDrlpl41Cmd "Dynamic Bending Light System Information : Dynamic Bending Light System Information Cksm";
CM_ SG_ 496 LCU_RghtFrntDrlpl40Cmd "Dynamic Bending Light System Information : Dynamic Bending Light System Information Cksm";
CM_ SG_ 496 LCU_RghtFrntDrlpl39Cmd "Dynamic Bending Light System Information : Dynamic Bending Light System Information Cksm";
CM_ SG_ 496 LCU_RghtFrntDrlpl38Cmd "Dynamic Bending Light System Information : Dynamic Bending Light System Information Cksm";
CM_ SG_ 496 LCU_RghtFrntDrlpl37Cmd "Dynamic Bending Light System Information : Dynamic Bending Light System Information Cksm";
CM_ SG_ 496 LCU_RghtFrntDrlpl36Cmd "Dynamic Bending Light System Information : Dynamic Bending Light System Information Cksm";
CM_ SG_ 496 LCU_RghtFrntDrlpl35Cmd "Dynamic Bending Light System Information : Dynamic Bending Light System Information Cksm";
CM_ SG_ 496 LCU_RghtFrntDrlpl34Cmd "Dynamic Bending Light System Information : Dynamic Bending Light System Information Cksm";
CM_ SG_ 496 LCU_RghtFrntDrlpl33Cmd "Dynamic Bending Light System Information : Dynamic Bending Light System Information Cksm";
CM_ SG_ 504 LftDrlLed064 "Dynamic Bending Light System Information : Dynamic Bending Light System Information Cksm";
CM_ SG_ 504 LftDrlLed063 "Dynamic Bending Light System Information : Dynamic Bending Light System Information Cksm";
CM_ SG_ 504 LftDrlLed062 "Dynamic Bending Light System Information : Dynamic Bending Light System Information Cksm";
CM_ SG_ 504 LftDrlLed061 "Dynamic Bending Light System Information : Dynamic Bending Light System Information Cksm";
CM_ SG_ 504 LftDrlLed060 "Dynamic Bending Light System Information : Dynamic Bending Light System Information Cksm";
CM_ SG_ 504 LftDrlLed059 "Dynamic Bending Light System Information : Dynamic Bending Light System Information Cksm";
CM_ SG_ 504 LftDrlLed058 "Dynamic Bending Light System Information : Dynamic Bending Light System Information Cksm";
CM_ SG_ 504 LCU_LftFrntDrlPl57Cmd "Dynamic Bending Light System Information : Dynamic Bending Light System Information Cksm";
CM_ SG_ 502 LCU_LftFrntDrlPl56Cmd "Dynamic Bending Light System Information : Dynamic Bending Light System Information Cksm";
CM_ SG_ 502 LCU_LftFrntDrlPl55Cmd "Dynamic Bending Light System Information : Dynamic Bending Light System Information Cksm";
CM_ SG_ 502 LCU_LftFrntDrlPl54Cmd "Dynamic Bending Light System Information : Dynamic Bending Light System Information Cksm";
CM_ SG_ 502 LCU_LftFrntDrlPl53Cmd "Dynamic Bending Light System Information : Dynamic Bending Light System Information Cksm";
CM_ SG_ 502 LCU_LftFrntDrlPl52Cmd "Dynamic Bending Light System Information : Dynamic Bending Light System Information Cksm";
CM_ SG_ 502 LCU_LftFrntDrlPl51Cmd "Dynamic Bending Light System Information : Dynamic Bending Light System Information Cksm";
CM_ SG_ 502 LCU_LftFrntDrlPl50Cmd "Dynamic Bending Light System Information : Dynamic Bending Light System Information Cksm";
CM_ SG_ 502 LCU_LftFrntDrlPl49Cmd "Dynamic Bending Light System Information : Dynamic Bending Light System Information Cksm";
CM_ SG_ 500 LCU_LftFrntDrlPl48Cmd "Dynamic Bending Light System Information : Dynamic Bending Light System Information Cksm";
CM_ SG_ 500 LCU_LftFrntDrlPl47Cmd "Dynamic Bending Light System Information : Dynamic Bending Light System Information Cksm";
CM_ SG_ 500 LCU_LftFrntDrlPl46Cmd "Dynamic Bending Light System Information : Dynamic Bending Light System Information Cksm";
CM_ SG_ 500 LCU_LftFrntDrlPl45Cmd "Dynamic Bending Light System Information : Dynamic Bending Light System Information Cksm";
CM_ SG_ 500 LCU_LftFrntDrlPl44Cmd "Dynamic Bending Light System Information : Dynamic Bending Light System Information Cksm";
CM_ SG_ 500 LCU_LftFrntDrlPl43Cmd "Dynamic Bending Light System Information : Dynamic Bending Light System Information Cksm";
CM_ SG_ 500 LCU_LftFrntDrlPl42Cmd "Dynamic Bending Light System Information : Dynamic Bending Light System Information Cksm";
CM_ SG_ 500 LCU_LftFrntDrlPl41Cmd "Dynamic Bending Light System Information : Dynamic Bending Light System Information Cksm";
CM_ SG_ 497 LCU_LftFrntDrlPl40Cmd "Dynamic Bending Light System Information : Dynamic Bending Light System Information Cksm";
CM_ SG_ 497 LCU_LftFrntDrlPl39Cmd "Dynamic Bending Light System Information : Dynamic Bending Light System Information Cksm";
CM_ SG_ 497 LCU_LftFrntDrlPl38Cmd "Dynamic Bending Light System Information : Dynamic Bending Light System Information Cksm";
CM_ SG_ 497 LCU_LftFrntDrlPl37Cmd "Dynamic Bending Light System Information : Dynamic Bending Light System Information Cksm";
CM_ SG_ 497 LCU_LftFrntDrlPl36Cmd "Dynamic Bending Light System Information : Dynamic Bending Light System Information Cksm";
CM_ SG_ 497 LCU_LftFrntDrlPl35Cmd "Dynamic Bending Light System Information : Dynamic Bending Light System Information Cksm";
CM_ SG_ 497 LCU_LftFrntDrlPl34Cmd "Dynamic Bending Light System Information : Dynamic Bending Light System Information Cksm";
CM_ SG_ 497 LCU_LftFrntDrlPl33Cmd "Dynamic Bending Light System Information : Dynamic Bending Light System Information Cksm";
CM_ SG_ 475 RghtRTrnLed032 "Dynamic Bending Light System Information : Dynamic Bending Light System Information Cksm";
CM_ SG_ 475 RghtRTrnLed031 "Dynamic Bending Light System Information : Dynamic Bending Light System Information Cksm";
CM_ SG_ 475 RghtRTrnLed030 "Dynamic Bending Light System Information : Dynamic Bending Light System Information Cksm";
CM_ SG_ 475 RghtRTrnLed029 "Dynamic Bending Light System Information : Dynamic Bending Light System Information Cksm";
CM_ SG_ 475 RghtRTrnLed028 "Dynamic Bending Light System Information : Dynamic Bending Light System Information Cksm";
CM_ SG_ 475 RghtRTrnLed027 "Dynamic Bending Light System Information : Dynamic Bending Light System Information Cksm";
CM_ SG_ 475 RghtRTrnLed026 "Dynamic Bending Light System Information : Dynamic Bending Light System Information Cksm";
CM_ SG_ 475 RghtRTrnLed025 "Dynamic Bending Light System Information : Dynamic Bending Light System Information Cksm";
CM_ SG_ 470 RghtRTrnLed024 "Dynamic Bending Light System Information : Dynamic Bending Light System Information Cksm";
CM_ SG_ 470 RghtRTrnLed023 "Dynamic Bending Light System Information : Dynamic Bending Light System Information Cksm";
CM_ SG_ 470 RghtRTrnLed022 "Dynamic Bending Light System Information : Dynamic Bending Light System Information Cksm";
CM_ SG_ 470 RghtRTrnLed021 "Dynamic Bending Light System Information : Dynamic Bending Light System Information Cksm";
CM_ SG_ 470 RghtRTrnLed020 "Dynamic Bending Light System Information : Dynamic Bending Light System Information Cksm";
CM_ SG_ 470 RghtRTrnLed019 "Dynamic Bending Light System Information : Dynamic Bending Light System Information Cksm";
CM_ SG_ 470 RghtRTrnLed018 "Dynamic Bending Light System Information : Dynamic Bending Light System Information Cksm";
CM_ SG_ 470 RghtRTrnLed017 "Dynamic Bending Light System Information : Dynamic Bending Light System Information Cksm";
CM_ SG_ 465 RghtRTrnLed016 "Dynamic Bending Light System Information : Dynamic Bending Light System Information Cksm";
CM_ SG_ 465 RghtRTrnLed015 "Dynamic Bending Light System Information : Dynamic Bending Light System Information Cksm";
CM_ SG_ 465 RghtRTrnLed014 "Dynamic Bending Light System Information : Dynamic Bending Light System Information Cksm";
CM_ SG_ 465 RghtRTrnLed013 "Dynamic Bending Light System Information : Dynamic Bending Light System Information Cksm";
CM_ SG_ 465 RghtRTrnLed012 "Dynamic Bending Light System Information : Dynamic Bending Light System Information Cksm";
CM_ SG_ 465 RghtRTrnLed011 "Dynamic Bending Light System Information : Dynamic Bending Light System Information Cksm";
CM_ SG_ 465 RghtRTrnLed010 "Dynamic Bending Light System Information : Dynamic Bending Light System Information Cksm";
CM_ SG_ 465 RghtRTrnLed009 "Dynamic Bending Light System Information : Dynamic Bending Light System Information Cksm";
CM_ SG_ 476 LftRTrnLed032 "Dynamic Bending Light System Information : Dynamic Bending Light System Information Cksm";
CM_ SG_ 476 LftRTrnLed031 "Dynamic Bending Light System Information : Dynamic Bending Light System Information Cksm";
CM_ SG_ 476 LftRTrnLed030 "Dynamic Bending Light System Information : Dynamic Bending Light System Information Cksm";
CM_ SG_ 476 LftRTrnLed029 "Dynamic Bending Light System Information : Dynamic Bending Light System Information Cksm";
CM_ SG_ 476 LftRTrnLed028 "Dynamic Bending Light System Information : Dynamic Bending Light System Information Cksm";
CM_ SG_ 476 LftRTrnLed027 "Dynamic Bending Light System Information : Dynamic Bending Light System Information Cksm";
CM_ SG_ 476 LftRTrnLed026 "Dynamic Bending Light System Information : Dynamic Bending Light System Information Cksm";
CM_ SG_ 476 LftRTrnLed025 "Dynamic Bending Light System Information : Dynamic Bending Light System Information Cksm";
CM_ SG_ 471 LftRTrnLed024 "Dynamic Bending Light System Information : Dynamic Bending Light System Information Cksm";
CM_ SG_ 471 LftRTrnLed023 "Dynamic Bending Light System Information : Dynamic Bending Light System Information Cksm";
CM_ SG_ 471 LftRTrnLed022 "Dynamic Bending Light System Information : Dynamic Bending Light System Information Cksm";
CM_ SG_ 471 LftRTrnLed021 "Dynamic Bending Light System Information : Dynamic Bending Light System Information Cksm";
CM_ SG_ 471 LftRTrnLed020 "Dynamic Bending Light System Information : Dynamic Bending Light System Information Cksm";
CM_ SG_ 471 LftRTrnLed019 "Dynamic Bending Light System Information : Dynamic Bending Light System Information Cksm";
CM_ SG_ 471 LftRTrnLed018 "Dynamic Bending Light System Information : Dynamic Bending Light System Information Cksm";
CM_ SG_ 471 LftRTrnLed017 "Dynamic Bending Light System Information : Dynamic Bending Light System Information Cksm";
CM_ SG_ 466 LftRTrnLed016 "Dynamic Bending Light System Information : Dynamic Bending Light System Information Cksm";
CM_ SG_ 466 LftRTrnLed015 "Dynamic Bending Light System Information : Dynamic Bending Light System Information Cksm";
CM_ SG_ 466 LftRTrnLed014 "Dynamic Bending Light System Information : Dynamic Bending Light System Information Cksm";
CM_ SG_ 466 LftRTrnLed013 "Dynamic Bending Light System Information : Dynamic Bending Light System Information Cksm";
CM_ SG_ 466 LftRTrnLed012 "Dynamic Bending Light System Information : Dynamic Bending Light System Information Cksm";
CM_ SG_ 466 LftRTrnLed011 "Dynamic Bending Light System Information : Dynamic Bending Light System Information Cksm";
CM_ SG_ 466 LftRTrnLed010 "Dynamic Bending Light System Information : Dynamic Bending Light System Information Cksm";
CM_ SG_ 466 LftRTrnLed009 "Dynamic Bending Light System Information : Dynamic Bending Light System Information Cksm";
CM_ SG_ 2161836032 ExtData "Dynamic Bending Light System Information : Dynamic Bending Light System Information Cksm";
CM_ SG_ 457 LCU_LftLb08Cmd "Dynamic Bending Light System Information : Dynamic Bending Light System Information Cksm";
CM_ SG_ 457 LCU_LftLb07Cmd "Dynamic Bending Light System Information : Dynamic Bending Light System Information Cksm";
CM_ SG_ 457 LCU_LftLb06Cmd "Dynamic Bending Light System Information : Dynamic Bending Light System Information Cksm";
CM_ SG_ 457 LCU_LftLb05Cmd "Dynamic Bending Light System Information : Dynamic Bending Light System Information Cksm";
CM_ SG_ 457 LCU_LftLb04Cmd "Dynamic Bending Light System Information : Dynamic Bending Light System Information Cksm";
CM_ SG_ 457 LCU_LftLb03Cmd "Dynamic Bending Light System Information : Dynamic Bending Light System Information Cksm";
CM_ SG_ 457 LCU_LftLb02Cmd "Dynamic Bending Light System Information : Dynamic Bending Light System Information Cksm";
CM_ SG_ 457 LCU_LftLb01Cmd "Dynamic Bending Light System Information : Dynamic Bending Light System Information Cksm";
CM_ SG_ 456 LCU_RghtLb08Cmd "Dynamic Bending Light System Information : Dynamic Bending Light System Information Cksm";
CM_ SG_ 456 LCU_RghtLb07Cmd "Dynamic Bending Light System Information : Dynamic Bending Light System Information Cksm";
CM_ SG_ 456 LCU_RghtLb06Cmd "Dynamic Bending Light System Information : Dynamic Bending Light System Information Cksm";
CM_ SG_ 456 LCU_RghtLb05Cmd "Dynamic Bending Light System Information : Dynamic Bending Light System Information Cksm";
CM_ SG_ 456 LCU_RghtLb04Cmd "Dynamic Bending Light System Information : Dynamic Bending Light System Information Cksm";
CM_ SG_ 456 LCU_RghtLb03Cmd "Dynamic Bending Light System Information : Dynamic Bending Light System Information Cksm";
CM_ SG_ 456 LCU_RghtLb02Cmd "Dynamic Bending Light System Information : Dynamic Bending Light System Information Cksm";
CM_ SG_ 456 LCU_RghtLb01Cmd "Dynamic Bending Light System Information : Dynamic Bending Light System Information Cksm";
CM_ SG_ 463 LCU_LftHb08Cmd "Dynamic Bending Light System Information : Dynamic Bending Light System Information Cksm";
CM_ SG_ 463 LCU_LftHb07Cmd "Dynamic Bending Light System Information : Dynamic Bending Light System Information Cksm";
CM_ SG_ 463 LCU_LftHb06Cmd "Dynamic Bending Light System Information : Dynamic Bending Light System Information Cksm";
CM_ SG_ 463 LCU_LftHb05Cmd "Dynamic Bending Light System Information : Dynamic Bending Light System Information Cksm";
CM_ SG_ 463 LCU_LftHb04Cmd "Dynamic Bending Light System Information : Dynamic Bending Light System Information Cksm";
CM_ SG_ 463 LCU_LftHb03Cmd "Dynamic Bending Light System Information : Dynamic Bending Light System Information Cksm";
CM_ SG_ 463 LCU_LftHb02Cmd "Dynamic Bending Light System Information : Dynamic Bending Light System Information CksmDynamic Bending Light System Information : Dynamic Bending Light System Information Cksm";
CM_ SG_ 468 LCU_LftHb16Cmd "Dynamic Bending Light System Information : Dynamic Bending Light System Information CksmDynamic Bending Light System Information : Dynamic Bending Light System Information Cksm";
CM_ SG_ 468 LCU_LftHb14Cmd "Dynamic Bending Light System Information : Dynamic Bending Light System Information Cksm";
CM_ SG_ 468 LCU_LftHb13Cmd "Dynamic Bending Light System Information : Dynamic Bending Light System Information Cksm";
CM_ SG_ 468 LCU_LftHb12Cmd "Dynamic Bending Light System Information : Dynamic Bending Light System Information Cksm";
CM_ SG_ 468 LCU_LftHb11Cmd "Dynamic Bending Light System Information : Dynamic Bending Light System Information Cksm";
CM_ SG_ 468 LCU_LftHb10Cmd "Dynamic Bending Light System Information : Dynamic Bending Light System Information Cksm";
CM_ SG_ 468 LCU_LftHb09Cmd "Dynamic Bending Light System Information : Dynamic Bending Light System Information Cksm";
CM_ SG_ 462 LCU_RghtHb08Cmd "Dynamic Bending Light System Information : Dynamic Bending Light System Information Cksm";
CM_ SG_ 462 LCU_RghtHb07Cmd "Dynamic Bending Light System Information : Dynamic Bending Light System Information Cksm";
CM_ SG_ 462 LCU_RghtHb06Cmd "Dynamic Bending Light System Information : Dynamic Bending Light System Information Cksm";
CM_ SG_ 462 LCU_RghtHb05Cmd "Dynamic Bending Light System Information : Dynamic Bending Light System Information Cksm";
CM_ SG_ 462 LCU_RghtHb04Cmd "Dynamic Bending Light System Information : Dynamic Bending Light System Information Cksm";
CM_ SG_ 462 LCU_RghtHb03Cmd "Dynamic Bending Light System Information : Dynamic Bending Light System Information Cksm";
CM_ SG_ 462 LCU_RghtHb02Cmd "Dynamic Bending Light System Information : Dynamic Bending Light System Information Cksm";
CM_ SG_ 462 LCU_RghtHb01Cmd "Dynamic Bending Light System Information : Dynamic Bending Light System Information Cksm";
CM_ SG_ 467 LCU_RghtHb16Cmd "Dynamic Bending Light System Information : Dynamic Bending Light System Information Cksm";
CM_ SG_ 467 LCU_RghtHb15Cmd "Dynamic Bending Light System Information : Dynamic Bending Light System Information Cksm";
CM_ SG_ 467 LCU_RghtHb14Cmd "Dynamic Bending Light System Information : Dynamic Bending Light System Information Cksm";
CM_ SG_ 467 LCU_RghtHb13Cmd "Dynamic Bending Light System Information : Dynamic Bending Light System Information Cksm";
CM_ SG_ 467 LCU_RghtHb12Cmd "Dynamic Bending Light System Information : Dynamic Bending Light System Information Cksm";
CM_ SG_ 467 LCU_RghtHb11Cmd "Dynamic Bending Light System Information : Dynamic Bending Light System Information Cksm";
CM_ SG_ 467 LCU_RghtHb10Cmd "Dynamic Bending Light System Information : Dynamic Bending Light System Information Cksm";
CM_ SG_ 467 LCU_RghtHb09Cmd "Dynamic Bending Light System Information : Dynamic Bending Light System Information Cksm";
CM_ SG_ 473 LCU_LftFrntTL01Cmd "Dynamic Bending Light System Information : Dynamic Bending Light System Information Cksm";
CM_ SG_ 473 LftFTrnLed008 "Dynamic Bending Light System Information : Dynamic Bending Light System Information Cksm";
CM_ SG_ 473 LftFTrnLed007 "Dynamic Bending Light System Information : Dynamic Bending Light System Information Cksm";
CM_ SG_ 473 LftFTrnLed006 "Dynamic Bending Light System Information : Dynamic Bending Light System Information Cksm";
CM_ SG_ 473 LftFTrnLed005 "Dynamic Bending Light System Information : Dynamic Bending Light System Information Cksm";
CM_ SG_ 473 LftFTrnLed004 "Dynamic Bending Light System Information : Dynamic Bending Light System Information Cksm";
CM_ SG_ 473 LftFTrnLed003 "Dynamic Bending Light System Information : Dynamic Bending Light System Information Cksm";
CM_ SG_ 473 LCU_LftFrntTL02Cmd "Dynamic Bending Light System Information : Dynamic Bending Light System Information Cksm";
CM_ SG_ 472 LCU_RghtFrntTL02Cmd "Dynamic Bending Light System Information : Dynamic Bending Light System Information Cksm";
CM_ SG_ 472 LCU_RghtFrntTL01Cmd "Dynamic Bending Light System Information : Dynamic Bending Light System Information Cksm";
CM_ SG_ 461 LftRTrnLed008 "Dynamic Bending Light System Information : Dynamic Bending Light System Information Cksm";
CM_ SG_ 461 LftRTrnLed007 "Dynamic Bending Light System Information : Dynamic Bending Light System Information Cksm";
CM_ SG_ 461 LftRTrnLed006 "Dynamic Bending Light System Information : Dynamic Bending Light System Information Cksm";
CM_ SG_ 461 LftRTrnLed005 "Dynamic Bending Light System Information : Dynamic Bending Light System Information Cksm";
CM_ SG_ 461 LftRTrnLed004 "Dynamic Bending Light System Information : Dynamic Bending Light System Information Cksm";
CM_ SG_ 461 LftRTrnLed003 "Dynamic Bending Light System Information : Dynamic Bending Light System Information Cksm";
CM_ SG_ 461 LftRTrnLed002 "Dynamic Bending Light System Information : Dynamic Bending Light System Information Cksm";
CM_ SG_ 461 LftRTrnLed001 "Dynamic Bending Light System Information : Dynamic Bending Light System Information Cksm";
CM_ SG_ 459 RghtRTrnLed008 "Dynamic Bending Light System Information : Dynamic Bending Light System Information Cksm";
CM_ SG_ 459 RghtRTrnLed007 "Dynamic Bending Light System Information : Dynamic Bending Light System Information Cksm";
CM_ SG_ 459 RghtRTrnLed006 "Dynamic Bending Light System Information : Dynamic Bending Light System Information Cksm";
CM_ SG_ 459 RghtRTrnLed005 "Dynamic Bending Light System Information : Dynamic Bending Light System Information Cksm";
CM_ SG_ 459 RghtRTrnLed004 "Dynamic Bending Light System Information : Dynamic Bending Light System Information Cksm";
CM_ SG_ 459 RghtRTrnLed003 "Dynamic Bending Light System Information : Dynamic Bending Light System Information Cksm";
CM_ SG_ 459 RghtRTrnLed002 "Dynamic Bending Light System Information : Dynamic Bending Light System Information Cksm";
CM_ SG_ 459 RghtRTrnLed001 "Dynamic Bending Light System Information : Dynamic Bending Light System Information Cksm";
CM_ SG_ 478 LCU_LftFrntDrlPl08Cmd "Dynamic Bending Light System Information : Dynamic Bending Light System Information Cksm";
CM_ SG_ 478 LCU_LftFrntDrlPl07Cmd "Dynamic Bending Light System Information : Dynamic Bending Light System Information Cksm";
CM_ SG_ 478 LCU_LftFrntDrlPl06Cmd "Dynamic Bending Light System Information : Dynamic Bending Light System Information Cksm";
CM_ SG_ 478 LCU_LftFrntDrlPl05Cmd "Dynamic Bending Light System Information : Dynamic Bending Light System Information Cksm";
CM_ SG_ 478 LCU_LftFrntDrlPl04Cmd "Dynamic Bending Light System Information : Dynamic Bending Light System Information Cksm";
CM_ SG_ 478 LCU_LftFrntDrlPl03Cmd "Dynamic Bending Light System Information : Dynamic Bending Light System Information Cksm";
CM_ SG_ 478 LCU_LftFrntDrlPl02Cmd "Dynamic Bending Light System Information : Dynamic Bending Light System Information Cksm";
CM_ SG_ 478 LCU_LftFrntDrlPl01Cmd "Dynamic Bending Light System Information : Dynamic Bending Light System Information Cksm";
CM_ SG_ 483 LCU_LftFrntDrlPl16Cmd "Dynamic Bending Light System Information : Dynamic Bending Light System Information Cksm";
CM_ SG_ 483 LCU_LftFrntDrlPl15Cmd "Dynamic Bending Light System Information : Dynamic Bending Light System Information Cksm";
CM_ SG_ 483 LCU_LftFrntDrlPl14Cmd "Dynamic Bending Light System Information : Dynamic Bending Light System Information Cksm";
CM_ SG_ 483 LCU_LftFrntDrlPl13Cmd "Dynamic Bending Light System Information : Dynamic Bending Light System Information Cksm";
CM_ SG_ 483 LCU_LftFrntDrlPl12Cmd "Dynamic Bending Light System Information : Dynamic Bending Light System Information Cksm";
CM_ SG_ 483 LCU_LftFrntDrlPl11Cmd "Dynamic Bending Light System Information : Dynamic Bending Light System Information Cksm";
CM_ SG_ 483 LCU_LftFrntDrlPl10Cmd "Dynamic Bending Light System Information : Dynamic Bending Light System Information Cksm";
CM_ SG_ 483 LCU_LftFrntDrlPl09Cmd "Dynamic Bending Light System Information : Dynamic Bending Light System Information Cksm";
CM_ SG_ 488 LCU_LftFrntDrlPl24Cmd "Dynamic Bending Light System Information : Dynamic Bending Light System Information Cksm";
CM_ SG_ 488 LCU_LftFrntDrlPl23Cmd "Dynamic Bending Light System Information : Dynamic Bending Light System Information Cksm";
CM_ SG_ 488 LCU_LftFrntDrlPl22Cmd "Dynamic Bending Light System Information : Dynamic Bending Light System Information Cksm";
CM_ SG_ 488 LCU_LftFrntDrlPl21Cmd "Dynamic Bending Light System Information : Dynamic Bending Light System Information Cksm";
CM_ SG_ 488 LCU_LftFrntDrlPl20Cmd "Dynamic Bending Light System Information : Dynamic Bending Light System Information Cksm";
CM_ SG_ 488 LCU_LftFrntDrlPl19Cmd "Dynamic Bending Light System Information : Dynamic Bending Light System Information Cksm";
CM_ SG_ 488 LCU_LftFrntDrlPl18Cmd "Dynamic Bending Light System Information : Dynamic Bending Light System Information Cksm";
CM_ SG_ 488 LCU_LftFrntDrlPl17Cmd "Dynamic Bending Light System Information : Dynamic Bending Light System Information Cksm";
CM_ SG_ 493 LCU_LftFrntDrlPl32Cmd "Dynamic Bending Light System Information : Dynamic Bending Light System Information Cksm";
CM_ SG_ 493 LCU_LftFrntDrlPl31Cmd "Dynamic Bending Light System Information : Dynamic Bending Light System Information Cksm";
CM_ SG_ 493 LCU_LftFrntDrlPl30Cmd "Dynamic Bending Light System Information : Dynamic Bending Light System Information Cksm";
CM_ SG_ 493 LCU_LftFrntDrlPl29Cmd "Dynamic Bending Light System Information : Dynamic Bending Light System Information Cksm";
CM_ SG_ 493 LCU_LftFrntDrlPl28Cmd "Dynamic Bending Light System Information : Dynamic Bending Light System Information Cksm";
CM_ SG_ 493 LCU_LftFrntDrlPl27Cmd "Dynamic Bending Light System Information : Dynamic Bending Light System Information Cksm";
CM_ SG_ 493 LCU_LftFrntDrlPl26Cmd "Dynamic Bending Light System Information : Dynamic Bending Light System Information Cksm";
CM_ SG_ 493 LCU_LftFrntDrlPl25Cmd "Dynamic Bending Light System Information : Dynamic Bending Light System Information Cksm";
CM_ SG_ 477 LCU_RghtFrntDrlpl08Cmd "Dynamic Bending Light System Information : Dynamic Bending Light System Information Cksm";
CM_ SG_ 477 LCU_RghtFrntDrlpl07Cmd "Dynamic Bending Light System Information : Dynamic Bending Light System Information Cksm";
CM_ SG_ 477 LCU_RghtFrntDrlpl06Cmd "Dynamic Bending Light System Information : Dynamic Bending Light System Information Cksm";
CM_ SG_ 477 LCU_RghtFrntDrlpl05Cmd "Dynamic Bending Light System Information : Dynamic Bending Light System Information Cksm";
CM_ SG_ 477 LCU_RghtFrntDrlpl04Cmd "Dynamic Bending Light System Information : Dynamic Bending Light System Information Cksm";
CM_ SG_ 477 LCU_RghtFrntDrlpl03Cmd "Dynamic Bending Light System Information : Dynamic Bending Light System Information Cksm";
CM_ SG_ 477 LCU_RghtFrntDrlpl02Cmd "Dynamic Bending Light System Information : Dynamic Bending Light System Information Cksm";
CM_ SG_ 477 LCU_RghtFrntDrlpl01Cmd "Dynamic Bending Light System Information : Dynamic Bending Light System Information Cksm";
CM_ SG_ 482 LCU_RghtFrntDrlpl16Cmd "Dynamic Bending Light System Information : Dynamic Bending Light System Information Cksm";
CM_ SG_ 482 LCU_RghtFrntDrlpl15Cmd "Dynamic Bending Light System Information : Dynamic Bending Light System Information Cksm";
CM_ SG_ 482 LCU_RghtFrntDrlpl14Cmd "Dynamic Bending Light System Information : Dynamic Bending Light System Information Cksm";
CM_ SG_ 482 LCU_RghtFrntDrlpl13Cmd "Dynamic Bending Light System Information : Dynamic Bending Light System Information Cksm";
CM_ SG_ 482 LCU_RghtFrntDrlpl12Cmd "Dynamic Bending Light System Information : Dynamic Bending Light System Information Cksm";
CM_ SG_ 482 LCU_RghtFrntDrlpl11Cmd "Dynamic Bending Light System Information : Dynamic Bending Light System Information Cksm";
CM_ SG_ 482 LCU_RghtFrntDrlpl10Cmd "Dynamic Bending Light System Information : Dynamic Bending Light System Information Cksm";
CM_ SG_ 482 LCU_RghtFrntDrlpl09Cmd "Dynamic Bending Light System Information : Dynamic Bending Light System Information Cksm";
CM_ SG_ 487 LCU_RghtFrntDrlpl24Cmd "Dynamic Bending Light System Information : Dynamic Bending Light System Information Cksm";
CM_ SG_ 487 LCU_RghtFrntDrlpl23Cmd "Dynamic Bending Light System Information : Dynamic Bending Light System Information Cksm";
CM_ SG_ 487 LCU_RghtFrntDrlpl22Cmd "Dynamic Bending Light System Information : Dynamic Bending Light System Information Cksm";
CM_ SG_ 487 LCU_RghtFrntDrlpl21Cmd "Dynamic Bending Light System Information : Dynamic Bending Light System Information Cksm";
CM_ SG_ 487 LCU_RghtFrntDrlpl20Cmd "Dynamic Bending Light System Information : Dynamic Bending Light System Information Cksm";
CM_ SG_ 487 LCU_RghtFrntDrlpl19Cmd "Dynamic Bending Light System Information : Dynamic Bending Light System Information Cksm";
CM_ SG_ 487 LCU_RghtFrntDrlpl18Cmd "Dynamic Bending Light System Information : Dynamic Bending Light System Information Cksm";
CM_ SG_ 487 LCU_RghtFrntDrlpl17Cmd "Dynamic Bending Light System Information : Dynamic Bending Light System Information Cksm";
CM_ SG_ 492 LCU_RghtFrntDrlpl32Cmd "Dynamic Bending Light System Information : Dynamic Bending Light System Information Cksm";
CM_ SG_ 492 LCU_RghtFrntDrlpl31Cmd "Dynamic Bending Light System Information : Dynamic Bending Light System Information Cksm";
CM_ SG_ 492 LCU_RghtFrntDrlpl30Cmd "Dynamic Bending Light System Information : Dynamic Bending Light System Information Cksm";
CM_ SG_ 492 LCU_RghtFrntDrlpl29Cmd "Dynamic Bending Light System Information : Dynamic Bending Light System Information Cksm";
CM_ SG_ 492 LCU_RghtFrntDrlpl28Cmd "Dynamic Bending Light System Information : Dynamic Bending Light System Information Cksm";
CM_ SG_ 492 LCU_RghtFrntDrlpl27Cmd "Dynamic Bending Light System Information : Dynamic Bending Light System Information Cksm";
CM_ SG_ 492 LCU_RghtFrntDrlpl26Cmd "Dynamic Bending Light System Information : Dynamic Bending Light System Information Cksm";
CM_ SG_ 492 LCU_RghtFrntDrlpl25Cmd "Dynamic Bending Light System Information : Dynamic Bending Light System Information Cksm";
CM_ SG_ 505 ALS_RghtALSCmdSts "Dynamic Bending Light System Information : Dynamic Bending Light System Information Cksm";
CM_ SG_ 505 LCU_RghtALSPosCmd "Dynamic Bending Light System Information : Dynamic Bending Light System Information Cksm";
CM_ SG_ 505 LCU_LftALSCmdSts "Dynamic Bending Light System Information : Dynamic Bending Light System Information Cksm";
CM_ SG_ 505 LCU_LftALSPosCmd "Dynamic Bending Light System Information : Dynamic Bending Light System Information Cksm";
CM_ SG_ 785 FLLCM_Mtrx7Lst "Dynamic Bending Light System Information : Dynamic Bending Light System Information Cksm";
CM_ SG_ 785 FLLCM_Ntc8Err "Dynamic Bending Light System Information : Dynamic Bending Light System Information Cksm";
CM_ SG_ 785 FLLCM_Ntc7Err "Dynamic Bending Light System Information : Dynamic Bending Light System Information Cksm";
CM_ SG_ 785 FLLCM_Ntc6Err "Dynamic Bending Light System Information : Dynamic Bending Light System Information Cksm";
CM_ SG_ 785 FLLCM_Ntc5Err "Dynamic Bending Light System Information : Dynamic Bending Light System Information Cksm";
CM_ SG_ 785 FLLCM_Ntc4Err "Dynamic Bending Light System Information : Dynamic Bending Light System Information Cksm";
CM_ SG_ 785 FLLCM_Ntc3Err "Dynamic Bending Light System Information : Dynamic Bending Light System Information Cksm";
CM_ SG_ 785 FLLCM_Ntc2Err "Dynamic Bending Light System Information : Dynamic Bending Light System Information Cksm";
CM_ SG_ 785 FLLCM_Ntc1Err "Dynamic Bending Light System Information : Dynamic Bending Light System Information Cksm";
CM_ SG_ 785 FLLCM_Bin8Err "Dynamic Bending Light System Information : Dynamic Bending Light System Information Cksm";
CM_ SG_ 785 FLLCM_Bin7Err "Dynamic Bending Light System Information : Dynamic Bending Light System Information Cksm";
CM_ SG_ 785 FLLCM_Bin6Err "Dynamic Bending Light System Information : Dynamic Bending Light System Information Cksm";
CM_ SG_ 785 FLLCM_Bin5Err "Dynamic Bending Light System Information : Dynamic Bending Light System Information Cksm";
CM_ SG_ 785 FLLCM_Bin4Err "Dynamic Bending Light System Information : Dynamic Bending Light System Information Cksm";
CM_ SG_ 785 FLLCM_Bin3Err "Dynamic Bending Light System Information : Dynamic Bending Light System Information Cksm";
CM_ SG_ 785 FLLCM_Bin2Err "Dynamic Bending Light System Information : Dynamic Bending Light System Information Cksm";
CM_ SG_ 785 FLLCM_Bin1Err "Dynamic Bending Light System Information : Dynamic Bending Light System Information Cksm";
CM_ SG_ 785 FLLCM_Hsd4Err "Dynamic Bending Light System Information : Dynamic Bending Light System Information Cksm";
CM_ SG_ 785 FLLCM_Hsd3Err "Dynamic Bending Light System Information : Dynamic Bending Light System Information Cksm";
CM_ SG_ 785 FLLCM_Hsd2Err "Dynamic Bending Light System Information : Dynamic Bending Light System Information Cksm";
CM_ SG_ 785 FLLCM_Hsd1Err "Dynamic Bending Light System Information : Dynamic Bending Light System Information Cksm";
CM_ SG_ 785 FLLCM_Mtrx7LedErr "Dynamic Bending Light System Information : Dynamic Bending Light System Information Cksm";
CM_ SG_ 785 FLLCM_Mtrx6LedErr "Dynamic Bending Light System Information : Dynamic Bending Light System Information Cksm";
CM_ SG_ 785 FLLCM_Mtrx5LedErr "Dynamic Bending Light System Information : Dynamic Bending Light System Information Cksm";
CM_ SG_ 785 FLLCM_Mtrx3LedErr "Dynamic Bending Light System Information : Dynamic Bending Light System Information Cksm";
CM_ SG_ 785 FLLCM_Mtrx4LedErr "Dynamic Bending Light System Information : Dynamic Bending Light System Information Cksm";
CM_ SG_ 785 FLLCM_Mtrx2LedErr "Dynamic Bending Light System Information : Dynamic Bending Light System Information Cksm";
CM_ SG_ 785 FLLCM_Mtrx1LedErr "Dynamic Bending Light System Information : Dynamic Bending Light System Information Cksm";
CM_ SG_ 785 FLLCM_Mtrx0LedErr "Dynamic Bending Light System Information : Dynamic Bending Light System Information Cksm";
CM_ SG_ 785 FLLCM_Mtrx6Lst "Dynamic Bending Light System Information : Dynamic Bending Light System Information Cksm";
CM_ SG_ 785 FLLCM_Mtrx5Lst "Dynamic Bending Light System Information : Dynamic Bending Light System Information Cksm";
CM_ SG_ 785 FLLCM_Mtrx4Lst "Dynamic Bending Light System Information : Dynamic Bending Light System Information Cksm";
CM_ SG_ 785 FLLCM_Mtrx3Lst "Dynamic Bending Light System Information : Dynamic Bending Light System Information Cksm";
CM_ SG_ 785 FLLCM_Mtrx2Lst "Dynamic Bending Light System Information : Dynamic Bending Light System Information Cksm";
CM_ SG_ 785 FLLCM_Mtrx1Lst "Dynamic Bending Light System Information : Dynamic Bending Light System Information Cksm";
CM_ SG_ 785 FLLCM_Mtrx0Lst "Dynamic Bending Light System Information : Dynamic Bending Light System Information Cksm";
CM_ SG_ 785 FLLCM_Ch8Err "Dynamic Bending Light System Information : Dynamic Bending Light System Information Cksm";
CM_ SG_ 785 FLLCM_Ch7Err "Dynamic Bending Light System Information : Dynamic Bending Light System Information Cksm";
CM_ SG_ 785 FLLCM_Ch6Err "Dynamic Bending Light System Information : Dynamic Bending Light System Information Cksm";
CM_ SG_ 785 FLLCM_Ch5Err "Dynamic Bending Light System Information : Dynamic Bending Light System Information Cksm";
CM_ SG_ 785 FLLCM_Ch4Err "Dynamic Bending Light System Information : Dynamic Bending Light System Information Cksm";
CM_ SG_ 785 FLLCM_Ch3Err "Dynamic Bending Light System Information : Dynamic Bending Light System Information Cksm";
CM_ SG_ 785 FLLCM_Ch2Err "Dynamic Bending Light System Information : Dynamic Bending Light System Information Cksm";
CM_ SG_ 785 FLLCM_Ch1Err "Dynamic Bending Light System Information : Dynamic Bending Light System Information Cksm";
CM_ SG_ 785 FLLCM_MtrInnErr "Dynamic Bending Light System Information : Dynamic Bending Light System Information Cksm";
CM_ SG_ 785 FLLCM_MtrPwrErr "Dynamic Bending Light System Information : Dynamic Bending Light System Information Cksm";
CM_ SG_ 785 FLLCM_LinLst "Dynamic Bending Light System Information : Dynamic Bending Light System Information Cksm";
CM_ SG_ 785 FLLCM_LdoErr "Dynamic Bending Light System Information : Dynamic Bending Light System Information Cksm";
CM_ SG_ 785 FLLCM_LostLCU "Dynamic Bending Light System Information : Dynamic Bending Light System Information Cksm";
CM_ SG_ 785 FLLCM_BusOff "Dynamic Bending Light System Information : Dynamic Bending Light System Information Cksm";
CM_ SG_ 785 FLLCM_Uv "Dynamic Bending Light System Information : Dynamic Bending Light System Information Cksm";
CM_ SG_ 785 FLLCM_Ov "Dynamic Bending Light System Information : Dynamic Bending Light System Information Cksm";
CM_ SG_ 786 SysSts_FLLCMB "Dynamic Bending Light System Information : Dynamic Bending Light System Information Cksm";
CM_ SG_ 787 FRLCM_Ntc8Err "Dynamic Bending Light System Information : Dynamic Bending Light System Information Cksm";
CM_ SG_ 787 FRLCM_Ntc7Err "Dynamic Bending Light System Information : Dynamic Bending Light System Information Cksm";
CM_ SG_ 787 FRLCM_Ntc6Err "Dynamic Bending Light System Information : Dynamic Bending Light System Information Cksm";
CM_ SG_ 787 FRLCM_Ntc5Err "Dynamic Bending Light System Information : Dynamic Bending Light System Information Cksm";
CM_ SG_ 787 FRLCM_Ntc4Err "Dynamic Bending Light System Information : Dynamic Bending Light System Information Cksm";
CM_ SG_ 787 FRLCM_Ntc3Err "Dynamic Bending Light System Information : Dynamic Bending Light System Information Cksm";
CM_ SG_ 787 FRLCM_Ntc2Err "Dynamic Bending Light System Information : Dynamic Bending Light System Information Cksm";
CM_ SG_ 787 FRLCM_Ntc1Err "Dynamic Bending Light System Information : Dynamic Bending Light System Information Cksm";
CM_ SG_ 787 FRLCM_Bin8Err "Dynamic Bending Light System Information : Dynamic Bending Light System Information Cksm";
CM_ SG_ 787 FRLCM_Bin7Err "Dynamic Bending Light System Information : Dynamic Bending Light System Information Cksm";
CM_ SG_ 787 FRLCM_Bin6Err "Dynamic Bending Light System Information : Dynamic Bending Light System Information Cksm";
CM_ SG_ 787 FRLCM_Bin5Err "Dynamic Bending Light System Information : Dynamic Bending Light System Information Cksm";
CM_ SG_ 787 FRLCM_Bin3Err "Dynamic Bending Light System Information : Dynamic Bending Light System Information Cksm";
CM_ SG_ 787 FRLCM_Bin4Err "Dynamic Bending Light System Information : Dynamic Bending Light System Information Cksm";
CM_ SG_ 787 FRLCM_Bin2Err "Dynamic Bending Light System Information : Dynamic Bending Light System Information Cksm";
CM_ SG_ 787 FRLCM_Bin1Err "Dynamic Bending Light System Information : Dynamic Bending Light System Information Cksm";
CM_ SG_ 787 FRLCM_Hsd3Err "Dynamic Bending Light System Information : Dynamic Bending Light System Information Cksm";
CM_ SG_ 787 FRLCM_Hsd2Err "Dynamic Bending Light System Information : Dynamic Bending Light System Information Cksm";
CM_ SG_ 787 FRLCM_Hsd1Err "Dynamic Bending Light System Information : Dynamic Bending Light System Information Cksm";
CM_ SG_ 787 FRLCM_Hsd4Err "Dynamic Bending Light System Information : Dynamic Bending Light System Information Cksm";
CM_ SG_ 787 FRLCM_Mtrx7LedErr "Dynamic Bending Light System Information : Dynamic Bending Light System Information Cksm";
CM_ SG_ 787 FRLCM_Mtrx6LedErr "Dynamic Bending Light System Information : Dynamic Bending Light System Information Cksm";
CM_ SG_ 787 FRLCM_Mtrx5LedErr "Dynamic Bending Light System Information : Dynamic Bending Light System Information Cksm";
CM_ SG_ 787 FRLCM_Mtrx4LedErr "Dynamic Bending Light System Information : Dynamic Bending Light System Information Cksm";
CM_ SG_ 787 FRLCM_Mtrx3LedErr "Dynamic Bending Light System Information : Dynamic Bending Light System Information Cksm";
CM_ SG_ 787 FRLCM_Mtrx2LedErr "Dynamic Bending Light System Information : Dynamic Bending Light System Information Cksm";
CM_ SG_ 787 FRLCM_Mtrx1LedErr "Dynamic Bending Light System Information : Dynamic Bending Light System Information Cksm";
CM_ SG_ 787 FRLCM_Mtrx0LedErr "Dynamic Bending Light System Information : Dynamic Bending Light System Information Cksm";
CM_ SG_ 787 FRLCM_Mtrx7Lst "Dynamic Bending Light System Information : Dynamic Bending Light System Information Cksm";
CM_ SG_ 787 FRLCM_Mtrx6Lst "Dynamic Bending Light System Information : Dynamic Bending Light System Information Cksm";
CM_ SG_ 787 FRLCM_Mtrx5Lst "Dynamic Bending Light System Information : Dynamic Bending Light System Information Cksm";
CM_ SG_ 787 FRLCM_Mtrx4Lst "Dynamic Bending Light System Information : Dynamic Bending Light System Information Cksm";
CM_ SG_ 787 FRLCM_Mtrx3Lst "Dynamic Bending Light System Information : Dynamic Bending Light System Information Cksm";
CM_ SG_ 787 FRLCM_Mtrx2Lst "Dynamic Bending Light System Information : Dynamic Bending Light System Information Cksm";
CM_ SG_ 787 FRLCM_Mtrx1Lst "Dynamic Bending Light System Information : Dynamic Bending Light System Information Cksm";
CM_ SG_ 787 FRLCM_Mtrx0Lst "Dynamic Bending Light System Information : Dynamic Bending Light System Information Cksm";
CM_ SG_ 787 FRLCM_Ch8Err "Dynamic Bending Light System Information : Dynamic Bending Light System Information Cksm";
CM_ SG_ 787 FRLCM_Ch7Err "Dynamic Bending Light System Information : Dynamic Bending Light System Information Cksm";
CM_ SG_ 787 FRLCM_Ch6Err "Dynamic Bending Light System Information : Dynamic Bending Light System Information Cksm";
CM_ SG_ 787 FRLCM_Ch5Err "Dynamic Bending Light System Information : Dynamic Bending Light System Information Cksm";
CM_ SG_ 787 FRLCM_Ch4Err "Dynamic Bending Light System Information : Dynamic Bending Light System Information Cksm";
CM_ SG_ 787 FRLCM_Ch3Err "Dynamic Bending Light System Information : Dynamic Bending Light System Information Cksm";
CM_ SG_ 787 FRLCM_Ch2Err "Dynamic Bending Light System Information : Dynamic Bending Light System Information Cksm";
CM_ SG_ 787 FRLCM_Ch1Err "Dynamic Bending Light System Information : Dynamic Bending Light System Information Cksm";
CM_ SG_ 787 FRLCM_MtrInnErr "Dynamic Bending Light System Information : Dynamic Bending Light System Information Cksm";
CM_ SG_ 787 FRLCM_MtrPwrErr "Dynamic Bending Light System Information : Dynamic Bending Light System Information Cksm";
CM_ SG_ 787 FRLCM_LinLst "Dynamic Bending Light System Information : Dynamic Bending Light System Information Cksm";
CM_ SG_ 787 FRLCM_LdoErr "Dynamic Bending Light System Information : Dynamic Bending Light System Information Cksm";
CM_ SG_ 787 FRLCM_LostLCU "Dynamic Bending Light System Information : Dynamic Bending Light System Information Cksm";
CM_ SG_ 787 FRLCM_BusOff "Dynamic Bending Light System Information : Dynamic Bending Light System Information Cksm";
CM_ SG_ 787 FRLCM_Uv "Dynamic Bending Light System Information : Dynamic Bending Light System Information Cksm";
CM_ SG_ 787 FRLCM_Ov "Dynamic Bending Light System Information : Dynamic Bending Light System Information Cksm";
CM_ SG_ 788 SysSts_FRLCMB "Dynamic Bending Light System Information : Dynamic Bending Light System Information Cksm";
CM_ SG_ 789 SysSts_RLLCMA "Dynamic Bending Light System Information : Dynamic Bending Light System Information Cksm";
CM_ SG_ 791 SysSts_RLLCMB "Dynamic Bending Light System Information : Dynamic Bending Light System Information Cksm";
CM_ SG_ 790 SysSts_RRLCMA "Dynamic Bending Light System Information : Dynamic Bending Light System Information Cksm";
CM_ SG_ 792 SysSts_RRLCMB "Dynamic Bending Light System Information : Dynamic Bending Light System Information Cksm";
BA_DEF_ SG_  "GenSigSendType" ENUM  "NotUsed","OnWrite","OnWriteWithRepetition","OnChange","OnChangeWithRepetition","IfActive","IfActiveWithRepeition","NoSigSendType";
BA_DEF_ SG_  "GenSigSendOnInit" ENUM  "Not Initialized","Application","Handler";
BA_DEF_ SG_  "GenSigStartValue" INT 0 65535;
BA_DEF_ BO_  "GenMsgSendType" ENUM  "Cyclic","NotUsed","NotUsed","NotUsed","NotUsed","NotUsed","NotUsed","NotUsed","NoMsgSendType";
BA_DEF_ BO_  "GenMsgStartDelayTime" INT 0 100000;
BA_DEF_ BO_  "MessageSubnet" ENUM  "BB","PB","CB","Body","HS","Powertrain","Chassis","Spare","PE","CC";
BA_DEF_ BO_  "DiagState" ENUM  "No","Yes";
BA_DEF_ BO_  "DiagResponse" ENUM  "No","Yes";
BA_DEF_ BO_  "DiagRequest" ENUM  "No","Yes";
BA_DEF_ BO_  "GenMsgDelayTime" INT 0 100000;
BA_DEF_ BO_  "GenMsgCycleTime" INT 0 100000;
BA_DEF_ BO_  "GenMsgILSupport" ENUM  "No","Yes";
BA_DEF_ BU_  "NmAsrCanMsgReducedTime" INT 0 65535;
BA_DEF_ BU_  "NmAsrNodeIdentifier" HEX 0 159;
BA_DEF_ BU_  "NmAsrNode" ENUM  "No","Yes";
BA_DEF_ BU_  "SourceId" HEX 0 255;
BA_DEF_ BU_  "ILUsed" ENUM  "No","Yes";
BA_DEF_ BU_  "ECU_Id" HEX 0 255;
BA_DEF_  "NmAsrCanMsgCycleTime" INT 0 65535;
BA_DEF_  "NmAsrRepeatMessageTime" INT 0 65525;
BA_DEF_  "NmAsrWaitBusSleepTime" INT 0 65535;
BA_DEF_  "NmAsrTimeoutTime" INT 0 65535;
BA_DEF_  "NmAsrBaseAddress" HEX 0 2032;
BA_DEF_  "NmAsrMessageCount" INT 0 256;
BA_DEF_  "BusType" STRING ;
BA_DEF_  "SyncJumpWidthMax" INT 0 255;
BA_DEF_  "SyncJumpWidthMin" INT 0 255;
BA_DEF_  "SamplePointMax" FLOAT 0 100;
BA_DEF_  "SamplePointMin" FLOAT 0 100;
BA_DEF_  "Manufacturer" STRING ;
BA_DEF_  "BusOffRecoveryTime" INT 0 65535;
BA_DEF_  "Baudrate" INT 0 1000000;
BA_DEF_  "NmType" STRING ;
BA_DEF_  "DBName" STRING ;
BA_DEF_REL_ BU_SG_REL_  "GenSigSuprvResp" ENUM  "None","Notify App","Substitute Default";
BA_DEF_REL_ BU_SG_REL_  "GenSigTimeoutTime" INT 0 15000;
BA_DEF_DEF_  "GenSigSendType" "NoSigSendType";
BA_DEF_DEF_  "GenSigSendOnInit" "Not Initialized";
BA_DEF_DEF_  "GenSigStartValue" 0;
BA_DEF_DEF_  "GenMsgSendType" "NoMsgSendType";
BA_DEF_DEF_  "GenMsgStartDelayTime" 0;
BA_DEF_DEF_  "MessageSubnet" "Body";
BA_DEF_DEF_  "DiagState" "No";
BA_DEF_DEF_  "DiagResponse" "No";
BA_DEF_DEF_  "DiagRequest" "No";
BA_DEF_DEF_  "GenMsgDelayTime" 0;
BA_DEF_DEF_  "GenMsgCycleTime" 0;
BA_DEF_DEF_  "GenMsgILSupport" "Yes";
BA_DEF_DEF_  "NmAsrCanMsgReducedTime" 0;
BA_DEF_DEF_  "NmAsrNodeIdentifier" 0;
BA_DEF_DEF_  "NmAsrNode" "Yes";
BA_DEF_DEF_  "SourceId" 0;
BA_DEF_DEF_  "ILUsed" "Yes";
BA_DEF_DEF_  "ECU_Id" 0;
BA_DEF_DEF_  "NmAsrCanMsgCycleTime" 1000;
BA_DEF_DEF_  "NmAsrRepeatMessageTime" 400;
BA_DEF_DEF_  "NmAsrWaitBusSleepTime" 750;
BA_DEF_DEF_  "NmAsrTimeoutTime" 1500;
BA_DEF_DEF_  "NmAsrBaseAddress" 0;
BA_DEF_DEF_  "NmAsrMessageCount" 16;
BA_DEF_DEF_  "BusType" "CAN";
BA_DEF_DEF_  "SyncJumpWidthMax" 3;
BA_DEF_DEF_  "SyncJumpWidthMin" 4;
BA_DEF_DEF_  "SamplePointMax" 80;
BA_DEF_DEF_  "SamplePointMin" 81.25;
BA_DEF_DEF_  "Manufacturer" "GM";
BA_DEF_DEF_  "BusOffRecoveryTime" 160;
BA_DEF_DEF_  "Baudrate" 500000;
BA_DEF_DEF_  "NmType" "NmAsr";
BA_DEF_DEF_  "DBName" "SubCAN";
BA_DEF_DEF_REL_ "GenSigSuprvResp" "None";
BA_DEF_DEF_REL_ "GenSigTimeoutTime" 0;
BA_ "BusOffRecoveryTime" 200;
BA_ "NmAsrTimeoutTime" 1000;
BA_ "NmAsrWaitBusSleepTime" 5000;
BA_ "NmAsrCanMsgCycleTime" 200;
BA_ "NmAsrBaseAddress" 1312;
BA_ "DBName" "PB";
BA_ "NmAsrNodeIdentifier" BU_ LftFrntLCMA 1;
BA_ "NmAsrCanMsgReducedTime" BU_ LftFrntLCMA 500;
BA_ "SourceId" BU_ RghtFrntLCMA 1;
BA_ "ECU_Id" BU_ RghtFrntLCMA 1;
BA_ "GenMsgCycleTime" BO_ 490 500;
BA_ "MessageSubnet" BO_ 490 1;
BA_ "GenMsgStartDelayTime" BO_ 490 10;
BA_ "GenMsgSendType" BO_ 490 0;
BA_ "GenMsgSendType" BO_ 1396 0;
BA_ "GenMsgStartDelayTime" BO_ 1396 10;
BA_ "MessageSubnet" BO_ 1396 1;
BA_ "GenMsgCycleTime" BO_ 1396 100;
BA_ "GenMsgSendType" BO_ 1371 0;
BA_ "GenMsgStartDelayTime" BO_ 1371 10;
BA_ "MessageSubnet" BO_ 1371 1;
BA_ "GenMsgCycleTime" BO_ 1371 100;
BA_ "GenMsgSendType" BO_ 1358 0;
BA_ "GenMsgStartDelayTime" BO_ 1358 10;
BA_ "MessageSubnet" BO_ 1358 1;
BA_ "GenMsgCycleTime" BO_ 1358 100;
BA_ "GenMsgSendType" BO_ 1330 0;
BA_ "GenMsgStartDelayTime" BO_ 1330 10;
BA_ "MessageSubnet" BO_ 1330 1;
BA_ "GenMsgCycleTime" BO_ 1330 100;
BA_ "GenMsgSendType" BO_ 1313 0;
BA_ "GenMsgStartDelayTime" BO_ 1313 10;
BA_ "MessageSubnet" BO_ 1313 1;
BA_ "GenMsgCycleTime" BO_ 1313 100;
BA_ "GenMsgSendType" BO_ 1359 0;
BA_ "GenMsgStartDelayTime" BO_ 1359 10;
BA_ "MessageSubnet" BO_ 1359 1;
BA_ "GenMsgCycleTime" BO_ 1359 100;
BA_ "GenMsgCycleTime" BO_ 776 100;
BA_ "MessageSubnet" BO_ 776 1;
BA_ "GenMsgStartDelayTime" BO_ 776 10;
BA_ "GenMsgSendType" BO_ 776 0;
BA_ "GenMsgCycleTime" BO_ 774 100;
BA_ "MessageSubnet" BO_ 774 1;
BA_ "GenMsgStartDelayTime" BO_ 774 10;
BA_ "GenMsgSendType" BO_ 774 0;
BA_ "GenMsgCycleTime" BO_ 775 100;
BA_ "MessageSubnet" BO_ 775 1;
BA_ "GenMsgStartDelayTime" BO_ 775 10;
BA_ "GenMsgSendType" BO_ 775 0;
BA_ "GenMsgCycleTime" BO_ 773 100;
BA_ "MessageSubnet" BO_ 773 1;
BA_ "GenMsgStartDelayTime" BO_ 773 10;
BA_ "GenMsgSendType" BO_ 773 0;
BA_ "GenMsgCycleTime" BO_ 772 100;
BA_ "MessageSubnet" BO_ 772 1;
BA_ "GenMsgStartDelayTime" BO_ 772 10;
BA_ "GenMsgSendType" BO_ 772 0;
BA_ "GenMsgCycleTime" BO_ 771 100;
BA_ "MessageSubnet" BO_ 771 1;
BA_ "GenMsgStartDelayTime" BO_ 771 10;
BA_ "GenMsgSendType" BO_ 771 0;
BA_ "GenMsgCycleTime" BO_ 770 100;
BA_ "MessageSubnet" BO_ 770 1;
BA_ "GenMsgStartDelayTime" BO_ 770 10;
BA_ "GenMsgSendType" BO_ 770 0;
BA_ "GenMsgCycleTime" BO_ 769 100;
BA_ "MessageSubnet" BO_ 769 1;
BA_ "GenMsgStartDelayTime" BO_ 769 10;
BA_ "GenMsgSendType" BO_ 769 0;
BA_ "GenMsgCycleTime" BO_ 489 20;
BA_ "MessageSubnet" BO_ 489 1;
BA_ "GenMsgSendType" BO_ 489 0;
BA_ "DiagResponse" BO_ 1916 1;
BA_ "MessageSubnet" BO_ 1916 1;
BA_ "DiagResponse" BO_ 2011 1;
BA_ "MessageSubnet" BO_ 2011 1;
BA_ "DiagResponse" BO_ 1998 1;
BA_ "MessageSubnet" BO_ 1998 1;
BA_ "DiagRequest" BO_ 1908 1;
BA_ "MessageSubnet" BO_ 1908 1;
BA_ "DiagRequest" BO_ 1883 1;
BA_ "MessageSubnet" BO_ 1883 1;
BA_ "DiagRequest" BO_ 1870 1;
BA_ "MessageSubnet" BO_ 1870 1;
BA_ "GenMsgCycleTime" BO_ 481 20;
BA_ "MessageSubnet" BO_ 481 1;
BA_ "GenMsgSendType" BO_ 481 0;
BA_ "GenMsgCycleTime" BO_ 486 20;
BA_ "MessageSubnet" BO_ 486 1;
BA_ "GenMsgSendType" BO_ 486 0;
BA_ "GenMsgSendType" BO_ 485 0;
BA_ "MessageSubnet" BO_ 485 1;
BA_ "GenMsgCycleTime" BO_ 485 20;
BA_ "GenMsgSendType" BO_ 469 0;
BA_ "MessageSubnet" BO_ 469 1;
BA_ "GenMsgCycleTime" BO_ 469 20;
BA_ "GenMsgSendType" BO_ 464 0;
BA_ "MessageSubnet" BO_ 464 1;
BA_ "GenMsgCycleTime" BO_ 464 20;
BA_ "GenMsgSendType" BO_ 458 0;
BA_ "MessageSubnet" BO_ 458 1;
BA_ "GenMsgCycleTime" BO_ 458 20;
BA_ "GenMsgSendType" BO_ 495 0;
BA_ "MessageSubnet" BO_ 495 1;
BA_ "GenMsgCycleTime" BO_ 495 20;
BA_ "GenMsgSendType" BO_ 491 0;
BA_ "MessageSubnet" BO_ 491 1;
BA_ "GenMsgCycleTime" BO_ 491 20;
BA_ "GenMsgSendType" BO_ 484 0;
BA_ "MessageSubnet" BO_ 484 1;
BA_ "GenMsgCycleTime" BO_ 484 20;
BA_ "GenMsgSendType" BO_ 479 0;
BA_ "MessageSubnet" BO_ 479 1;
BA_ "GenMsgCycleTime" BO_ 479 20;
BA_ "GenMsgSendType" BO_ 498 0;
BA_ "MessageSubnet" BO_ 498 1;
BA_ "GenMsgCycleTime" BO_ 498 20;
BA_ "GenMsgSendType" BO_ 494 0;
BA_ "MessageSubnet" BO_ 494 1;
BA_ "GenMsgCycleTime" BO_ 494 20;
BA_ "GenMsgSendType" BO_ 480 0;
BA_ "MessageSubnet" BO_ 480 1;
BA_ "GenMsgCycleTime" BO_ 480 20;
BA_ "GenMsgSendType" BO_ 474 0;
BA_ "MessageSubnet" BO_ 474 1;
BA_ "GenMsgCycleTime" BO_ 474 20;
BA_ "GenMsgCycleTime" BO_ 503 20;
BA_ "MessageSubnet" BO_ 503 1;
BA_ "GenMsgSendType" BO_ 503 0;
BA_ "GenMsgCycleTime" BO_ 501 20;
BA_ "MessageSubnet" BO_ 501 1;
BA_ "GenMsgSendType" BO_ 501 0;
BA_ "GenMsgCycleTime" BO_ 499 20;
BA_ "MessageSubnet" BO_ 499 1;
BA_ "GenMsgSendType" BO_ 499 0;
BA_ "GenMsgCycleTime" BO_ 496 20;
BA_ "MessageSubnet" BO_ 496 1;
BA_ "GenMsgSendType" BO_ 496 0;
BA_ "GenMsgCycleTime" BO_ 504 20;
BA_ "MessageSubnet" BO_ 504 1;
BA_ "GenMsgSendType" BO_ 504 0;
BA_ "GenMsgCycleTime" BO_ 502 20;
BA_ "MessageSubnet" BO_ 502 1;
BA_ "GenMsgSendType" BO_ 502 0;
BA_ "GenMsgCycleTime" BO_ 500 20;
BA_ "MessageSubnet" BO_ 500 1;
BA_ "GenMsgSendType" BO_ 500 0;
BA_ "GenMsgCycleTime" BO_ 497 20;
BA_ "MessageSubnet" BO_ 497 1;
BA_ "GenMsgSendType" BO_ 497 0;
BA_ "GenMsgCycleTime" BO_ 475 20;
BA_ "MessageSubnet" BO_ 475 1;
BA_ "GenMsgSendType" BO_ 475 0;
BA_ "GenMsgCycleTime" BO_ 470 20;
BA_ "MessageSubnet" BO_ 470 1;
BA_ "GenMsgSendType" BO_ 470 0;
BA_ "GenMsgCycleTime" BO_ 465 20;
BA_ "MessageSubnet" BO_ 465 1;
BA_ "GenMsgSendType" BO_ 465 0;
BA_ "GenMsgCycleTime" BO_ 476 20;
BA_ "MessageSubnet" BO_ 476 1;
BA_ "GenMsgSendType" BO_ 476 0;
BA_ "GenMsgCycleTime" BO_ 471 20;
BA_ "MessageSubnet" BO_ 471 1;
BA_ "GenMsgSendType" BO_ 471 0;
BA_ "GenMsgCycleTime" BO_ 466 20;
BA_ "MessageSubnet" BO_ 466 1;
BA_ "GenMsgSendType" BO_ 466 0;
BA_ "DiagResponse" BO_ 1970 1;
BA_ "MessageSubnet" BO_ 1970 1;
BA_ "DiagRequest" BO_ 1842 1;
BA_ "MessageSubnet" BO_ 1842 1;
BA_ "DiagState" BO_ 2015 1;
BA_ "MessageSubnet" BO_ 2015 1;
BA_ "DiagRequest" BO_ 1825 1;
BA_ "MessageSubnet" BO_ 1825 1;
BA_ "DiagResponse" BO_ 1953 1;
BA_ "MessageSubnet" BO_ 1953 1;
BA_ "GenMsgCycleTime" BO_ 2161836032 5000;
BA_ "MessageSubnet" BO_ 2161836032 1;
BA_ "GenMsgSendType" BO_ 457 0;
BA_ "GenMsgCycleTime" BO_ 457 20;
BA_ "MessageSubnet" BO_ 457 1;
BA_ "GenMsgSendType" BO_ 456 0;
BA_ "GenMsgCycleTime" BO_ 456 20;
BA_ "MessageSubnet" BO_ 456 1;
BA_ "GenMsgSendType" BO_ 463 0;
BA_ "GenMsgCycleTime" BO_ 463 20;
BA_ "MessageSubnet" BO_ 463 1;
BA_ "GenMsgSendType" BO_ 468 0;
BA_ "GenMsgCycleTime" BO_ 468 20;
BA_ "MessageSubnet" BO_ 468 1;
BA_ "GenMsgSendType" BO_ 462 0;
BA_ "GenMsgCycleTime" BO_ 462 20;
BA_ "MessageSubnet" BO_ 462 1;
BA_ "GenMsgSendType" BO_ 467 0;
BA_ "GenMsgCycleTime" BO_ 467 20;
BA_ "MessageSubnet" BO_ 467 1;
BA_ "GenMsgSendType" BO_ 473 0;
BA_ "GenMsgCycleTime" BO_ 473 20;
BA_ "MessageSubnet" BO_ 473 1;
BA_ "GenMsgSendType" BO_ 472 0;
BA_ "GenMsgCycleTime" BO_ 472 20;
BA_ "MessageSubnet" BO_ 472 1;
BA_ "GenMsgSendType" BO_ 461 0;
BA_ "GenMsgCycleTime" BO_ 461 20;
BA_ "MessageSubnet" BO_ 461 1;
BA_ "GenMsgSendType" BO_ 459 0;
BA_ "GenMsgCycleTime" BO_ 459 20;
BA_ "MessageSubnet" BO_ 459 1;
BA_ "GenMsgSendType" BO_ 478 0;
BA_ "GenMsgCycleTime" BO_ 478 20;
BA_ "MessageSubnet" BO_ 478 1;
BA_ "GenMsgSendType" BO_ 483 0;
BA_ "GenMsgCycleTime" BO_ 483 20;
BA_ "MessageSubnet" BO_ 483 1;
BA_ "GenMsgSendType" BO_ 488 0;
BA_ "GenMsgCycleTime" BO_ 488 20;
BA_ "MessageSubnet" BO_ 488 1;
BA_ "GenMsgSendType" BO_ 493 0;
BA_ "GenMsgCycleTime" BO_ 493 20;
BA_ "MessageSubnet" BO_ 493 1;
BA_ "GenMsgSendType" BO_ 477 0;
BA_ "GenMsgCycleTime" BO_ 477 20;
BA_ "MessageSubnet" BO_ 477 1;
BA_ "GenMsgSendType" BO_ 482 0;
BA_ "GenMsgCycleTime" BO_ 482 20;
BA_ "MessageSubnet" BO_ 482 1;
BA_ "GenMsgSendType" BO_ 487 0;
BA_ "GenMsgCycleTime" BO_ 487 20;
BA_ "MessageSubnet" BO_ 487 1;
BA_ "GenMsgSendType" BO_ 492 0;
BA_ "GenMsgCycleTime" BO_ 492 20;
BA_ "MessageSubnet" BO_ 492 1;
BA_ "GenMsgSendType" BO_ 505 0;
BA_ "GenMsgCycleTime" BO_ 505 20;
BA_ "MessageSubnet" BO_ 505 1;
BA_ "GenMsgStartDelayTime" BO_ 785 10;
BA_ "GenMsgCycleTime" BO_ 785 100;
BA_ "GenMsgSendType" BO_ 785 0;
BA_ "MessageSubnet" BO_ 785 1;
BA_ "GenMsgStartDelayTime" BO_ 786 10;
BA_ "GenMsgSendType" BO_ 786 0;
BA_ "GenMsgCycleTime" BO_ 786 100;
BA_ "MessageSubnet" BO_ 786 1;
BA_ "GenMsgStartDelayTime" BO_ 787 10;
BA_ "GenMsgCycleTime" BO_ 787 100;
BA_ "GenMsgSendType" BO_ 787 0;
BA_ "MessageSubnet" BO_ 787 1;
BA_ "GenMsgStartDelayTime" BO_ 788 10;
BA_ "GenMsgSendType" BO_ 788 0;
BA_ "GenMsgCycleTime" BO_ 788 100;
BA_ "MessageSubnet" BO_ 788 1;
BA_ "GenMsgStartDelayTime" BO_ 789 20;
BA_ "GenMsgCycleTime" BO_ 789 100;
BA_ "GenMsgSendType" BO_ 789 0;
BA_ "MessageSubnet" BO_ 789 1;
BA_ "GenMsgStartDelayTime" BO_ 791 20;
BA_ "GenMsgSendType" BO_ 791 0;
BA_ "GenMsgCycleTime" BO_ 791 100;
BA_ "MessageSubnet" BO_ 791 1;
BA_ "GenMsgStartDelayTime" BO_ 790 20;
BA_ "GenMsgCycleTime" BO_ 790 100;
BA_ "GenMsgSendType" BO_ 790 0;
BA_ "MessageSubnet" BO_ 790 1;
BA_ "GenMsgStartDelayTime" BO_ 792 20;
BA_ "GenMsgSendType" BO_ 792 0;
BA_ "GenMsgCycleTime" BO_ 792 100;
BA_ "MessageSubnet" BO_ 792 1;
BA_ "GenSigStartValue" SG_ 490 LCU_ACU_Time_Year 21;
BA_ "GenSigStartValue" SG_ 490 LCU_ACU_Time_Month 1;
BA_ "GenSigStartValue" SG_ 490 LCU_ACU_Time_Day 1;
BA_REL_ "GenSigTimeoutTime" BU_SG_REL_ RghtRrLCMB SG_ 490 LCU_ACU_Time_Year 2500;
BA_REL_ "GenSigTimeoutTime" BU_SG_REL_ RghtRrLCMA SG_ 490 LCU_ACU_Time_Year 2500;
BA_REL_ "GenSigTimeoutTime" BU_SG_REL_ LftRrLCMA SG_ 490 LCU_ACU_Time_Year 2500;
BA_REL_ "GenSigTimeoutTime" BU_SG_REL_ RghtFrntLCMA SG_ 490 LCU_ACU_Time_Year 2500;
BA_REL_ "GenSigTimeoutTime" BU_SG_REL_ RghtFrntLCMB SG_ 490 LCU_ACU_Time_Year 2500;
BA_REL_ "GenSigTimeoutTime" BU_SG_REL_ LftRrLCMB SG_ 490 LCU_ACU_Time_Year 2500;
BA_REL_ "GenSigTimeoutTime" BU_SG_REL_ LftFrntLCMB SG_ 490 LCU_ACU_Time_Year 250;
BA_REL_ "GenSigTimeoutTime" BU_SG_REL_ LftFrntLCMA SG_ 490 LCU_ACU_Time_Year 2500;
BA_REL_ "GenSigTimeoutTime" BU_SG_REL_ RghtRrLCMA SG_ 1359 NMData_LCU 1000;
BA_REL_ "GenSigTimeoutTime" BU_SG_REL_ RghtFrntLCMB SG_ 1359 NMData_LCU 1000;
BA_REL_ "GenSigTimeoutTime" BU_SG_REL_ LftRrLCMB SG_ 1359 NMData_LCU 1000;
BA_REL_ "GenSigTimeoutTime" BU_SG_REL_ LftRrLCMA SG_ 1359 NMData_LCU 1000;
BA_REL_ "GenSigTimeoutTime" BU_SG_REL_ LftFrntLCMB SG_ 1359 NMData_LCU 1000;
BA_REL_ "GenSigTimeoutTime" BU_SG_REL_ RghtFrntLCMA SG_ 1359 NMData_LCU 1000;
BA_REL_ "GenSigTimeoutTime" BU_SG_REL_ LftFrntLCMA SG_ 1359 NMData_LCU 1000;
BA_REL_ "GenSigTimeoutTime" BU_SG_REL_ LftRrLCMA SG_ 481 LftRPlLed001 250;
BA_REL_ "GenSigTimeoutTime" BU_SG_REL_ LftRrLCMA SG_ 486 LftRPlLed009 250;
BA_REL_ "GenSigTimeoutTime" BU_SG_REL_ RghtRrLCMA SG_ 485 RghtRPlLed009 250;
BA_REL_ "GenSigTimeoutTime" BU_SG_REL_ LftRrLCMB SG_ 469 LftRCPlLed017 250;
BA_REL_ "GenSigTimeoutTime" BU_SG_REL_ LftRrLCMB SG_ 464 LftRCPlLed009 250;
BA_REL_ "GenSigTimeoutTime" BU_SG_REL_ LftRrLCMB SG_ 458 LftRCPlLed001 250;
BA_REL_ "GenSigTimeoutTime" BU_SG_REL_ LftRrLCMA SG_ 495 LftRPlLed025 250;
BA_REL_ "GenSigTimeoutTime" BU_SG_REL_ LftRrLCMA SG_ 491 LftRPlLed017 250;
BA_REL_ "GenSigTimeoutTime" BU_SG_REL_ LftRrLCMB SG_ 484 LftRCPlLed041 250;
BA_REL_ "GenSigTimeoutTime" BU_SG_REL_ LftRrLCMB SG_ 479 LftRCPlLed033 250;
BA_REL_ "GenSigTimeoutTime" BU_SG_REL_ RghtRrLCMA SG_ 498 RghtRPlLed025 250;
BA_REL_ "GenSigTimeoutTime" BU_SG_REL_ RghtRrLCMA SG_ 494 RghtRPlLed017 250;
BA_REL_ "GenSigTimeoutTime" BU_SG_REL_ RghtRrLCMA SG_ 480 RghtRPlLed001 250;
BA_REL_ "GenSigTimeoutTime" BU_SG_REL_ LftRrLCMB SG_ 474 LftRCPlLed025 250;
BA_REL_ "GenSigTimeoutTime" BU_SG_REL_ RghtFrntLCMA SG_ 503 LCU_RghtFrntDrlpl57Cmd 250;
BA_REL_ "GenSigTimeoutTime" BU_SG_REL_ RghtFrntLCMA SG_ 501 LCU_RghtFrntDrlpl49Cmd 250;
BA_REL_ "GenSigTimeoutTime" BU_SG_REL_ RghtFrntLCMA SG_ 499 LCU_RghtFrntDrlpl41Cmd 250;
BA_REL_ "GenSigTimeoutTime" BU_SG_REL_ RghtFrntLCMA SG_ 496 LCU_RghtFrntDrlpl33Cmd 250;
BA_REL_ "GenSigTimeoutTime" BU_SG_REL_ LftFrntLCMA SG_ 504 LCU_LftFrntDrlPl57Cmd 250;
BA_REL_ "GenSigTimeoutTime" BU_SG_REL_ LftFrntLCMA SG_ 502 LCU_LftFrntDrlPl49Cmd 250;
BA_REL_ "GenSigTimeoutTime" BU_SG_REL_ LftFrntLCMA SG_ 500 LCU_LftFrntDrlPl41Cmd 250;
BA_REL_ "GenSigTimeoutTime" BU_SG_REL_ LftFrntLCMA SG_ 497 LCU_LftFrntDrlPl33Cmd 250;
BA_REL_ "GenSigTimeoutTime" BU_SG_REL_ RghtRrLCMA SG_ 475 RghtRTrnLed025 250;
BA_REL_ "GenSigTimeoutTime" BU_SG_REL_ RghtRrLCMA SG_ 470 RghtRTrnLed017 250;
BA_REL_ "GenSigTimeoutTime" BU_SG_REL_ RghtRrLCMA SG_ 465 RghtRTrnLed009 250;
BA_REL_ "GenSigTimeoutTime" BU_SG_REL_ LftRrLCMA SG_ 476 LftRTrnLed025 250;
BA_REL_ "GenSigTimeoutTime" BU_SG_REL_ LftRrLCMA SG_ 471 LftRTrnLed017 250;
BA_REL_ "GenSigTimeoutTime" BU_SG_REL_ LftRrLCMA SG_ 466 LftRTrnLed009 250;
BA_REL_ "GenSigTimeoutTime" BU_SG_REL_ LftFrntLCMA SG_ 457 LCU_LftLb01Cmd 250;
BA_REL_ "GenSigTimeoutTime" BU_SG_REL_ RghtFrntLCMA SG_ 456 LCU_RghtLb01Cmd 250;
BA_REL_ "GenSigTimeoutTime" BU_SG_REL_ LftFrntLCMA SG_ 463 LCU_LftHb02Cmd 250;
BA_REL_ "GenSigTimeoutTime" BU_SG_REL_ LftFrntLCMA SG_ 468 LCU_LftHb09Cmd 250;
BA_REL_ "GenSigTimeoutTime" BU_SG_REL_ RghtFrntLCMA SG_ 462 LCU_RghtHb01Cmd 250;
BA_REL_ "GenSigTimeoutTime" BU_SG_REL_ RghtFrntLCMA SG_ 467 LCU_RghtHb09Cmd 250;
BA_REL_ "GenSigTimeoutTime" BU_SG_REL_ LftFrntLCMA SG_ 473 LCU_LftFrntTL01Cmd 250;
BA_REL_ "GenSigTimeoutTime" BU_SG_REL_ RghtFrntLCMA SG_ 472 LCU_RghtFrntTL01Cmd 250;
BA_REL_ "GenSigTimeoutTime" BU_SG_REL_ LftRrLCMA SG_ 461 LftRTrnLed001 250;
BA_REL_ "GenSigTimeoutTime" BU_SG_REL_ RghtRrLCMA SG_ 459 RghtRTrnLed001 250;
BA_REL_ "GenSigTimeoutTime" BU_SG_REL_ LftFrntLCMA SG_ 478 LCU_LftFrntDrlPl01Cmd 250;
BA_REL_ "GenSigTimeoutTime" BU_SG_REL_ LftFrntLCMA SG_ 483 LCU_LftFrntDrlPl09Cmd 250;
BA_REL_ "GenSigTimeoutTime" BU_SG_REL_ LftFrntLCMA SG_ 488 LCU_LftFrntDrlPl17Cmd 250;
BA_REL_ "GenSigTimeoutTime" BU_SG_REL_ LftFrntLCMA SG_ 493 LCU_LftFrntDrlPl25Cmd 250;
BA_REL_ "GenSigTimeoutTime" BU_SG_REL_ RghtFrntLCMA SG_ 477 LCU_RghtFrntDrlpl01Cmd 250;
BA_REL_ "GenSigTimeoutTime" BU_SG_REL_ RghtFrntLCMA SG_ 482 LCU_RghtFrntDrlpl09Cmd 250;
BA_REL_ "GenSigTimeoutTime" BU_SG_REL_ RghtFrntLCMA SG_ 487 LCU_RghtFrntDrlpl17Cmd 250;
BA_REL_ "GenSigTimeoutTime" BU_SG_REL_ RghtFrntLCMA SG_ 492 LCU_RghtFrntDrlpl25Cmd 250;
BA_REL_ "GenSigTimeoutTime" BU_SG_REL_ RghtFrntLCMA SG_ 505 LCU_RghtALSPosCmd 250;
BA_REL_ "GenSigTimeoutTime" BU_SG_REL_ LftFrntLCMA SG_ 505 LCU_LftALSCmdSts 250;
VAL_ 489 LCU_WelShwSts 2 "welcome mode 2" 1 "welcome mode 1" 0 "no show" ;
VAL_ 489 LCU_LightShwSts 3 "light show mode 3" 2 "light show mode 2" 1 "light show mode 1" 0 "no show" ;
VAL_ 505 ALS_RghtALSCmdSts 2 "normal run" 1 "referece run" 0 "invalid" ;
VAL_ 505 LCU_RghtALSPosCmd 2 "normal run" 1 "referece run" 0 "invalid" ;
VAL_ 505 LCU_LftALSCmdSts 2 "normal run" 1 "referece run" 0 "invalid" ;
